VERSION ""

NS_ :

BS_:

BU_:

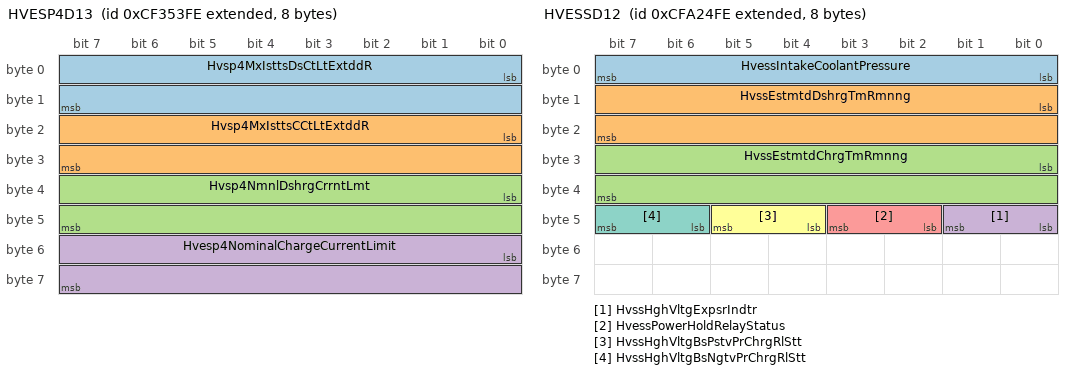
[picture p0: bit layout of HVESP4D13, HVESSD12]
BO_ 2364756990 HVESP4D13: 8 Vector__XXX
 SG_ Hvsp4MxIsttsDsCtLtExtddR : 0|16@1+ (0.125,-4000) [-4000|0] "A" Vector__XXX
 SG_ Hvsp4MxIsttsCCtLtExtddR : 16|16@1+ (0.125,-4000) [0|4031.875] "A" Vector__XXX
 SG_ Hvsp4NmnlDshrgCrrntLmt : 32|16@1+ (0.125,-4000) [-4000|0] "A" Vector__XXX
 SG_ Hvesp4NominalChargeCurrentLimit : 48|16@1+ (0.125,-4000) [0|4031.875] "A" Vector__XXX

BO_ 2364757246 HVESP5D12: 8 Vector__XXX
 SG_ Hvsp5AvllDshrgPwrExtnddRng : 0|16@1+ (0.25,0) [0|16063.75] "kW" Vector__XXX
 SG_ Hvsp5AvllChrgPwrExtnddRng : 16|16@1+ (0.25,0) [0|16063.75] "kW" Vector__XXX
 SG_ Hvesp5VoltageLevelExtendedRange : 32|16@1+ (0.125,0) [0|8031.875] "V" Vector__XXX
 SG_ Hvesp5CurrentExtendedRange : 48|16@1+ (0.125,-4000) [-4000|4031.875] "A" Vector__XXX

BO_ 2364757502 HVESP5D13: 8 Vector__XXX
 SG_ Hvsp5MxIsttsDsCtLtExtddR : 0|16@1+ (0.125,-4000) [-4000|0] "A" Vector__XXX
 SG_ Hvsp5MxIsttsCCtLtExtddR : 16|16@1+ (0.125,-4000) [0|4031.875] "A" Vector__XXX
 SG_ Hvsp5NmnlDshrgCrrntLmt : 32|16@1+ (0.125,-4000) [-4000|0] "A" Vector__XXX
 SG_ Hvesp5NominalChargeCurrentLimit : 48|16@1+ (0.125,-4000) [0|4031.875] "A" Vector__XXX

BO_ 2364757758 HVESP6D12: 8 Vector__XXX
 SG_ Hvsp6AvllDshrgPwrExtnddRng : 0|16@1+ (0.25,0) [0|16063.75] "kW" Vector__XXX
 SG_ Hvsp6AvllChrgPwrExtnddRng : 16|16@1+ (0.25,0) [0|16063.75] "kW" Vector__XXX
 SG_ Hvesp6VoltageLevelExtendedRange : 32|16@1+ (0.125,0) [0|8031.875] "V" Vector__XXX
 SG_ Hvesp6CurrentExtendedRange : 48|16@1+ (0.125,-4000) [-4000|4031.875] "A" Vector__XXX

BO_ 2364758014 HVESP6D13: 8 Vector__XXX
 SG_ Hvsp6MxIsttsDsCtLtExtddR : 0|16@1+ (0.125,-4000) [-4000|0] "A" Vector__XXX
 SG_ Hvsp6MxIsttsCCtLtExtddR : 16|16@1+ (0.125,-4000) [0|4031.875] "A" Vector__XXX
 SG_ Hvsp6NmnlDshrgCrrntLmt : 32|16@1+ (0.125,-4000) [-4000|0] "A" Vector__XXX
 SG_ Hvesp6NominalChargeCurrentLimit : 48|16@1+ (0.125,-4000) [0|4031.875] "A" Vector__XXX

BO_ 2364758270 HVESP7D12: 8 Vector__XXX
 SG_ Hvsp7AvllDshrgPwrExtnddRng : 0|16@1+ (0.25,0) [0|16063.75] "kW" Vector__XXX
 SG_ Hvsp7AvllChrgPwrExtnddRng : 16|16@1+ (0.25,0) [0|16063.75] "kW" Vector__XXX
 SG_ Hvesp7VoltageLevelExtendedRange : 32|16@1+ (0.125,0) [0|8031.875] "V" Vector__XXX
 SG_ Hvesp7CurrentExtendedRange : 48|16@1+ (0.125,-4000) [-4000|4031.875] "A" Vector__XXX

BO_ 2364758526 HVESP7D13: 8 Vector__XXX
 SG_ Hvsp7MxIsttsDsCtLtExtddR : 0|16@1+ (0.125,-4000) [-4000|0] "A" Vector__XXX
 SG_ Hvsp7MxIsttsCCtLtExtddR : 16|16@1+ (0.125,-4000) [0|4031.875] "A" Vector__XXX
 SG_ Hvsp7NmnlDshrgCrrntLmt : 32|16@1+ (0.125,-4000) [-4000|0] "A" Vector__XXX
 SG_ Hvesp7NominalChargeCurrentLimit : 48|16@1+ (0.125,-4000) [0|4031.875] "A" Vector__XXX

BO_ 2364758782 HVESP8D12: 8 Vector__XXX
 SG_ Hvsp8AvllDshrgPwrExtnddRng : 0|16@1+ (0.25,0) [0|16063.75] "kW" Vector__XXX
 SG_ Hvsp8AvllChrgPwrExtnddRng : 16|16@1+ (0.25,0) [0|16063.75] "kW" Vector__XXX
 SG_ Hvesp8VoltageLevelExtendedRange : 32|16@1+ (0.125,0) [0|8031.875] "V" Vector__XXX
 SG_ Hvesp8CurrentExtendedRange : 48|16@1+ (0.125,-4000) [-4000|4031.875] "A" Vector__XXX

BO_ 2364759038 HVESP8D13: 8 Vector__XXX
 SG_ Hvsp8MxIsttsDsCtLtExtddR : 0|16@1+ (0.125,-4000) [-4000|0] "A" Vector__XXX
 SG_ Hvsp8MxIsttsCCtLtExtddR : 16|16@1+ (0.125,-4000) [0|4031.875] "A" Vector__XXX
 SG_ Hvsp8NmnlDshrgCrrntLmt : 32|16@1+ (0.125,-4000) [-4000|0] "A" Vector__XXX
 SG_ Hvesp8NominalChargeCurrentLimit : 48|16@1+ (0.125,-4000) [0|4031.875] "A" Vector__XXX

BO_ 2364759294 HVESP9D12: 8 Vector__XXX
 SG_ Hvsp9AvllDshrgPwrExtnddRng : 0|16@1+ (0.25,0) [0|16063.75] "kW" Vector__XXX
 SG_ Hvsp9AvllChrgPwrExtnddRng : 16|16@1+ (0.25,0) [0|16063.75] "kW" Vector__XXX
 SG_ Hvesp9VoltageLevelExtendedRange : 32|16@1+ (0.125,0) [0|8031.875] "V" Vector__XXX
 SG_ Hvesp9CurrentExtendedRange : 48|16@1+ (0.125,-4000) [-4000|4031.875] "A" Vector__XXX

BO_ 2364759550 HVESP9D13: 8 Vector__XXX
 SG_ Hvsp9MxIsttsDsCtLtExtddR : 0|16@1+ (0.125,-4000) [-4000|0] "A" Vector__XXX
 SG_ Hvsp9MxIsttsCCtLtExtddR : 16|16@1+ (0.125,-4000) [0|4031.875] "A" Vector__XXX
 SG_ Hvsp9NmnlDshrgCrrntLmt : 32|16@1+ (0.125,-4000) [-4000|0] "A" Vector__XXX
 SG_ Hvesp9NominalChargeCurrentLimit : 48|16@1+ (0.125,-4000) [0|4031.875] "A" Vector__XXX

BO_ 2364759806 HVESP10D12: 8 Vector__XXX
 SG_ Hvsp10AvllDshrgPwrExtnddRng : 0|16@1+ (0.25,0) [0|16063.75] "kW" Vector__XXX
 SG_ Hvsp10AvllChrgPwrExtnddRng : 16|16@1+ (0.25,0) [0|16063.75] "kW" Vector__XXX
 SG_ Hvsp10VltgLvlExtnddRng : 32|16@1+ (0.125,0) [0|8031.875] "V" Vector__XXX
 SG_ Hvesp10CurrentExtendedRange : 48|16@1+ (0.125,-4000) [-4000|4031.875] "A" Vector__XXX

BO_ 2364760062 HVESP10D13: 8 Vector__XXX
 SG_ Hvsp10MxIsttsDsCtLtExtddR : 0|16@1+ (0.125,-4000) [-4000|0] "A" Vector__XXX
 SG_ Hvsp10MxIsttsCCtLtExtddR : 16|16@1+ (0.125,-4000) [0|4031.875] "A" Vector__XXX
 SG_ Hvsp10NmnlDshrgCrrntLmt : 32|16@1+ (0.125,-4000) [-4000|0] "A" Vector__XXX
 SG_ Hvsp10NmnlChrgCrrntLmt : 48|16@1+ (0.125,-4000) [0|4031.875] "A" Vector__XXX

BO_ 2364760318 HVESP11D12: 8 Vector__XXX
 SG_ Hvsp11AvllDshrgPwrExtnddRng : 0|16@1+ (0.25,0) [0|16063.75] "kW" Vector__XXX
 SG_ Hvsp11AvllChrgPwrExtnddRng : 16|16@1+ (0.25,0) [0|16063.75] "kW" Vector__XXX
 SG_ Hvsp11VltgLvlExtnddRng : 32|16@1+ (0.125,0) [0|8031.875] "V" Vector__XXX
 SG_ Hvesp11CurrentExtendedRange : 48|16@1+ (0.125,-4000) [-4000|4031.875] "A" Vector__XXX

BO_ 2364760574 HVESP11D13: 8 Vector__XXX
 SG_ Hvsp11MxIsttsDsCtLtExtddR : 0|16@1+ (0.125,-4000) [-4000|0] "A" Vector__XXX
 SG_ Hvsp11MxIsttsCCtLtExtddR : 16|16@1+ (0.125,-4000) [0|4031.875] "A" Vector__XXX
 SG_ Hvsp11NmnlDshrgCrrntLmt : 32|16@1+ (0.125,-4000) [-4000|0] "A" Vector__XXX
 SG_ Hvsp11NmnlChrgCrrntLmt : 48|16@1+ (0.125,-4000) [0|4031.875] "A" Vector__XXX

BO_ 2364760830 HVESP12D12: 8 Vector__XXX
 SG_ Hvsp12AvllDshrgPwrExtnddRng : 0|16@1+ (0.25,0) [0|16063.75] "kW" Vector__XXX
 SG_ Hvsp12AvllChrgPwrExtnddRng : 16|16@1+ (0.25,0) [0|16063.75] "kW" Vector__XXX
 SG_ Hvsp12VltgLvlExtnddRng : 32|16@1+ (0.125,0) [0|8031.875] "V" Vector__XXX
 SG_ Hvesp12CurrentExtendedRange : 48|16@1+ (0.125,-4000) [-4000|4031.875] "A" Vector__XXX

BO_ 2364761086 HVESP12D13: 8 Vector__XXX
 SG_ Hvsp12MxIsttsDsCtLtExtddR : 0|16@1+ (0.125,-4000) [-4000|0] "A" Vector__XXX
 SG_ Hvsp12MxIsttsCCtLtExtddR : 16|16@1+ (0.125,-4000) [0|4031.875] "A" Vector__XXX
 SG_ Hvsp12NmnlDshrgCrrntLmt : 32|16@1+ (0.125,-4000) [-4000|0] "A" Vector__XXX
 SG_ Hvsp12NmnlChrgCrrntLmt : 48|16@1+ (0.125,-4000) [0|4031.875] "A" Vector__XXX

BO_ 2365203710 HVESSD12: 8 Vector__XXX
 SG_ HvessIntakeCoolantPressure : 0|8@1+ (2,0) [0|500] "kPa" Vector__XXX
 SG_ HvssEstmtdDshrgTmRmnng : 8|16@1+ (0.1,0) [0|6425.5] "min" Vector__XXX
 SG_ HvssEstmtdChrgTmRmnng : 24|16@1+ (0.1,0) [0|6425.5] "min" Vector__XXX
 SG_ HvssHghVltgExpsrIndtr : 40|2@1+ (1,0) [0|3] "" Vector__XXX
 SG_ HvessPowerHoldRelayStatus : 42|2@1+ (1,0) [0|3] "" Vector__XXX
 SG_ HvssHghVltgBsPstvPrChrgRlStt : 44|2@1+ (1,0) [0|3] "" Vector__XXX
 SG_ HvssHghVltgBsNgtvPrChrgRlStt : 46|2@1+ (1,0) [0|3] "" Vector__XXX

BO_ 2365203966 HVESSD13: 8 Vector__XXX
 SG_ HvssAvllDshrgPwrExtnddRng : 0|16@1+ (0.25,0) [0|16063.75] "kW" Vector__XXX
 SG_ HvssAvllChrgPwrExtnddRng : 16|16@1+ (0.25,0) [0|16063.75] "kW" Vector__XXX
 SG_ HvessVoltageLevelExtendedRange : 32|16@1+ (0.125,0) [0|8031.875] "V" Vector__XXX
 SG_ HvessCurrentExtendedRange : 48|16@1+ (0.125,-4000) [-4000|4031.875] "A" Vector__XXX

BO_ 2365204222 HVESSD14: 8 Vector__XXX
 SG_ HvessBusVoltageExtendedRange : 32|16@1+ (0.125,0) [0|8031.875] "V" Vector__XXX
 SG_ HvssMxIsttsDsCtLtExtddR : 0|16@1+ (0.125,-4000) [-4000|0] "A" Vector__XXX
 SG_ HvssMxIsttsCCtLtExtddR : 16|16@1+ (0.125,-4000) [0|4031.875] "A" Vector__XXX
 SG_ HvssMnmmDshrgVltgLmt : 48|16@1+ (0.05,0) [0|3212.75] "V" Vector__XXX

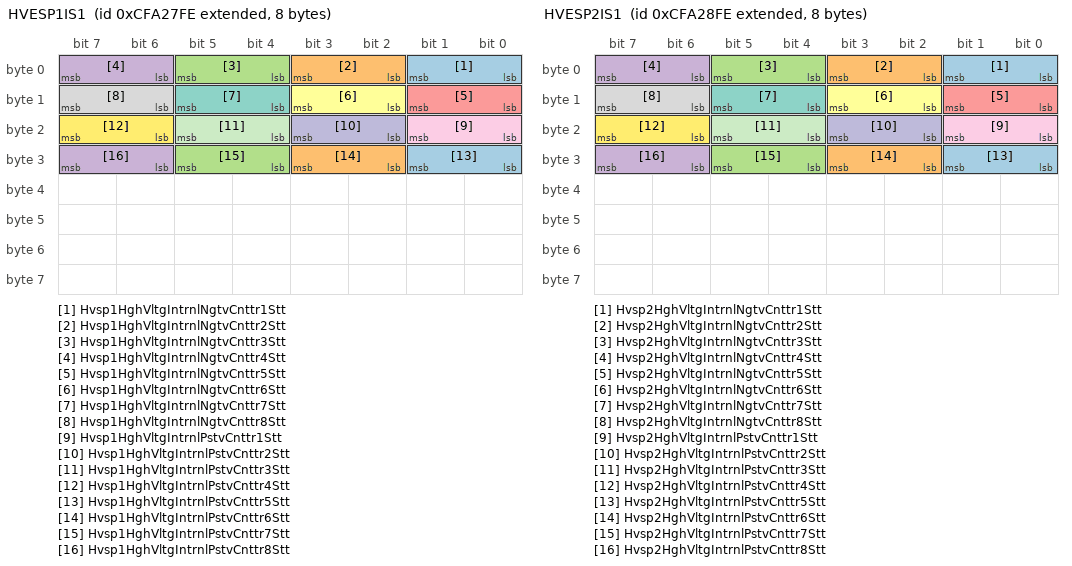
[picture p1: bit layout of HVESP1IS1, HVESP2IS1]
BO_ 2365204478 HVESP1IS1: 8 Vector__XXX
 SG_ Hvsp1HghVltgIntrnlNgtvCnttr1Stt : 0|2@1+ (1,0) [0|3] "" Vector__XXX
 SG_ Hvsp1HghVltgIntrnlNgtvCnttr2Stt : 2|2@1+ (1,0) [0|3] "" Vector__XXX
 SG_ Hvsp1HghVltgIntrnlNgtvCnttr3Stt : 4|2@1+ (1,0) [0|3] "" Vector__XXX
 SG_ Hvsp1HghVltgIntrnlNgtvCnttr4Stt : 6|2@1+ (1,0) [0|3] "" Vector__XXX
 SG_ Hvsp1HghVltgIntrnlNgtvCnttr5Stt : 8|2@1+ (1,0) [0|3] "" Vector__XXX
 SG_ Hvsp1HghVltgIntrnlNgtvCnttr6Stt : 10|2@1+ (1,0) [0|3] "" Vector__XXX
 SG_ Hvsp1HghVltgIntrnlNgtvCnttr7Stt : 12|2@1+ (1,0) [0|3] "" Vector__XXX
 SG_ Hvsp1HghVltgIntrnlNgtvCnttr8Stt : 14|2@1+ (1,0) [0|3] "" Vector__XXX
 SG_ Hvsp1HghVltgIntrnlPstvCnttr1Stt : 16|2@1+ (1,0) [0|3] "" Vector__XXX
 SG_ Hvsp1HghVltgIntrnlPstvCnttr2Stt : 18|2@1+ (1,0) [0|3] "" Vector__XXX
 SG_ Hvsp1HghVltgIntrnlPstvCnttr3Stt : 20|2@1+ (1,0) [0|3] "" Vector__XXX
 SG_ Hvsp1HghVltgIntrnlPstvCnttr4Stt : 22|2@1+ (1,0) [0|3] "" Vector__XXX
 SG_ Hvsp1HghVltgIntrnlPstvCnttr5Stt : 24|2@1+ (1,0) [0|3] "" Vector__XXX
 SG_ Hvsp1HghVltgIntrnlPstvCnttr6Stt : 26|2@1+ (1,0) [0|3] "" Vector__XXX
 SG_ Hvsp1HghVltgIntrnlPstvCnttr7Stt : 28|2@1+ (1,0) [0|3] "" Vector__XXX
 SG_ Hvsp1HghVltgIntrnlPstvCnttr8Stt : 30|2@1+ (1,0) [0|3] "" Vector__XXX

BO_ 2365204734 HVESP2IS1: 8 Vector__XXX
 SG_ Hvsp2HghVltgIntrnlNgtvCnttr1Stt : 0|2@1+ (1,0) [0|3] "" Vector__XXX
 SG_ Hvsp2HghVltgIntrnlNgtvCnttr2Stt : 2|2@1+ (1,0) [0|3] "" Vector__XXX
 SG_ Hvsp2HghVltgIntrnlNgtvCnttr3Stt : 4|2@1+ (1,0) [0|3] "" Vector__XXX
 SG_ Hvsp2HghVltgIntrnlNgtvCnttr4Stt : 6|2@1+ (1,0) [0|3] "" Vector__XXX
 SG_ Hvsp2HghVltgIntrnlNgtvCnttr5Stt : 8|2@1+ (1,0) [0|3] "" Vector__XXX
 SG_ Hvsp2HghVltgIntrnlNgtvCnttr6Stt : 10|2@1+ (1,0) [0|3] "" Vector__XXX
 SG_ Hvsp2HghVltgIntrnlNgtvCnttr7Stt : 12|2@1+ (1,0) [0|3] "" Vector__XXX
 SG_ Hvsp2HghVltgIntrnlNgtvCnttr8Stt : 14|2@1+ (1,0) [0|3] "" Vector__XXX
 SG_ Hvsp2HghVltgIntrnlPstvCnttr1Stt : 16|2@1+ (1,0) [0|3] "" Vector__XXX
 SG_ Hvsp2HghVltgIntrnlPstvCnttr2Stt : 18|2@1+ (1,0) [0|3] "" Vector__XXX
 SG_ Hvsp2HghVltgIntrnlPstvCnttr3Stt : 20|2@1+ (1,0) [0|3] "" Vector__XXX
 SG_ Hvsp2HghVltgIntrnlPstvCnttr4Stt : 22|2@1+ (1,0) [0|3] "" Vector__XXX
 SG_ Hvsp2HghVltgIntrnlPstvCnttr5Stt : 24|2@1+ (1,0) [0|3] "" Vector__XXX
 SG_ Hvsp2HghVltgIntrnlPstvCnttr6Stt : 26|2@1+ (1,0) [0|3] "" Vector__XXX
 SG_ Hvsp2HghVltgIntrnlPstvCnttr7Stt : 28|2@1+ (1,0) [0|3] "" Vector__XXX
 SG_ Hvsp2HghVltgIntrnlPstvCnttr8Stt : 30|2@1+ (1,0) [0|3] "" Vector__XXX

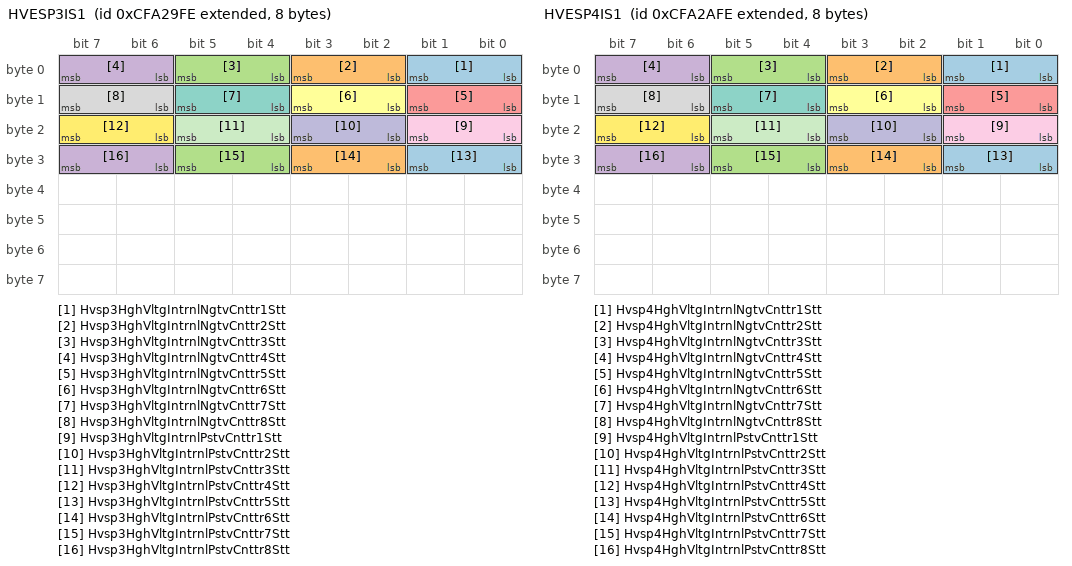
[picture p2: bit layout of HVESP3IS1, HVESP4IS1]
BO_ 2365204990 HVESP3IS1: 8 Vector__XXX
 SG_ Hvsp3HghVltgIntrnlNgtvCnttr1Stt : 0|2@1+ (1,0) [0|3] "" Vector__XXX
 SG_ Hvsp3HghVltgIntrnlNgtvCnttr2Stt : 2|2@1+ (1,0) [0|3] "" Vector__XXX
 SG_ Hvsp3HghVltgIntrnlNgtvCnttr3Stt : 4|2@1+ (1,0) [0|3] "" Vector__XXX
 SG_ Hvsp3HghVltgIntrnlNgtvCnttr4Stt : 6|2@1+ (1,0) [0|3] "" Vector__XXX
 SG_ Hvsp3HghVltgIntrnlNgtvCnttr5Stt : 8|2@1+ (1,0) [0|3] "" Vector__XXX
 SG_ Hvsp3HghVltgIntrnlNgtvCnttr6Stt : 10|2@1+ (1,0) [0|3] "" Vector__XXX
 SG_ Hvsp3HghVltgIntrnlNgtvCnttr7Stt : 12|2@1+ (1,0) [0|3] "" Vector__XXX
 SG_ Hvsp3HghVltgIntrnlNgtvCnttr8Stt : 14|2@1+ (1,0) [0|3] "" Vector__XXX
 SG_ Hvsp3HghVltgIntrnlPstvCnttr1Stt : 16|2@1+ (1,0) [0|3] "" Vector__XXX
 SG_ Hvsp3HghVltgIntrnlPstvCnttr2Stt : 18|2@1+ (1,0) [0|3] "" Vector__XXX
 SG_ Hvsp3HghVltgIntrnlPstvCnttr3Stt : 20|2@1+ (1,0) [0|3] "" Vector__XXX
 SG_ Hvsp3HghVltgIntrnlPstvCnttr4Stt : 22|2@1+ (1,0) [0|3] "" Vector__XXX
 SG_ Hvsp3HghVltgIntrnlPstvCnttr5Stt : 24|2@1+ (1,0) [0|3] "" Vector__XXX
 SG_ Hvsp3HghVltgIntrnlPstvCnttr6Stt : 26|2@1+ (1,0) [0|3] "" Vector__XXX
 SG_ Hvsp3HghVltgIntrnlPstvCnttr7Stt : 28|2@1+ (1,0) [0|3] "" Vector__XXX
 SG_ Hvsp3HghVltgIntrnlPstvCnttr8Stt : 30|2@1+ (1,0) [0|3] "" Vector__XXX

BO_ 2365205246 HVESP4IS1: 8 Vector__XXX
 SG_ Hvsp4HghVltgIntrnlNgtvCnttr1Stt : 0|2@1+ (1,0) [0|3] "" Vector__XXX
 SG_ Hvsp4HghVltgIntrnlNgtvCnttr2Stt : 2|2@1+ (1,0) [0|3] "" Vector__XXX
 SG_ Hvsp4HghVltgIntrnlNgtvCnttr3Stt : 4|2@1+ (1,0) [0|3] "" Vector__XXX
 SG_ Hvsp4HghVltgIntrnlNgtvCnttr4Stt : 6|2@1+ (1,0) [0|3] "" Vector__XXX
 SG_ Hvsp4HghVltgIntrnlNgtvCnttr5Stt : 8|2@1+ (1,0) [0|3] "" Vector__XXX
 SG_ Hvsp4HghVltgIntrnlNgtvCnttr6Stt : 10|2@1+ (1,0) [0|3] "" Vector__XXX
 SG_ Hvsp4HghVltgIntrnlNgtvCnttr7Stt : 12|2@1+ (1,0) [0|3] "" Vector__XXX
 SG_ Hvsp4HghVltgIntrnlNgtvCnttr8Stt : 14|2@1+ (1,0) [0|3] "" Vector__XXX
 SG_ Hvsp4HghVltgIntrnlPstvCnttr1Stt : 16|2@1+ (1,0) [0|3] "" Vector__XXX
 SG_ Hvsp4HghVltgIntrnlPstvCnttr2Stt : 18|2@1+ (1,0) [0|3] "" Vector__XXX
 SG_ Hvsp4HghVltgIntrnlPstvCnttr3Stt : 20|2@1+ (1,0) [0|3] "" Vector__XXX
 SG_ Hvsp4HghVltgIntrnlPstvCnttr4Stt : 22|2@1+ (1,0) [0|3] "" Vector__XXX
 SG_ Hvsp4HghVltgIntrnlPstvCnttr5Stt : 24|2@1+ (1,0) [0|3] "" Vector__XXX
 SG_ Hvsp4HghVltgIntrnlPstvCnttr6Stt : 26|2@1+ (1,0) [0|3] "" Vector__XXX
 SG_ Hvsp4HghVltgIntrnlPstvCnttr7Stt : 28|2@1+ (1,0) [0|3] "" Vector__XXX
 SG_ Hvsp4HghVltgIntrnlPstvCnttr8Stt : 30|2@1+ (1,0) [0|3] "" Vector__XXX

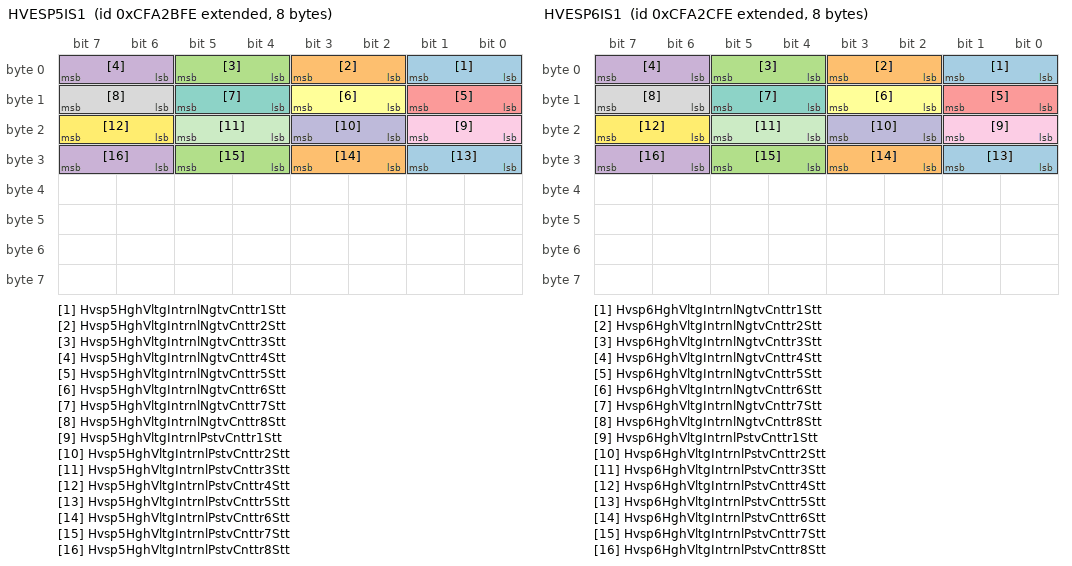
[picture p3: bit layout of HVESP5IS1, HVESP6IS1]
BO_ 2365205502 HVESP5IS1: 8 Vector__XXX
 SG_ Hvsp5HghVltgIntrnlNgtvCnttr1Stt : 0|2@1+ (1,0) [0|3] "" Vector__XXX
 SG_ Hvsp5HghVltgIntrnlNgtvCnttr2Stt : 2|2@1+ (1,0) [0|3] "" Vector__XXX
 SG_ Hvsp5HghVltgIntrnlNgtvCnttr3Stt : 4|2@1+ (1,0) [0|3] "" Vector__XXX
 SG_ Hvsp5HghVltgIntrnlNgtvCnttr4Stt : 6|2@1+ (1,0) [0|3] "" Vector__XXX
 SG_ Hvsp5HghVltgIntrnlNgtvCnttr5Stt : 8|2@1+ (1,0) [0|3] "" Vector__XXX
 SG_ Hvsp5HghVltgIntrnlNgtvCnttr6Stt : 10|2@1+ (1,0) [0|3] "" Vector__XXX
 SG_ Hvsp5HghVltgIntrnlNgtvCnttr7Stt : 12|2@1+ (1,0) [0|3] "" Vector__XXX
 SG_ Hvsp5HghVltgIntrnlNgtvCnttr8Stt : 14|2@1+ (1,0) [0|3] "" Vector__XXX
 SG_ Hvsp5HghVltgIntrnlPstvCnttr1Stt : 16|2@1+ (1,0) [0|3] "" Vector__XXX
 SG_ Hvsp5HghVltgIntrnlPstvCnttr2Stt : 18|2@1+ (1,0) [0|3] "" Vector__XXX
 SG_ Hvsp5HghVltgIntrnlPstvCnttr3Stt : 20|2@1+ (1,0) [0|3] "" Vector__XXX
 SG_ Hvsp5HghVltgIntrnlPstvCnttr4Stt : 22|2@1+ (1,0) [0|3] "" Vector__XXX
 SG_ Hvsp5HghVltgIntrnlPstvCnttr5Stt : 24|2@1+ (1,0) [0|3] "" Vector__XXX
 SG_ Hvsp5HghVltgIntrnlPstvCnttr6Stt : 26|2@1+ (1,0) [0|3] "" Vector__XXX
 SG_ Hvsp5HghVltgIntrnlPstvCnttr7Stt : 28|2@1+ (1,0) [0|3] "" Vector__XXX
 SG_ Hvsp5HghVltgIntrnlPstvCnttr8Stt : 30|2@1+ (1,0) [0|3] "" Vector__XXX

BO_ 2365205758 HVESP6IS1: 8 Vector__XXX
 SG_ Hvsp6HghVltgIntrnlNgtvCnttr1Stt : 0|2@1+ (1,0) [0|3] "" Vector__XXX
 SG_ Hvsp6HghVltgIntrnlNgtvCnttr2Stt : 2|2@1+ (1,0) [0|3] "" Vector__XXX
 SG_ Hvsp6HghVltgIntrnlNgtvCnttr3Stt : 4|2@1+ (1,0) [0|3] "" Vector__XXX
 SG_ Hvsp6HghVltgIntrnlNgtvCnttr4Stt : 6|2@1+ (1,0) [0|3] "" Vector__XXX
 SG_ Hvsp6HghVltgIntrnlNgtvCnttr5Stt : 8|2@1+ (1,0) [0|3] "" Vector__XXX
 SG_ Hvsp6HghVltgIntrnlNgtvCnttr6Stt : 10|2@1+ (1,0) [0|3] "" Vector__XXX
 SG_ Hvsp6HghVltgIntrnlNgtvCnttr7Stt : 12|2@1+ (1,0) [0|3] "" Vector__XXX
 SG_ Hvsp6HghVltgIntrnlNgtvCnttr8Stt : 14|2@1+ (1,0) [0|3] "" Vector__XXX
 SG_ Hvsp6HghVltgIntrnlPstvCnttr1Stt : 16|2@1+ (1,0) [0|3] "" Vector__XXX
 SG_ Hvsp6HghVltgIntrnlPstvCnttr2Stt : 18|2@1+ (1,0) [0|3] "" Vector__XXX
 SG_ Hvsp6HghVltgIntrnlPstvCnttr3Stt : 20|2@1+ (1,0) [0|3] "" Vector__XXX
 SG_ Hvsp6HghVltgIntrnlPstvCnttr4Stt : 22|2@1+ (1,0) [0|3] "" Vector__XXX
 SG_ Hvsp6HghVltgIntrnlPstvCnttr5Stt : 24|2@1+ (1,0) [0|3] "" Vector__XXX
 SG_ Hvsp6HghVltgIntrnlPstvCnttr6Stt : 26|2@1+ (1,0) [0|3] "" Vector__XXX
 SG_ Hvsp6HghVltgIntrnlPstvCnttr7Stt : 28|2@1+ (1,0) [0|3] "" Vector__XXX
 SG_ Hvsp6HghVltgIntrnlPstvCnttr8Stt : 30|2@1+ (1,0) [0|3] "" Vector__XXX

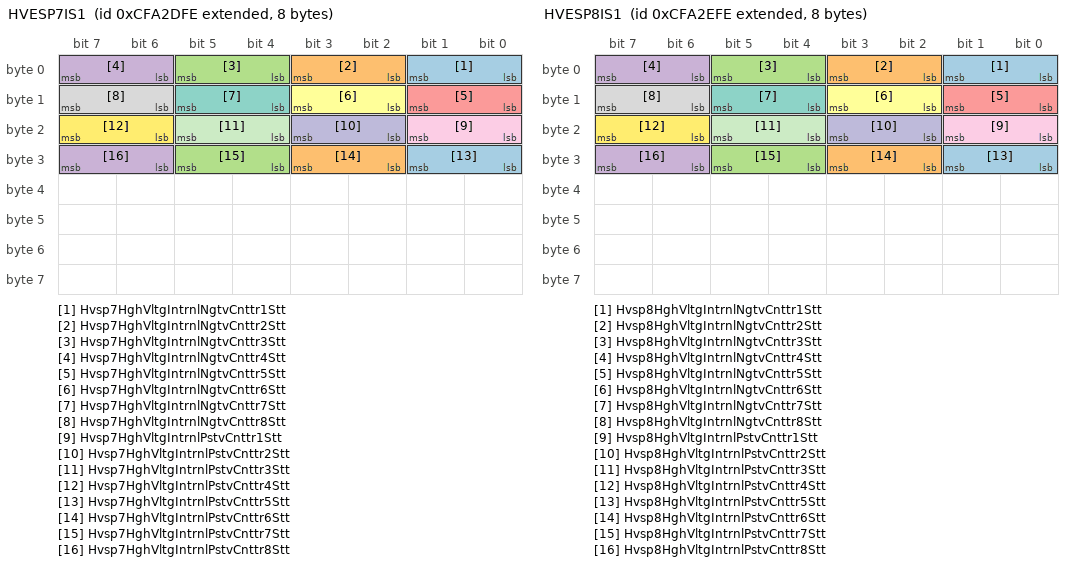
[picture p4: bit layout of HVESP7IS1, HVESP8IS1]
BO_ 2365206014 HVESP7IS1: 8 Vector__XXX
 SG_ Hvsp7HghVltgIntrnlNgtvCnttr1Stt : 0|2@1+ (1,0) [0|3] "" Vector__XXX
 SG_ Hvsp7HghVltgIntrnlNgtvCnttr2Stt : 2|2@1+ (1,0) [0|3] "" Vector__XXX
 SG_ Hvsp7HghVltgIntrnlNgtvCnttr3Stt : 4|2@1+ (1,0) [0|3] "" Vector__XXX
 SG_ Hvsp7HghVltgIntrnlNgtvCnttr4Stt : 6|2@1+ (1,0) [0|3] "" Vector__XXX
 SG_ Hvsp7HghVltgIntrnlNgtvCnttr5Stt : 8|2@1+ (1,0) [0|3] "" Vector__XXX
 SG_ Hvsp7HghVltgIntrnlNgtvCnttr6Stt : 10|2@1+ (1,0) [0|3] "" Vector__XXX
 SG_ Hvsp7HghVltgIntrnlNgtvCnttr7Stt : 12|2@1+ (1,0) [0|3] "" Vector__XXX
 SG_ Hvsp7HghVltgIntrnlNgtvCnttr8Stt : 14|2@1+ (1,0) [0|3] "" Vector__XXX
 SG_ Hvsp7HghVltgIntrnlPstvCnttr1Stt : 16|2@1+ (1,0) [0|3] "" Vector__XXX
 SG_ Hvsp7HghVltgIntrnlPstvCnttr2Stt : 18|2@1+ (1,0) [0|3] "" Vector__XXX
 SG_ Hvsp7HghVltgIntrnlPstvCnttr3Stt : 20|2@1+ (1,0) [0|3] "" Vector__XXX
 SG_ Hvsp7HghVltgIntrnlPstvCnttr4Stt : 22|2@1+ (1,0) [0|3] "" Vector__XXX
 SG_ Hvsp7HghVltgIntrnlPstvCnttr5Stt : 24|2@1+ (1,0) [0|3] "" Vector__XXX
 SG_ Hvsp7HghVltgIntrnlPstvCnttr6Stt : 26|2@1+ (1,0) [0|3] "" Vector__XXX
 SG_ Hvsp7HghVltgIntrnlPstvCnttr7Stt : 28|2@1+ (1,0) [0|3] "" Vector__XXX
 SG_ Hvsp7HghVltgIntrnlPstvCnttr8Stt : 30|2@1+ (1,0) [0|3] "" Vector__XXX

BO_ 2365206270 HVESP8IS1: 8 Vector__XXX
 SG_ Hvsp8HghVltgIntrnlNgtvCnttr1Stt : 0|2@1+ (1,0) [0|3] "" Vector__XXX
 SG_ Hvsp8HghVltgIntrnlNgtvCnttr2Stt : 2|2@1+ (1,0) [0|3] "" Vector__XXX
 SG_ Hvsp8HghVltgIntrnlNgtvCnttr3Stt : 4|2@1+ (1,0) [0|3] "" Vector__XXX
 SG_ Hvsp8HghVltgIntrnlNgtvCnttr4Stt : 6|2@1+ (1,0) [0|3] "" Vector__XXX
 SG_ Hvsp8HghVltgIntrnlNgtvCnttr5Stt : 8|2@1+ (1,0) [0|3] "" Vector__XXX
 SG_ Hvsp8HghVltgIntrnlNgtvCnttr6Stt : 10|2@1+ (1,0) [0|3] "" Vector__XXX
 SG_ Hvsp8HghVltgIntrnlNgtvCnttr7Stt : 12|2@1+ (1,0) [0|3] "" Vector__XXX
 SG_ Hvsp8HghVltgIntrnlNgtvCnttr8Stt : 14|2@1+ (1,0) [0|3] "" Vector__XXX
 SG_ Hvsp8HghVltgIntrnlPstvCnttr1Stt : 16|2@1+ (1,0) [0|3] "" Vector__XXX
 SG_ Hvsp8HghVltgIntrnlPstvCnttr2Stt : 18|2@1+ (1,0) [0|3] "" Vector__XXX
 SG_ Hvsp8HghVltgIntrnlPstvCnttr3Stt : 20|2@1+ (1,0) [0|3] "" Vector__XXX
 SG_ Hvsp8HghVltgIntrnlPstvCnttr4Stt : 22|2@1+ (1,0) [0|3] "" Vector__XXX
 SG_ Hvsp8HghVltgIntrnlPstvCnttr5Stt : 24|2@1+ (1,0) [0|3] "" Vector__XXX
 SG_ Hvsp8HghVltgIntrnlPstvCnttr6Stt : 26|2@1+ (1,0) [0|3] "" Vector__XXX
 SG_ Hvsp8HghVltgIntrnlPstvCnttr7Stt : 28|2@1+ (1,0) [0|3] "" Vector__XXX
 SG_ Hvsp8HghVltgIntrnlPstvCnttr8Stt : 30|2@1+ (1,0) [0|3] "" Vector__XXX

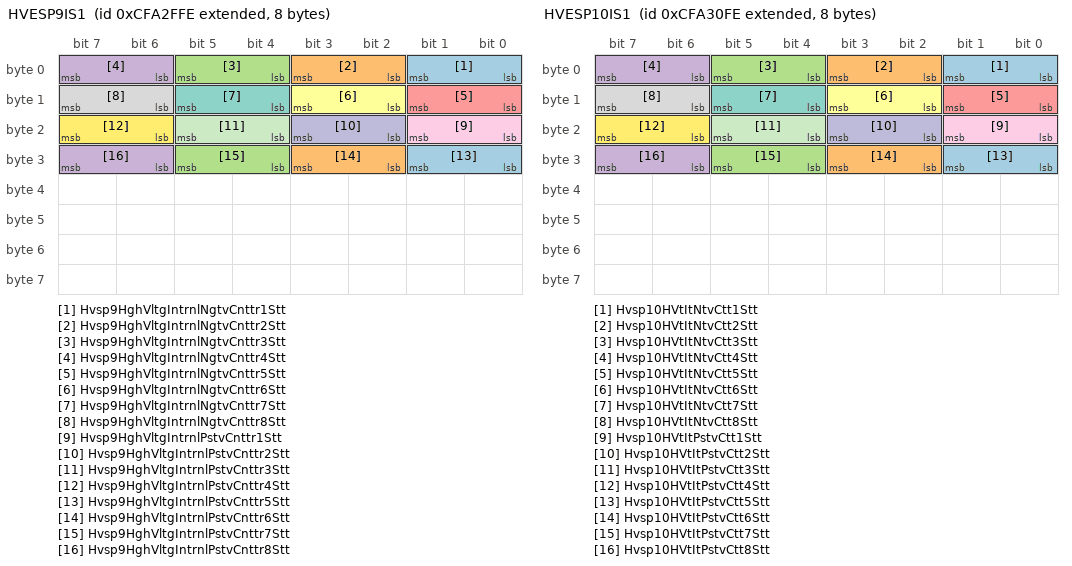
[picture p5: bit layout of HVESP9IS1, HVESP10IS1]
BO_ 2365206526 HVESP9IS1: 8 Vector__XXX
 SG_ Hvsp9HghVltgIntrnlNgtvCnttr1Stt : 0|2@1+ (1,0) [0|3] "" Vector__XXX
 SG_ Hvsp9HghVltgIntrnlNgtvCnttr2Stt : 2|2@1+ (1,0) [0|3] "" Vector__XXX
 SG_ Hvsp9HghVltgIntrnlNgtvCnttr3Stt : 4|2@1+ (1,0) [0|3] "" Vector__XXX
 SG_ Hvsp9HghVltgIntrnlNgtvCnttr4Stt : 6|2@1+ (1,0) [0|3] "" Vector__XXX
 SG_ Hvsp9HghVltgIntrnlNgtvCnttr5Stt : 8|2@1+ (1,0) [0|3] "" Vector__XXX
 SG_ Hvsp9HghVltgIntrnlNgtvCnttr6Stt : 10|2@1+ (1,0) [0|3] "" Vector__XXX
 SG_ Hvsp9HghVltgIntrnlNgtvCnttr7Stt : 12|2@1+ (1,0) [0|3] "" Vector__XXX
 SG_ Hvsp9HghVltgIntrnlNgtvCnttr8Stt : 14|2@1+ (1,0) [0|3] "" Vector__XXX
 SG_ Hvsp9HghVltgIntrnlPstvCnttr1Stt : 16|2@1+ (1,0) [0|3] "" Vector__XXX
 SG_ Hvsp9HghVltgIntrnlPstvCnttr2Stt : 18|2@1+ (1,0) [0|3] "" Vector__XXX
 SG_ Hvsp9HghVltgIntrnlPstvCnttr3Stt : 20|2@1+ (1,0) [0|3] "" Vector__XXX
 SG_ Hvsp9HghVltgIntrnlPstvCnttr4Stt : 22|2@1+ (1,0) [0|3] "" Vector__XXX
 SG_ Hvsp9HghVltgIntrnlPstvCnttr5Stt : 24|2@1+ (1,0) [0|3] "" Vector__XXX
 SG_ Hvsp9HghVltgIntrnlPstvCnttr6Stt : 26|2@1+ (1,0) [0|3] "" Vector__XXX
 SG_ Hvsp9HghVltgIntrnlPstvCnttr7Stt : 28|2@1+ (1,0) [0|3] "" Vector__XXX
 SG_ Hvsp9HghVltgIntrnlPstvCnttr8Stt : 30|2@1+ (1,0) [0|3] "" Vector__XXX

BO_ 2365206782 HVESP10IS1: 8 Vector__XXX
 SG_ Hvsp10HVtItNtvCtt1Stt : 0|2@1+ (1,0) [0|3] "" Vector__XXX
 SG_ Hvsp10HVtItNtvCtt2Stt : 2|2@1+ (1,0) [0|3] "" Vector__XXX
 SG_ Hvsp10HVtItNtvCtt3Stt : 4|2@1+ (1,0) [0|3] "" Vector__XXX
 SG_ Hvsp10HVtItNtvCtt4Stt : 6|2@1+ (1,0) [0|3] "" Vector__XXX
 SG_ Hvsp10HVtItNtvCtt5Stt : 8|2@1+ (1,0) [0|3] "" Vector__XXX
 SG_ Hvsp10HVtItNtvCtt6Stt : 10|2@1+ (1,0) [0|3] "" Vector__XXX
 SG_ Hvsp10HVtItNtvCtt7Stt : 12|2@1+ (1,0) [0|3] "" Vector__XXX
 SG_ Hvsp10HVtItNtvCtt8Stt : 14|2@1+ (1,0) [0|3] "" Vector__XXX
 SG_ Hvsp10HVtItPstvCtt1Stt : 16|2@1+ (1,0) [0|3] "" Vector__XXX
 SG_ Hvsp10HVtItPstvCtt2Stt : 18|2@1+ (1,0) [0|3] "" Vector__XXX
 SG_ Hvsp10HVtItPstvCtt3Stt : 20|2@1+ (1,0) [0|3] "" Vector__XXX
 SG_ Hvsp10HVtItPstvCtt4Stt : 22|2@1+ (1,0) [0|3] "" Vector__XXX
 SG_ Hvsp10HVtItPstvCtt5Stt : 24|2@1+ (1,0) [0|3] "" Vector__XXX
 SG_ Hvsp10HVtItPstvCtt6Stt : 26|2@1+ (1,0) [0|3] "" Vector__XXX
 SG_ Hvsp10HVtItPstvCtt7Stt : 28|2@1+ (1,0) [0|3] "" Vector__XXX
 SG_ Hvsp10HVtItPstvCtt8Stt : 30|2@1+ (1,0) [0|3] "" Vector__XXX

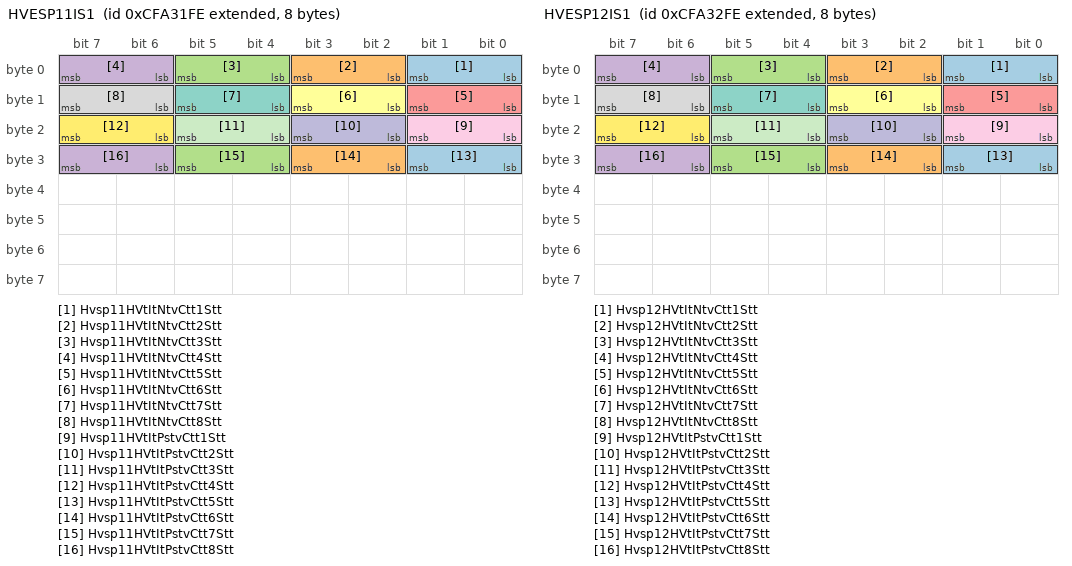
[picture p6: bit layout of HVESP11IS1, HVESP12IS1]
BO_ 2365207038 HVESP11IS1: 8 Vector__XXX
 SG_ Hvsp11HVtItNtvCtt1Stt : 0|2@1+ (1,0) [0|3] "" Vector__XXX
 SG_ Hvsp11HVtItNtvCtt2Stt : 2|2@1+ (1,0) [0|3] "" Vector__XXX
 SG_ Hvsp11HVtItNtvCtt3Stt : 4|2@1+ (1,0) [0|3] "" Vector__XXX
 SG_ Hvsp11HVtItNtvCtt4Stt : 6|2@1+ (1,0) [0|3] "" Vector__XXX
 SG_ Hvsp11HVtItNtvCtt5Stt : 8|2@1+ (1,0) [0|3] "" Vector__XXX
 SG_ Hvsp11HVtItNtvCtt6Stt : 10|2@1+ (1,0) [0|3] "" Vector__XXX
 SG_ Hvsp11HVtItNtvCtt7Stt : 12|2@1+ (1,0) [0|3] "" Vector__XXX
 SG_ Hvsp11HVtItNtvCtt8Stt : 14|2@1+ (1,0) [0|3] "" Vector__XXX
 SG_ Hvsp11HVtItPstvCtt1Stt : 16|2@1+ (1,0) [0|3] "" Vector__XXX
 SG_ Hvsp11HVtItPstvCtt2Stt : 18|2@1+ (1,0) [0|3] "" Vector__XXX
 SG_ Hvsp11HVtItPstvCtt3Stt : 20|2@1+ (1,0) [0|3] "" Vector__XXX
 SG_ Hvsp11HVtItPstvCtt4Stt : 22|2@1+ (1,0) [0|3] "" Vector__XXX
 SG_ Hvsp11HVtItPstvCtt5Stt : 24|2@1+ (1,0) [0|3] "" Vector__XXX
 SG_ Hvsp11HVtItPstvCtt6Stt : 26|2@1+ (1,0) [0|3] "" Vector__XXX
 SG_ Hvsp11HVtItPstvCtt7Stt : 28|2@1+ (1,0) [0|3] "" Vector__XXX
 SG_ Hvsp11HVtItPstvCtt8Stt : 30|2@1+ (1,0) [0|3] "" Vector__XXX

BO_ 2365207294 HVESP12IS1: 8 Vector__XXX
 SG_ Hvsp12HVtItNtvCtt1Stt : 0|2@1+ (1,0) [0|3] "" Vector__XXX
 SG_ Hvsp12HVtItNtvCtt2Stt : 2|2@1+ (1,0) [0|3] "" Vector__XXX
 SG_ Hvsp12HVtItNtvCtt3Stt : 4|2@1+ (1,0) [0|3] "" Vector__XXX
 SG_ Hvsp12HVtItNtvCtt4Stt : 6|2@1+ (1,0) [0|3] "" Vector__XXX
 SG_ Hvsp12HVtItNtvCtt5Stt : 8|2@1+ (1,0) [0|3] "" Vector__XXX
 SG_ Hvsp12HVtItNtvCtt6Stt : 10|2@1+ (1,0) [0|3] "" Vector__XXX
 SG_ Hvsp12HVtItNtvCtt7Stt : 12|2@1+ (1,0) [0|3] "" Vector__XXX
 SG_ Hvsp12HVtItNtvCtt8Stt : 14|2@1+ (1,0) [0|3] "" Vector__XXX
 SG_ Hvsp12HVtItPstvCtt1Stt : 16|2@1+ (1,0) [0|3] "" Vector__XXX
 SG_ Hvsp12HVtItPstvCtt2Stt : 18|2@1+ (1,0) [0|3] "" Vector__XXX
 SG_ Hvsp12HVtItPstvCtt3Stt : 20|2@1+ (1,0) [0|3] "" Vector__XXX
 SG_ Hvsp12HVtItPstvCtt4Stt : 22|2@1+ (1,0) [0|3] "" Vector__XXX
 SG_ Hvsp12HVtItPstvCtt5Stt : 24|2@1+ (1,0) [0|3] "" Vector__XXX
 SG_ Hvsp12HVtItPstvCtt6Stt : 26|2@1+ (1,0) [0|3] "" Vector__XXX
 SG_ Hvsp12HVtItPstvCtt7Stt : 28|2@1+ (1,0) [0|3] "" Vector__XXX
 SG_ Hvsp12HVtItPstvCtt8Stt : 30|2@1+ (1,0) [0|3] "" Vector__XXX

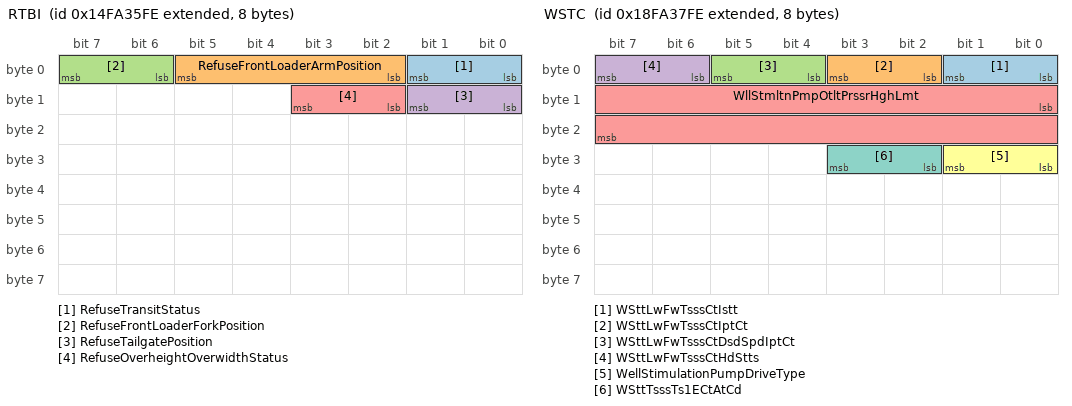
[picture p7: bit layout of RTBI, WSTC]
BO_ 2499425790 RTBI: 8 Vector__XXX
 SG_ RefuseTransitStatus : 0|2@1+ (1,0) [0|3] "" Vector__XXX
 SG_ RefuseFrontLoaderArmPosition : 2|4@1+ (1,0) [0|15] "" Vector__XXX
 SG_ RefuseFrontLoaderForkPosition : 6|2@1+ (1,0) [0|3] "" Vector__XXX
 SG_ RefuseTailgatePosition : 8|2@1+ (1,0) [0|3] "" Vector__XXX
 SG_ RefuseOverheightOverwidthStatus : 10|2@1+ (1,0) [0|3] "" Vector__XXX

BO_ 2566534910 EFLP14: 8 Vector__XXX
 SG_ EngnThrttlVlv1OtltPrssr : 0|16@1+ (0.1,0) [0|6425.5] "kPa" Vector__XXX
 SG_ EngnThrttlVlv1OtltAsltPrssr : 16|16@1+ (0.1,0) [0|6425.5] "kPa" Vector__XXX
 SG_ EngnThrttlVlv2OtltPrssr : 32|16@1+ (0.1,0) [0|6425.5] "kPa" Vector__XXX
 SG_ EngnThrttlVlv2OtltAsltPrssr : 48|16@1+ (0.1,0) [0|6425.5] "kPa" Vector__XXX

BO_ 2566535166 WSTC: 8 Vector__XXX
 SG_ WSttLwFwTsssCtIstt : 0|2@1+ (1,0) [0|3] "" Vector__XXX
 SG_ WSttLwFwTsssCtIptCt : 2|2@1+ (1,0) [0|3] "" Vector__XXX
 SG_ WSttLwFwTsssCtDsdSpdIptCt : 4|2@1+ (1,0) [0|3] "" Vector__XXX
 SG_ WSttLwFwTsssCtHdStts : 6|2@1+ (1,0) [0|3] "" Vector__XXX
 SG_ WllStmltnPmpOtltPrssrHghLmt : 8|16@1+ (5,0) [0|321275] "kPa" Vector__XXX
 SG_ WellStimulationPumpDriveType : 24|2@1+ (1,0) [0|3] "" Vector__XXX
 SG_ WSttTsssTs1ECtAtCd : 26|2@1+ (1,0) [0|3] "" Vector__XXX

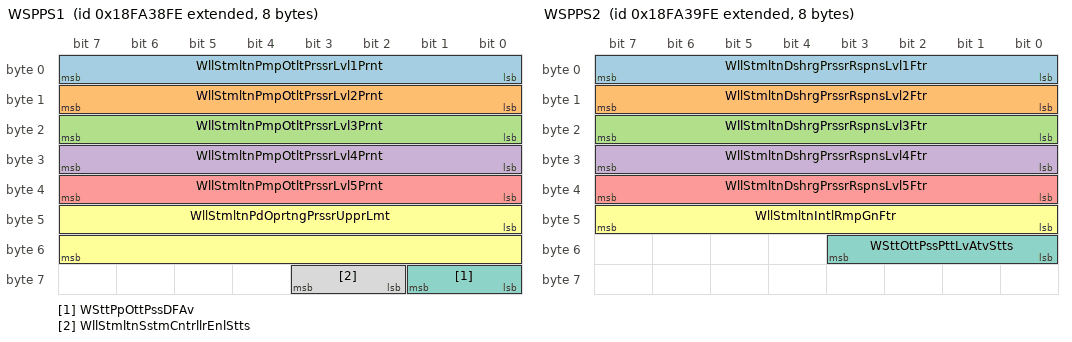
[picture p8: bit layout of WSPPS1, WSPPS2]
BO_ 2566535422 WSPPS1: 8 Vector__XXX
 SG_ WllStmltnPmpOtltPrssrLvl1Prnt : 0|8@1+ (0.5,0) [0|125] "%" Vector__XXX
 SG_ WllStmltnPmpOtltPrssrLvl2Prnt : 8|8@1+ (0.5,0) [0|125] "%" Vector__XXX
 SG_ WllStmltnPmpOtltPrssrLvl3Prnt : 16|8@1+ (0.5,0) [0|125] "%" Vector__XXX
 SG_ WllStmltnPmpOtltPrssrLvl4Prnt : 24|8@1+ (0.5,0) [0|125] "%" Vector__XXX
 SG_ WllStmltnPmpOtltPrssrLvl5Prnt : 32|8@1+ (0.5,0) [0|125] "%" Vector__XXX
 SG_ WllStmltnPdOprtngPrssrUpprLmt : 40|16@1+ (5,0) [0|321275] "kPa" Vector__XXX
 SG_ WSttPpOttPssDFAv : 56|2@1+ (1,0) [0|3] "" Vector__XXX
 SG_ WllStmltnSstmCntrllrEnlStts : 58|2@1+ (1,0) [0|3] "" Vector__XXX

BO_ 2566535678 WSPPS2: 8 Vector__XXX
 SG_ WllStmltnDshrgPrssrRspnsLvl1Ftr : 0|8@1+ (0.5,0) [0|125] "%" Vector__XXX
 SG_ WllStmltnDshrgPrssrRspnsLvl2Ftr : 8|8@1+ (0.5,0) [0|125] "%" Vector__XXX
 SG_ WllStmltnDshrgPrssrRspnsLvl3Ftr : 16|8@1+ (0.5,0) [0|125] "%" Vector__XXX
 SG_ WllStmltnDshrgPrssrRspnsLvl4Ftr : 24|8@1+ (0.5,0) [0|125] "%" Vector__XXX
 SG_ WllStmltnDshrgPrssrRspnsLvl5Ftr : 32|8@1+ (0.5,0) [0|125] "%" Vector__XXX
 SG_ WllStmltnIntlRmpGnFtr : 40|8@1+ (0.5,0) [0|125] "%" Vector__XXX
 SG_ WSttOttPssPttLvAtvStts : 48|4@1+ (1,0) [0|15] "" Vector__XXX

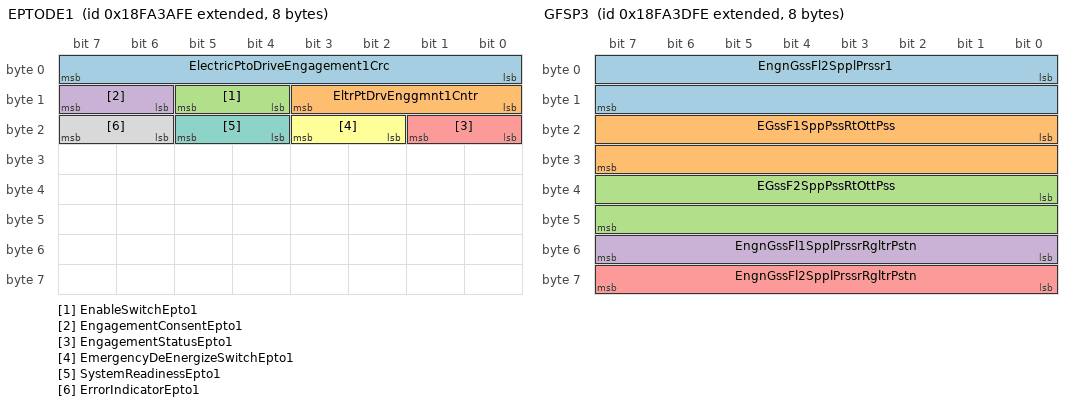
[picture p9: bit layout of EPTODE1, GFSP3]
BO_ 2566535934 EPTODE1: 8 Vector__XXX
 SG_ ElectricPtoDriveEngagement1Crc : 0|8@1+ (1,0) [0|250] "count" Vector__XXX
 SG_ EltrPtDrvEnggmnt1Cntr : 8|4@1+ (1,0) [0|15] "" Vector__XXX
 SG_ EnableSwitchEpto1 : 12|2@1+ (1,0) [0|3] "" Vector__XXX
 SG_ EngagementConsentEpto1 : 14|2@1+ (1,0) [0|3] "" Vector__XXX
 SG_ EngagementStatusEpto1 : 16|2@1+ (1,0) [0|3] "" Vector__XXX
 SG_ EmergencyDeEnergizeSwitchEpto1 : 18|2@1+ (1,0) [0|3] "" Vector__XXX
 SG_ SystemReadinessEpto1 : 20|2@1+ (1,0) [0|3] "" Vector__XXX
 SG_ ErrorIndicatorEpto1 : 22|2@1+ (1,0) [0|3] "" Vector__XXX

BO_ 2566536190 EPTO1I: 8 Vector__XXX
 SG_ Epto1CurrentLimit : 0|16@1+ (0.05,0) [0|3212.75] "A" Vector__XXX
 SG_ Epto1Current : 16|16@1+ (0.05,0) [0|3212.75] "A" Vector__XXX
 SG_ Epto1Voltage : 32|16@1+ (0.05,0) [0|3212.75] "V" Vector__XXX

BO_ 2566536446 E02SI: 8 Vector__XXX
 SG_ EngnExhstO2Snsr1ArFlEqvlnRt : 0|16@1+ (0.0000305,0) [0|1.9597775] "" Vector__XXX
 SG_ EngineExhaustO2Sensor1Voltage : 16|8@1+ (0.01,0) [0|2.5] "V" Vector__XXX
 SG_ EngnExhstO2Snsr2ArFlEqvlnRt : 24|16@1+ (0.0000305,0) [0|1.9597775] "" Vector__XXX
 SG_ EngineExhaustO2Sensor2Voltage : 40|8@1+ (0.01,0) [0|2.5] "V" Vector__XXX

BO_ 2566536702 GFSP3: 8 Vector__XXX
 SG_ EngnGssFl2SpplPrssr1 : 0|16@1+ (0.5,0) [0|32127.5] "kPa" Vector__XXX
 SG_ EGssF1SppPssRtOttPss : 16|16@1+ (1,0) [0|64255] "kPa" Vector__XXX
 SG_ EGssF2SppPssRtOttPss : 32|16@1+ (1,0) [0|64255] "kPa" Vector__XXX
 SG_ EngnGssFl1SpplPrssrRgltrPstn : 48|8@1+ (0.4,0) [0|100] "%" Vector__XXX
 SG_ EngnGssFl2SpplPrssrRgltrPstn : 56|8@1+ (0.4,0) [0|100] "%" Vector__XXX

BO_ 2499428094 TS: 8 Vector__XXX
 SG_ TrafficSignSpeedLimit : 0|16@1+ (0.00390625,0) [0|250.99609375] "km/h" Vector__XXX

BO_ 2566537214 EC4: 8 Vector__XXX
 SG_ EngnClngFnClntAtvtnTmprtr : 0|16@1+ (0.03125,-273) [-273|1734.96875] "degC" Vector__XXX
 SG_ EngnClngFnIntkMnfldAtvtnTmprtr : 16|16@1+ (0.03125,-273) [-273|1734.96875] "degC" Vector__XXX

BO_ 2633768190 RCI1: 8 Vector__XXX
 SG_ RefrigeratedCompartmentPosition : 0|16@1+ (1,0) [0|64255] "count" Vector__XXX
 SG_ RefrigeratedCompartmentId : 16|24@1+ (1,0) [0|16449535] "count" Vector__XXX
 SG_ RefrigeratedCompartmentHumidity : 40|8@1+ (0.4,0) [0|100] "%" Vector__XXX
 SG_ RfrgrtdCmprtmntTmprtr : 48|16@1+ (0.03125,-273) [-273|1734.96875] "degC" Vector__XXX

BO_ 2633768446 RCI2: 8 Vector__XXX
 SG_ TransportationCompartmentDoorId : 0|8@1+ (1,0) [0|250] "count" Vector__XXX
 SG_ TrnsprttnCmprtmntDrStts : 8|2@1+ (1,0) [0|3] "" Vector__XXX

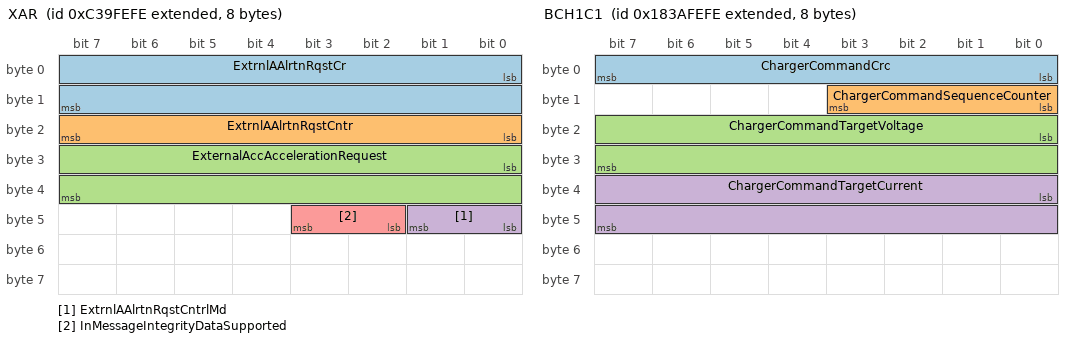
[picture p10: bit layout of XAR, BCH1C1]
BO_ 2352611070 XAR: 8 Vector__XXX
 SG_ ExtrnlAAlrtnRqstCr : 0|16@1+ (1,0) [0|64255] "count" Vector__XXX
 SG_ ExtrnlAAlrtnRqstCntr : 16|8@1+ (1,0) [0|250] "count" Vector__XXX
 SG_ ExternalAccAccelerationRequest : 24|16@1+ (0.00048828125,-15.6865234375) [-15.6865234375|15.68798828125] "m/(s*s)" Vector__XXX
 SG_ ExtrnlAAlrtnRqstCntrlMd : 40|2@1+ (1,0) [0|3] "" Vector__XXX
 SG_ InMessageIntegrityDataSupported : 42|2@1+ (1,0) [0|3] "" Vector__XXX

BO_ 2554003198 BCH1C1: 8 Vector__XXX
 SG_ ChargerCommandCrc : 0|8@1+ (1,0) [0|250] "count" Vector__XXX
 SG_ ChargerCommandSequenceCounter : 8|4@1+ (1,0) [0|15] "" Vector__XXX
 SG_ ChargerCommandTargetVoltage : 16|16@1+ (0.05,0) [0|3212.75] "V" Vector__XXX
 SG_ ChargerCommandTargetCurrent : 32|16@1+ (0.0625,0) [0|4015.9375] "A" Vector__XXX

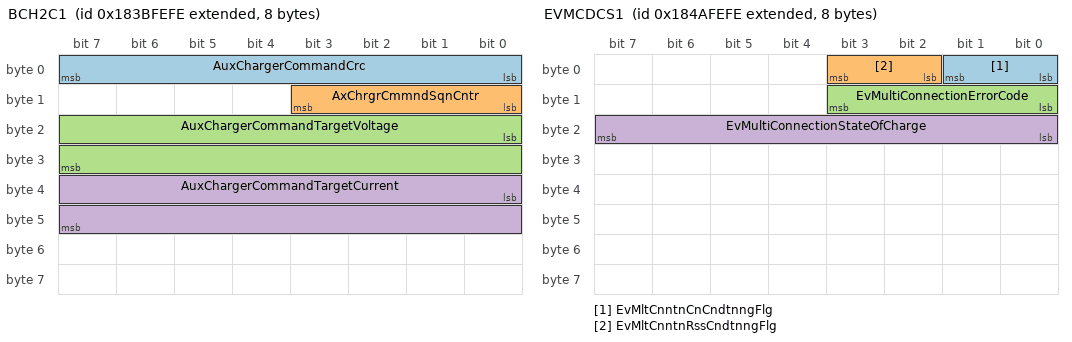
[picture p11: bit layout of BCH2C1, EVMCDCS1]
BO_ 2554068734 BCH2C1: 8 Vector__XXX
 SG_ AuxChargerCommandCrc : 0|8@1+ (1,0) [0|250] "count" Vector__XXX
 SG_ AxChrgrCmmndSqnCntr : 8|4@1+ (1,0) [0|15] "" Vector__XXX
 SG_ AuxChargerCommandTargetVoltage : 16|16@1+ (0.05,0) [0|3212.75] "V" Vector__XXX
 SG_ AuxChargerCommandTargetCurrent : 32|16@1+ (0.0625,0) [0|4015.9375] "A" Vector__XXX

BO_ 2555051774 EVMCDCS1: 8 Vector__XXX
 SG_ EvMltCnntnCnCndtnngFlg : 0|2@1+ (1,0) [0|3] "" Vector__XXX
 SG_ EvMltCnntnRssCndtnngFlg : 2|2@1+ (1,0) [0|3] "" Vector__XXX
 SG_ EvMultiConnectionErrorCode : 8|4@1+ (1,0) [0|15] "" Vector__XXX
 SG_ EvMultiConnectionStateOfCharge : 16|8@1+ (0.5,0) [0|125] "%" Vector__XXX

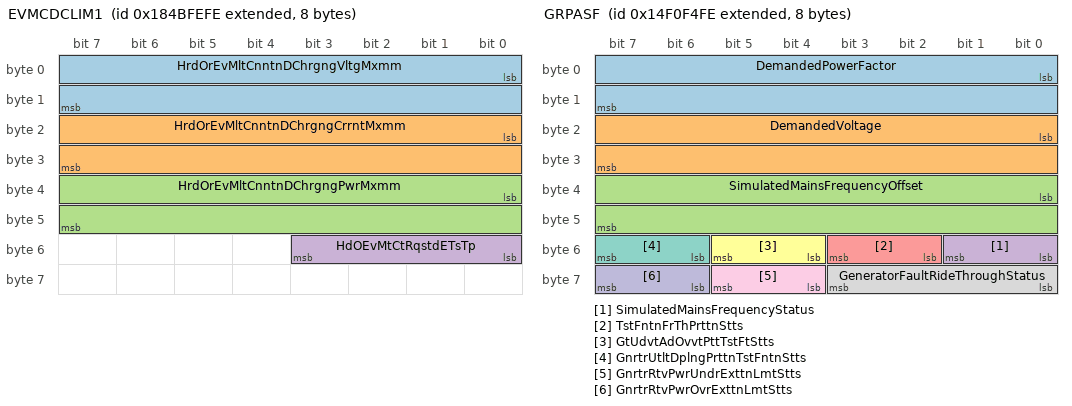
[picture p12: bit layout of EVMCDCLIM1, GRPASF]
BO_ 2555117310 EVMCDCLIM1: 8 Vector__XXX
 SG_ HrdOrEvMltCnntnDChrgngVltgMxmm : 0|16@1+ (0.05,0) [0|3212.75] "V" Vector__XXX
 SG_ HrdOrEvMltCnntnDChrgngCrrntMxmm : 16|16@1+ (0.0625,0) [0|4015.9375] "A" Vector__XXX
 SG_ HrdOrEvMltCnntnDChrgngPwrMxmm : 32|16@1+ (0.05,0) [0|3212.75] "kW" Vector__XXX
 SG_ HdOEvMtCtRqstdETsTp : 48|4@1+ (1,0) [0|15] "" Vector__XXX

BO_ 2565900286 WCSS1: 8 Vector__XXX
 SG_ WirelessChargerSystemState : 0|8@1+ (1,0) [0|250] "" Vector__XXX
 SG_ WrlssChrgrPrsntChrgngVltg : 8|16@1+ (0.03125,0) [0|2007.96875] "V" Vector__XXX
 SG_ WrlssChrgrPrsntChrgngCrrnt : 24|16@1+ (0.1,-3212.7) [-3212.7|3212.8] "A" Vector__XXX
 SG_ WirelessChargerDeratingReason : 40|8@1+ (1,0) [0|250] "" Vector__XXX

BO_ 2565900542 WCAQS: 8 Vector__XXX
 SG_ WrlssChrgrAlgnmntXQlt : 0|8@1+ (0.8,-100) [-100|100] "%" Vector__XXX
 SG_ WrlssChrgrAlgnmntYQlt : 8|8@1+ (0.8,-100) [-100|100] "%" Vector__XXX
 SG_ WrlssChrgrAlgnmntZQlt : 16|8@1+ (0.8,-100) [-100|100] "%" Vector__XXX
 SG_ WrlssChrgrAlgnmntOvrllQlt : 24|8@1+ (0.4,0) [0|100] "%" Vector__XXX

BO_ 2498819326 GRPASF: 8 Vector__XXX
 SG_ DemandedPowerFactor : 0|16@1+ (0.00006103515625,-1) [-1|2.92181396484375] "" Vector__XXX
 SG_ DemandedVoltage : 16|16@1+ (0.01,-321.28) [-321.28|321.27] "V" Vector__XXX
 SG_ SimulatedMainsFrequencyOffset : 32|16@1+ (0.0078125,0) [0|501.9921875] "Hz" Vector__XXX
 SG_ SimulatedMainsFrequencyStatus : 48|2@1+ (1,0) [0|3] "" Vector__XXX
 SG_ TstFntnFrThPrttnStts : 50|2@1+ (1,0) [0|3] "" Vector__XXX
 SG_ GtUdvtAdOvvtPttTstFtStts : 52|2@1+ (1,0) [0|3] "" Vector__XXX
 SG_ GnrtrUtltDplngPrttnTstFntnStts : 54|2@1+ (1,0) [0|3] "" Vector__XXX
 SG_ GeneratorFaultRideThroughStatus : 56|4@1+ (1,0) [0|15] "" Vector__XXX
 SG_ GnrtrRtvPwrUndrExttnLmtStts : 60|2@1+ (1,0) [0|3] "" Vector__XXX
 SG_ GnrtrRtvPwrOvrExttnLmtStts : 62|2@1+ (1,0) [0|3] "" Vector__XXX

BO_ 2364761342 TVD: 8 Vector__XXX
 SG_ LftTrnsmssnOtptShftDrtnlSpd : 0|16@1+ (0.25,-8031.75) [-8031.75|8032] "rpm" Vector__XXX
 SG_ RghtTrnsmssnOtptShftDrtnlSpd : 16|16@1+ (0.25,-8031.75) [-8031.75|8032] "rpm" Vector__XXX

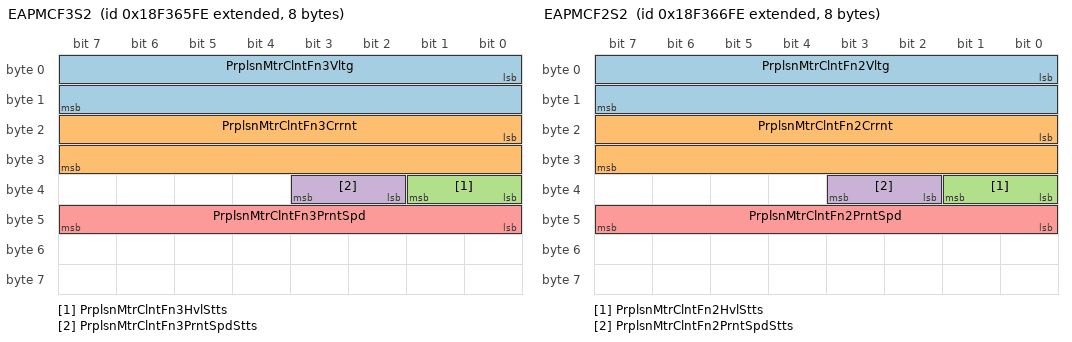
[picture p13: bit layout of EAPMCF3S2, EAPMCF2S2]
BO_ 2566088190 EAPMCF3S2: 8 Vector__XXX
 SG_ PrplsnMtrClntFn3Vltg : 0|16@1+ (0.05,0) [0|3212.75] "V" Vector__XXX
 SG_ PrplsnMtrClntFn3Crrnt : 16|16@1+ (0.05,-1600) [-1600|1612.75] "A" Vector__XXX
 SG_ PrplsnMtrClntFn3HvlStts : 32|2@1+ (1,0) [0|3] "" Vector__XXX
 SG_ PrplsnMtrClntFn3PrntSpdStts : 34|2@1+ (1,0) [0|3] "" Vector__XXX
 SG_ PrplsnMtrClntFn3PrntSpd : 40|8@1+ (0.5,0) [0|125] "%" Vector__XXX

BO_ 2566088446 EAPMCF2S2: 8 Vector__XXX
 SG_ PrplsnMtrClntFn2Vltg : 0|16@1+ (0.05,0) [0|3212.75] "V" Vector__XXX
 SG_ PrplsnMtrClntFn2Crrnt : 16|16@1+ (0.05,-1600) [-1600|1612.75] "A" Vector__XXX
 SG_ PrplsnMtrClntFn2HvlStts : 32|2@1+ (1,0) [0|3] "" Vector__XXX
 SG_ PrplsnMtrClntFn2PrntSpdStts : 34|2@1+ (1,0) [0|3] "" Vector__XXX
 SG_ PrplsnMtrClntFn2PrntSpd : 40|8@1+ (0.5,0) [0|125] "%" Vector__XXX

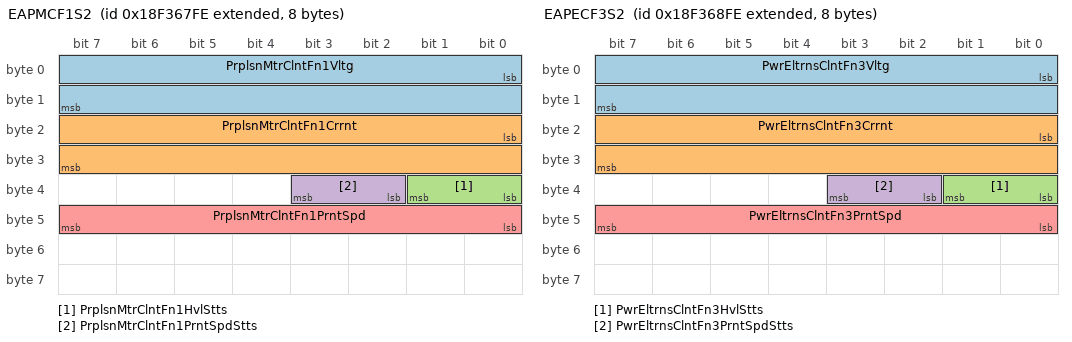
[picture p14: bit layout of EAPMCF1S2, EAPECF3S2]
BO_ 2566088702 EAPMCF1S2: 8 Vector__XXX
 SG_ PrplsnMtrClntFn1Vltg : 0|16@1+ (0.05,0) [0|3212.75] "V" Vector__XXX
 SG_ PrplsnMtrClntFn1Crrnt : 16|16@1+ (0.05,-1600) [-1600|1612.75] "A" Vector__XXX
 SG_ PrplsnMtrClntFn1HvlStts : 32|2@1+ (1,0) [0|3] "" Vector__XXX
 SG_ PrplsnMtrClntFn1PrntSpdStts : 34|2@1+ (1,0) [0|3] "" Vector__XXX
 SG_ PrplsnMtrClntFn1PrntSpd : 40|8@1+ (0.5,0) [0|125] "%" Vector__XXX

BO_ 2566088958 EAPECF3S2: 8 Vector__XXX
 SG_ PwrEltrnsClntFn3Vltg : 0|16@1+ (0.05,0) [0|3212.75] "V" Vector__XXX
 SG_ PwrEltrnsClntFn3Crrnt : 16|16@1+ (0.05,-1600) [-1600|1612.75] "A" Vector__XXX
 SG_ PwrEltrnsClntFn3HvlStts : 32|2@1+ (1,0) [0|3] "" Vector__XXX
 SG_ PwrEltrnsClntFn3PrntSpdStts : 34|2@1+ (1,0) [0|3] "" Vector__XXX
 SG_ PwrEltrnsClntFn3PrntSpd : 40|8@1+ (0.5,0) [0|125] "%" Vector__XXX

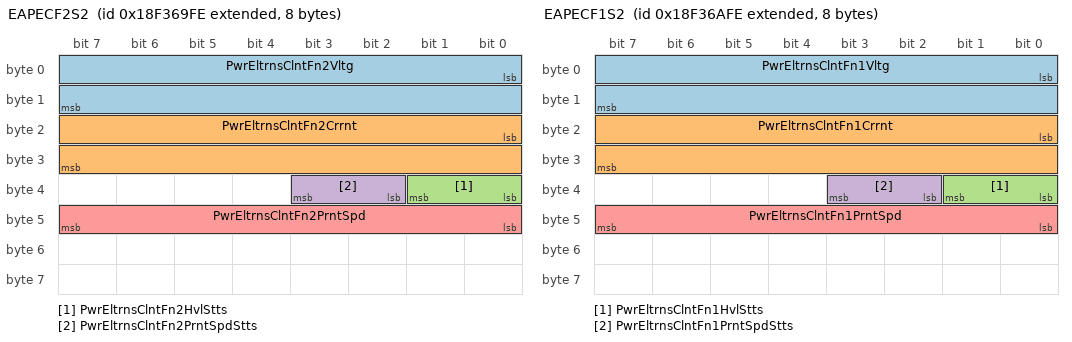
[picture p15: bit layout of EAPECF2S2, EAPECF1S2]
BO_ 2566089214 EAPECF2S2: 8 Vector__XXX
 SG_ PwrEltrnsClntFn2Vltg : 0|16@1+ (0.05,0) [0|3212.75] "V" Vector__XXX
 SG_ PwrEltrnsClntFn2Crrnt : 16|16@1+ (0.05,-1600) [-1600|1612.75] "A" Vector__XXX
 SG_ PwrEltrnsClntFn2HvlStts : 32|2@1+ (1,0) [0|3] "" Vector__XXX
 SG_ PwrEltrnsClntFn2PrntSpdStts : 34|2@1+ (1,0) [0|3] "" Vector__XXX
 SG_ PwrEltrnsClntFn2PrntSpd : 40|8@1+ (0.5,0) [0|125] "%" Vector__XXX

BO_ 2566089470 EAPECF1S2: 8 Vector__XXX
 SG_ PwrEltrnsClntFn1Vltg : 0|16@1+ (0.05,0) [0|3212.75] "V" Vector__XXX
 SG_ PwrEltrnsClntFn1Crrnt : 16|16@1+ (0.05,-1600) [-1600|1612.75] "A" Vector__XXX
 SG_ PwrEltrnsClntFn1HvlStts : 32|2@1+ (1,0) [0|3] "" Vector__XXX
 SG_ PwrEltrnsClntFn1PrntSpdStts : 34|2@1+ (1,0) [0|3] "" Vector__XXX
 SG_ PwrEltrnsClntFn1PrntSpd : 40|8@1+ (0.5,0) [0|125] "%" Vector__XXX

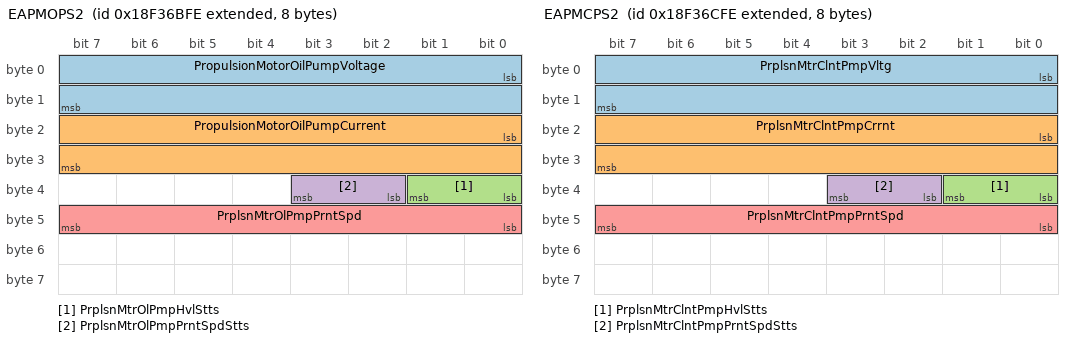
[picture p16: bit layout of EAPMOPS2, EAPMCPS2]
BO_ 2566089726 EAPMOPS2: 8 Vector__XXX
 SG_ PropulsionMotorOilPumpVoltage : 0|16@1+ (0.05,0) [0|3212.75] "V" Vector__XXX
 SG_ PropulsionMotorOilPumpCurrent : 16|16@1+ (0.05,-1600) [-1600|1612.75] "A" Vector__XXX
 SG_ PrplsnMtrOlPmpHvlStts : 32|2@1+ (1,0) [0|3] "" Vector__XXX
 SG_ PrplsnMtrOlPmpPrntSpdStts : 34|2@1+ (1,0) [0|3] "" Vector__XXX
 SG_ PrplsnMtrOlPmpPrntSpd : 40|8@1+ (0.5,0) [0|125] "%" Vector__XXX

BO_ 2566089982 EAPMCPS2: 8 Vector__XXX
 SG_ PrplsnMtrClntPmpVltg : 0|16@1+ (0.05,0) [0|3212.75] "V" Vector__XXX
 SG_ PrplsnMtrClntPmpCrrnt : 16|16@1+ (0.05,-1600) [-1600|1612.75] "A" Vector__XXX
 SG_ PrplsnMtrClntPmpHvlStts : 32|2@1+ (1,0) [0|3] "" Vector__XXX
 SG_ PrplsnMtrClntPmpPrntSpdStts : 34|2@1+ (1,0) [0|3] "" Vector__XXX
 SG_ PrplsnMtrClntPmpPrntSpd : 40|8@1+ (0.5,0) [0|125] "%" Vector__XXX

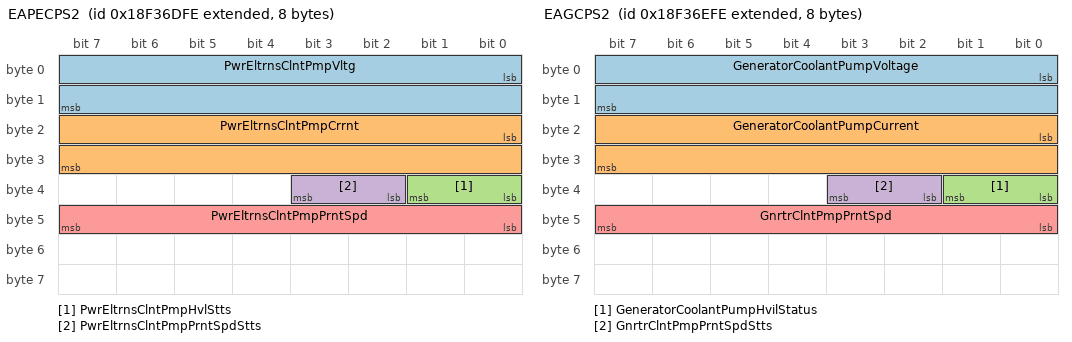
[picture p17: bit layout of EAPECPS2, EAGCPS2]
BO_ 2566090238 EAPECPS2: 8 Vector__XXX
 SG_ PwrEltrnsClntPmpVltg : 0|16@1+ (0.05,0) [0|3212.75] "V" Vector__XXX
 SG_ PwrEltrnsClntPmpCrrnt : 16|16@1+ (0.05,-1600) [-1600|1612.75] "A" Vector__XXX
 SG_ PwrEltrnsClntPmpHvlStts : 32|2@1+ (1,0) [0|3] "" Vector__XXX
 SG_ PwrEltrnsClntPmpPrntSpdStts : 34|2@1+ (1,0) [0|3] "" Vector__XXX
 SG_ PwrEltrnsClntPmpPrntSpd : 40|8@1+ (0.5,0) [0|125] "%" Vector__XXX

BO_ 2566090494 EAGCPS2: 8 Vector__XXX
 SG_ GeneratorCoolantPumpVoltage : 0|16@1+ (0.05,0) [0|3212.75] "V" Vector__XXX
 SG_ GeneratorCoolantPumpCurrent : 16|16@1+ (0.05,-1600) [-1600|1612.75] "A" Vector__XXX
 SG_ GeneratorCoolantPumpHvilStatus : 32|2@1+ (1,0) [0|3] "" Vector__XXX
 SG_ GnrtrClntPmpPrntSpdStts : 34|2@1+ (1,0) [0|3] "" Vector__XXX
 SG_ GnrtrClntPmpPrntSpd : 40|8@1+ (0.5,0) [0|125] "%" Vector__XXX

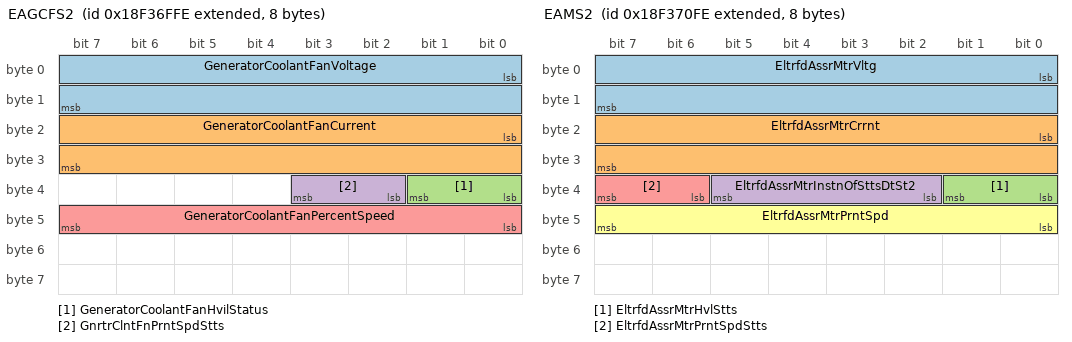
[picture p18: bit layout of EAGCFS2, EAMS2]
BO_ 2566090750 EAGCFS2: 8 Vector__XXX
 SG_ GeneratorCoolantFanVoltage : 0|16@1+ (0.05,0) [0|3212.75] "V" Vector__XXX
 SG_ GeneratorCoolantFanCurrent : 16|16@1+ (0.05,-1600) [-1600|1612.75] "A" Vector__XXX
 SG_ GeneratorCoolantFanHvilStatus : 32|2@1+ (1,0) [0|3] "" Vector__XXX
 SG_ GnrtrClntFnPrntSpdStts : 34|2@1+ (1,0) [0|3] "" Vector__XXX
 SG_ GeneratorCoolantFanPercentSpeed : 40|8@1+ (0.5,0) [0|125] "%" Vector__XXX

BO_ 2566091006 EAMS2: 8 Vector__XXX
 SG_ EltrfdAssrMtrVltg : 0|16@1+ (0.05,0) [0|3212.75] "V" Vector__XXX
 SG_ EltrfdAssrMtrCrrnt : 16|16@1+ (0.05,-1600) [-1600|1612.75] "A" Vector__XXX
 SG_ EltrfdAssrMtrHvlStts : 32|2@1+ (1,0) [0|3] "" Vector__XXX
 SG_ EltrfdAssrMtrInstnOfSttsDtSt2 : 34|4@1+ (1,0) [0|15] "" Vector__XXX
 SG_ EltrfdAssrMtrPrntSpdStts : 38|2@1+ (1,0) [0|3] "" Vector__XXX
 SG_ EltrfdAssrMtrPrntSpd : 40|8@1+ (0.5,0) [0|125] "%" Vector__XXX

BO_ 2633637886 ASI6: 8 Vector__XXX
 SG_ Aftertreatment2DefDosingMode : 0|8@1+ (1,0) [0|250] "count" Vector__XXX

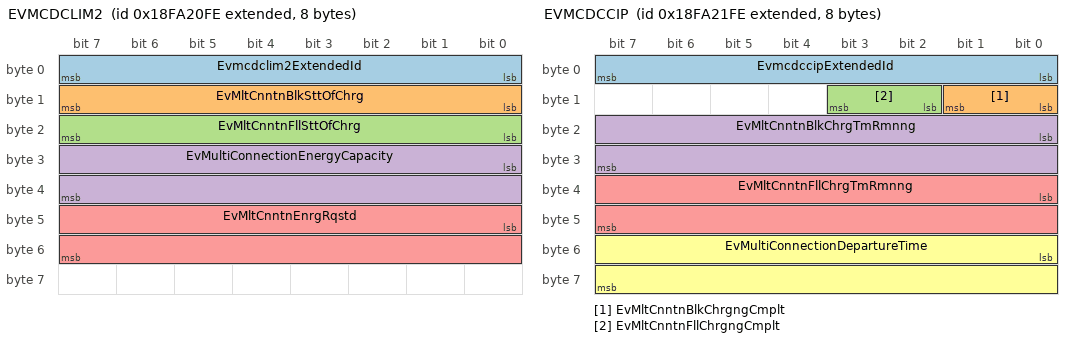
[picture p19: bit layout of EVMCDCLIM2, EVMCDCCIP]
BO_ 2566529278 EVMCDCLIM2: 8 Vector__XXX
 SG_ Evmcdclim2ExtendedId : 0|8@1+ (1,0) [0|250] "count" Vector__XXX
 SG_ EvMltCnntnBlkSttOfChrg : 8|8@1+ (0.5,0) [0|125] "%" Vector__XXX
 SG_ EvMltCnntnFllSttOfChrg : 16|8@1+ (0.5,0) [0|125] "%" Vector__XXX
 SG_ EvMultiConnectionEnergyCapacity : 24|16@1+ (1,0) [0|64255] "kWh" Vector__XXX
 SG_ EvMltCnntnEnrgRqstd : 40|16@1+ (1,0) [0|64255] "kWh" Vector__XXX

BO_ 2566529534 EVMCDCCIP: 8 Vector__XXX
 SG_ EvmcdccipExtendedId : 0|8@1+ (1,0) [0|250] "count" Vector__XXX
 SG_ EvMltCnntnBlkChrgngCmplt : 8|2@1+ (1,0) [0|3] "" Vector__XXX
 SG_ EvMltCnntnFllChrgngCmplt : 10|2@1+ (1,0) [0|3] "" Vector__XXX
 SG_ EvMltCnntnBlkChrgTmRmnng : 16|16@1+ (10,0) [0|642550] "s" Vector__XXX
 SG_ EvMltCnntnFllChrgTmRmnng : 32|16@1+ (10,0) [0|642550] "s" Vector__XXX
 SG_ EvMultiConnectionDepartureTime : 48|16@1+ (10,0) [0|642550] "s" Vector__XXX

CM_ BO_ 2364756990 "High Voltage Energy Storage Pack 4 Data 13";
CM_ SG_ 2364756990 Hvsp4MxIsttsDsCtLtExtddR "HVESP4 Maximum Instantaneous Discharge Current Limit (Extended Range): The maximum instantaneous current flow limit out of this High Voltage Energy Storage Pack instance. This parameter is defined from the high voltage energy storage pack's point of ...";
CM_ SG_ 2364756990 Hvsp4MxIsttsCCtLtExtddR "HVESP4 Maximum Instantaneous Charge Current Limit (Extended Range): The maximum instantaneous current flow limit into this High Voltage Energy Storage Pack instance. This parameter is defined from the high voltage energy storage pack's point of view ...";
CM_ SG_ 2364756990 Hvsp4NmnlDshrgCrrntLmt "HVESP4 Nominal Discharge Current Limit: The nominal current flow limit out of the High Voltage Energy Storage Pack instance. This limit is a preferred boundary for normal operation. Operating within this limit reduces negative impacts on battery lif...";
CM_ SG_ 2364756990 Hvesp4NominalChargeCurrentLimit "HVESP4 Nominal Charge Current Limit: The nominal current flow limit into the High Voltage Energy Storage Pack instance. This limit is a preferred boundary for normal operation. Operating within this limit reduces negative impacts on battery life or ...";
CM_ BO_ 2364757246 "High Voltage Energy Storage Pack 5 Data 12";
CM_ SG_ 2364757246 Hvsp5AvllDshrgPwrExtnddRng "HVESP5 Available Discharge Power (Extended Range): The rate at which this High Voltage Energy Storage Pack instance can currently provide energy for propulsion or other uses.This parameter is for one of multiple packs in an HVESS. If there is only on...";
CM_ SG_ 2364757246 Hvsp5AvllChrgPwrExtnddRng "HVESP5 Available Charge Power (Extended Range): The rate at which this High Voltage Energy Storage Pack instance can currently receive energy from a regenerative or recharging system.This parameter is for one of multiple packs in an HVESS. If there i...";
CM_ SG_ 2364757246 Hvesp5VoltageLevelExtendedRange "HVESP5 Voltage Level (Extended Range): The voltage level of this High Voltage Energy Storage Pack instance. This parameter should be synchronized with SPN 22449 (HVESP5 Current (Extended Range)) such that a realized power value can be calculated. If ...";
CM_ SG_ 2364757246 Hvesp5CurrentExtendedRange "HVESP5 Current (Extended Range): The current in or out of this High Voltage Energy Storage Pack instance. This parameter should be synchronized with SPN 22448 (HVESP5 Voltage Level (Extended Range)) such that a realized power value can be calculated....";
CM_ BO_ 2364757502 "High Voltage Energy Storage Pack 5 Data 13";
CM_ SG_ 2364757502 Hvsp5MxIsttsDsCtLtExtddR "HVESP5 Maximum Instantaneous Discharge Current Limit (Extended Range): The maximum instantaneous current flow limit out of this High Voltage Energy Storage Pack instance. This parameter is defined from the high voltage energy storage pack's point of ...";
CM_ SG_ 2364757502 Hvsp5MxIsttsCCtLtExtddR "HVESP5 Maximum Instantaneous Charge Current Limit (Extended Range): The maximum instantaneous current flow limit into this High Voltage Energy Storage Pack instance. This parameter is defined from the high voltage energy storage pack's point of view ...";
CM_ SG_ 2364757502 Hvsp5NmnlDshrgCrrntLmt "HVESP5 Nominal Discharge Current Limit: The nominal current flow limit out of the High Voltage Energy Storage Pack instance. This limit is a preferred boundary for normal operation. Operating within this limit reduces negative impacts on battery lif...";
CM_ SG_ 2364757502 Hvesp5NominalChargeCurrentLimit "HVESP5 Nominal Charge Current Limit: The nominal current flow limit into the High Voltage Energy Storage Pack instance. This limit is a preferred boundary for normal operation. Operating within this limit reduces negative impacts on battery life or ...";
CM_ BO_ 2364757758 "High Voltage Energy Storage Pack 6 Data 12";
CM_ SG_ 2364757758 Hvsp6AvllDshrgPwrExtnddRng "HVESP6 Available Discharge Power (Extended Range): The rate at which this High Voltage Energy Storage Pack instance can currently provide energy for propulsion or other uses.This parameter is for one of multiple packs in an HVESS. If there is only on...";
CM_ SG_ 2364757758 Hvsp6AvllChrgPwrExtnddRng "HVESP6 Available Charge Power (Extended Range): The rate at which this High Voltage Energy Storage Pack instance can currently receive energy from a regenerative or recharging system.This parameter is for one of multiple packs in an HVESS. If there i...";
CM_ SG_ 2364757758 Hvesp6VoltageLevelExtendedRange "HVESP6 Voltage Level (Extended Range): The voltage level of this High Voltage Energy Storage Pack instance. This parameter should be synchronized with SPN 22471 (HVESP6 Current (Extended Range)) such that a realized power value can be calculated. If ...";
CM_ SG_ 2364757758 Hvesp6CurrentExtendedRange "HVESP6 Current (Extended Range): The current in or out of this High Voltage Energy Storage Pack instance. This parameter should be synchronized with SPN 22470 (HVESP6 Voltage Level (Extended Range)) such that a realized power value can be calculated....";
CM_ BO_ 2364758014 "High Voltage Energy Storage Pack 6 Data 13";
CM_ SG_ 2364758014 Hvsp6MxIsttsDsCtLtExtddR "HVESP6 Maximum Instantaneous Discharge Current Limit (Extended Range): The maximum instantaneous current flow limit out of this High Voltage Energy Storage Pack instance. This parameter is defined from the high voltage energy storage pack's point of ...";
CM_ SG_ 2364758014 Hvsp6MxIsttsCCtLtExtddR "HVESP6 Maximum Instantaneous Charge Current Limit (Extended Range): The maximum instantaneous current flow limit into this High Voltage Energy Storage Pack instance. This parameter is defined from the high voltage energy storage pack's point of view ...";
CM_ SG_ 2364758014 Hvsp6NmnlDshrgCrrntLmt "HVESP6 Nominal Discharge Current Limit: The nominal current flow limit out of the High Voltage Energy Storage Pack instance. This limit is a preferred boundary for normal operation. Operating within this limit reduces negative impacts on battery lif...";
CM_ SG_ 2364758014 Hvesp6NominalChargeCurrentLimit "HVESP6 Nominal Charge Current Limit: The nominal current flow limit into the High Voltage Energy Storage Pack instance. This limit is a preferred boundary for normal operation. Operating within this limit reduces negative impacts on battery life or ...";
CM_ BO_ 2364758270 "High Voltage Energy Storage Pack 7 Data 12";
CM_ SG_ 2364758270 Hvsp7AvllDshrgPwrExtnddRng "HVESP7 Available Discharge Power (Extended Range): The rate at which this High Voltage Energy Storage Pack instance can currently provide energy for propulsion or other uses.This parameter is for one of multiple packs in an HVESS. If there is only on...";
CM_ SG_ 2364758270 Hvsp7AvllChrgPwrExtnddRng "HVESP7 Available Charge Power (Extended Range): The rate at which this High Voltage Energy Storage Pack instance can currently receive energy from a regenerative or recharging system.This parameter is for one of multiple packs in an HVESS. If there i...";
CM_ SG_ 2364758270 Hvesp7VoltageLevelExtendedRange "HVESP7 Voltage Level (Extended Range): The voltage level of this High Voltage Energy Storage Pack instance. This parameter should be synchronized with SPN 22493 (HVESP7 Current (Extended Range)) such that a realized power value can be calculated. If ...";
CM_ SG_ 2364758270 Hvesp7CurrentExtendedRange "HVESP7 Current (Extended Range): The current in or out of this High Voltage Energy Storage Pack instance. This parameter should be synchronized with SPN 22492 (HVESP7 Voltage Level (Extended Range)) such that a realized power value can be calculated....";
CM_ BO_ 2364758526 "High Voltage Energy Storage Pack 7 Data 13";
CM_ SG_ 2364758526 Hvsp7MxIsttsDsCtLtExtddR "HVESP7 Maximum Instantaneous Discharge Current Limit (Extended Range): The maximum instantaneous current flow limit out of this High Voltage Energy Storage Pack instance. This parameter is defined from the high voltage energy storage pack's point of ...";
CM_ SG_ 2364758526 Hvsp7MxIsttsCCtLtExtddR "HVESP7 Maximum Instantaneous Charge Current Limit (Extended Range): The maximum instantaneous current flow limit into this High Voltage Energy Storage Pack instance. This parameter is defined from the high voltage energy storage pack's point of view ...";
CM_ SG_ 2364758526 Hvsp7NmnlDshrgCrrntLmt "HVESP7 Nominal Discharge Current Limit: The nominal current flow limit out of the High Voltage Energy Storage Pack instance. This limit is a preferred boundary for normal operation. Operating within this limit reduces negative impacts on battery lif...";
CM_ SG_ 2364758526 Hvesp7NominalChargeCurrentLimit "HVESP7 Nominal Charge Current Limit: The nominal current flow limit into the High Voltage Energy Storage Pack instance. This limit is a preferred boundary for normal operation. Operating within this limit reduces negative impacts on battery life or ...";
CM_ BO_ 2364758782 "High Voltage Energy Storage Pack 8 Data 12";
CM_ SG_ 2364758782 Hvsp8AvllDshrgPwrExtnddRng "HVESP8 Available Discharge Power (Extended Range): The rate at which this High Voltage Energy Storage Pack instance can currently provide energy for propulsion or other uses.This parameter is for one of multiple packs in an HVESS. If there is only on...";
CM_ SG_ 2364758782 Hvsp8AvllChrgPwrExtnddRng "HVESP8 Available Charge Power (Extended Range): The rate at which this High Voltage Energy Storage Pack instance can currently receive energy from a regenerative or recharging system.This parameter is for one of multiple packs in an HVESS. If there i...";
CM_ SG_ 2364758782 Hvesp8VoltageLevelExtendedRange "HVESP8 Voltage Level (Extended Range): The voltage level of this High Voltage Energy Storage Pack instance. This parameter should be synchronized with SPN 22515 (HVESP8 Current (Extended Range)) such that a realized power value can be calculated. If ...";
CM_ SG_ 2364758782 Hvesp8CurrentExtendedRange "HVESP8 Current (Extended Range): The current in or out of this High Voltage Energy Storage Pack instance. This parameter should be synchronized with SPN 22514 (HVESP8 Voltage Level (Extended Range)) such that a realized power value can be calculated....";
CM_ BO_ 2364759038 "High Voltage Energy Storage Pack 8 Data 13";
CM_ SG_ 2364759038 Hvsp8MxIsttsDsCtLtExtddR "HVESP8 Maximum Instantaneous Discharge Current Limit (Extended Range): The maximum instantaneous current flow limit out of this High Voltage Energy Storage Pack instance. This parameter is defined from the high voltage energy storage pack's point of ...";
CM_ SG_ 2364759038 Hvsp8MxIsttsCCtLtExtddR "HVESP8 Maximum Instantaneous Charge Current Limit (Extended Range): The maximum instantaneous current flow limit into this High Voltage Energy Storage Pack instance. This parameter is defined from the high voltage energy storage pack's point of view ...";
CM_ SG_ 2364759038 Hvsp8NmnlDshrgCrrntLmt "HVESP8 Nominal Discharge Current Limit: The nominal current flow limit out of the High Voltage Energy Storage Pack instance. This limit is a preferred boundary for normal operation. Operating within this limit reduces negative impacts on battery lif...";
CM_ SG_ 2364759038 Hvesp8NominalChargeCurrentLimit "HVESP8 Nominal Charge Current Limit: The nominal current flow limit into the High Voltage Energy Storage Pack instance. This limit is a preferred boundary for normal operation. Operating within this limit reduces negative impacts on battery life or ...";
CM_ BO_ 2364759294 "High Voltage Energy Storage Pack 9 Data 12";
CM_ SG_ 2364759294 Hvsp9AvllDshrgPwrExtnddRng "HVESP9 Available Discharge Power (Extended Range): The rate at which this High Voltage Energy Storage Pack instance can currently provide energy for propulsion or other uses.This parameter is for one of multiple packs in an HVESS. If there is only on...";
CM_ SG_ 2364759294 Hvsp9AvllChrgPwrExtnddRng "HVESP9 Available Charge Power (Extended Range): The rate at which this High Voltage Energy Storage Pack instance can currently receive energy from a regenerative or recharging system.This parameter is for one of multiple packs in an HVESS. If there i...";
CM_ SG_ 2364759294 Hvesp9VoltageLevelExtendedRange "HVESP9 Voltage Level (Extended Range): The voltage level of this High Voltage Energy Storage Pack instance. This parameter should be synchronized with SPN 22537 (HVESP9 Current (Extended Range)) such that a realized power value can be calculated. If ...";
CM_ SG_ 2364759294 Hvesp9CurrentExtendedRange "HVESP9 Current (Extended Range): The current in or out of this High Voltage Energy Storage Pack instance. This parameter should be synchronized with SPN 22536 (HVESP9 Voltage Level (Extended Range)) such that a realized power value can be calculated....";
CM_ BO_ 2364759550 "High Voltage Energy Storage Pack 9 Data 13";
CM_ SG_ 2364759550 Hvsp9MxIsttsDsCtLtExtddR "HVESP9 Maximum Instantaneous Discharge Current Limit (Extended Range): The maximum instantaneous current flow limit out of this High Voltage Energy Storage Pack instance. This parameter is defined from the high voltage energy storage pack's point of ...";
CM_ SG_ 2364759550 Hvsp9MxIsttsCCtLtExtddR "HVESP9 Maximum Instantaneous Charge Current Limit (Extended Range): The maximum instantaneous current flow limit into this High Voltage Energy Storage Pack instance. This parameter is defined from the high voltage energy storage pack's point of view ...";
CM_ SG_ 2364759550 Hvsp9NmnlDshrgCrrntLmt "HVESP9 Nominal Discharge Current Limit: The nominal current flow limit out of the High Voltage Energy Storage Pack instance. This limit is a preferred boundary for normal operation. Operating within this limit reduces negative impacts on battery lif...";
CM_ SG_ 2364759550 Hvesp9NominalChargeCurrentLimit "HVESP9 Nominal Charge Current Limit: The nominal current flow limit into the High Voltage Energy Storage Pack instance. This limit is a preferred boundary for normal operation. Operating within this limit reduces negative impacts on battery life or ...";
CM_ BO_ 2364759806 "High Voltage Energy Storage Pack 10 Data 12";
CM_ SG_ 2364759806 Hvsp10AvllDshrgPwrExtnddRng "HVESP10 Available Discharge Power (Extended Range): The rate at which this High Voltage Energy Storage Pack instance can currently provide energy for propulsion or other uses.This parameter is for one of multiple packs in an HVESS. If there is only o...";
CM_ SG_ 2364759806 Hvsp10AvllChrgPwrExtnddRng "HVESP10 Available Charge Power (Extended Range): The rate at which this High Voltage Energy Storage Pack instance can currently receive energy from a regenerative or recharging system.This parameter is for one of multiple packs in an HVESS. If there ...";
CM_ SG_ 2364759806 Hvsp10VltgLvlExtnddRng "HVESP10 Voltage Level (Extended Range): The voltage level of this High Voltage Energy Storage Pack instance. This parameter should be synchronized with SPN 22559 (HVESP10 Current (Extended Range)) such that a realized power value can be calculated. I...";
CM_ SG_ 2364759806 Hvesp10CurrentExtendedRange "HVESP10 Current (Extended Range): The current in or out of this High Voltage Energy Storage Pack instance. This parameter should be synchronized with SPN 22558 (HVESP10 Voltage Level (Extended Range)) such that a realized power value can be calculate...";
CM_ BO_ 2364760062 "High Voltage Energy Storage Pack 10 Data 13";
CM_ SG_ 2364760062 Hvsp10MxIsttsDsCtLtExtddR "HVESP10 Maximum Instantaneous Discharge Current Limit (Extended Range): The maximum instantaneous current flow limit out of this High Voltage Energy Storage Pack instance. This parameter is defined from the high voltage energy storage pack's point of...";
CM_ SG_ 2364760062 Hvsp10MxIsttsCCtLtExtddR "HVESP10 Maximum Instantaneous Charge Current Limit (Extended Range): The maximum instantaneous current flow limit into this High Voltage Energy Storage Pack instance. This parameter is defined from the high voltage energy storage pack's point of view...";
CM_ SG_ 2364760062 Hvsp10NmnlDshrgCrrntLmt "HVESP10 Nominal Discharge Current Limit: The nominal current flow limit out of the High Voltage Energy Storage Pack instance. This limit is a preferred boundary for normal operation. Operating within this limit reduces negative impacts on battery li...";
CM_ SG_ 2364760062 Hvsp10NmnlChrgCrrntLmt "HVESP10 Nominal Charge Current Limit: The nominal current flow limit into the High Voltage Energy Storage Pack instance. This limit is a preferred boundary for normal operation. Operating within this limit reduces negative impacts on battery life or...";
CM_ BO_ 2364760318 "High Voltage Energy Storage Pack 11 Data 12";
CM_ SG_ 2364760318 Hvsp11AvllDshrgPwrExtnddRng "HVESP11 Available Discharge Power (Extended Range): The rate at which this High Voltage Energy Storage Pack instance can currently provide energy for propulsion or other uses.This parameter is for one of multiple packs in an HVESS. If there is only o...";
CM_ SG_ 2364760318 Hvsp11AvllChrgPwrExtnddRng "HVESP11 Available Charge Power (Extended Range): The rate at which this High Voltage Energy Storage Pack instance can currently receive energy from a regenerative or recharging system.This parameter is for one of multiple packs in an HVESS. If there ...";
CM_ SG_ 2364760318 Hvsp11VltgLvlExtnddRng "HVESP11 Voltage Level (Extended Range): The voltage level of this High Voltage Energy Storage Pack instance. This parameter should be synchronized with SPN 22581 (HVESP11 Current (Extended Range)) such that a realized power value can be calculated. I...";
CM_ SG_ 2364760318 Hvesp11CurrentExtendedRange "HVESP11 Current (Extended Range): The current in or out of this High Voltage Energy Storage Pack instance. This parameter should be synchronized with SPN 22580 (HVESP11 Voltage Level (Extended Range)) such that a realized power value can be calculate...";
CM_ BO_ 2364760574 "High Voltage Energy Storage Pack 11 Data 13";
CM_ SG_ 2364760574 Hvsp11MxIsttsDsCtLtExtddR "HVESP11 Maximum Instantaneous Discharge Current Limit (Extended Range): The maximum instantaneous current flow limit out of this High Voltage Energy Storage Pack instance. This parameter is defined from the high voltage energy storage pack's point of...";
CM_ SG_ 2364760574 Hvsp11MxIsttsCCtLtExtddR "HVESP11 Maximum Instantaneous Charge Current Limit (Extended Range): The maximum instantaneous current flow limit into this High Voltage Energy Storage Pack instance. This parameter is defined from the high voltage energy storage pack's point of view...";
CM_ SG_ 2364760574 Hvsp11NmnlDshrgCrrntLmt "HVESP11 Nominal Discharge Current Limit: The nominal current flow limit out of the High Voltage Energy Storage Pack instance. This limit is a preferred boundary for normal operation. Operating within this limit reduces negative impacts on battery li...";
CM_ SG_ 2364760574 Hvsp11NmnlChrgCrrntLmt "HVESP11 Nominal Charge Current Limit: The nominal current flow limit into the High Voltage Energy Storage Pack instance. This limit is a preferred boundary for normal operation. Operating within this limit reduces negative impacts on battery life or...";
CM_ BO_ 2364760830 "High Voltage Energy Storage Pack 12 Data 12";
CM_ SG_ 2364760830 Hvsp12AvllDshrgPwrExtnddRng "HVESP12 Available Discharge Power (Extended Range): The rate at which this High Voltage Energy Storage Pack instance can currently provide energy for propulsion or other uses.This parameter is for one of multiple packs in an HVESS. If there is only o...";
CM_ SG_ 2364760830 Hvsp12AvllChrgPwrExtnddRng "HVESP12 Available Charge Power (Extended Range): The rate at which this High Voltage Energy Storage Pack instance can currently receive energy from a regenerative or recharging system.This parameter is for one of multiple packs in an HVESS. If there ...";
CM_ SG_ 2364760830 Hvsp12VltgLvlExtnddRng "HVESP12 Voltage Level (Extended Range): The voltage level of this High Voltage Energy Storage Pack instance. This parameter should be synchronized with SPN 22603 (HVESP12 Current (Extended Range)) such that a realized power value can be calculated. I...";
CM_ SG_ 2364760830 Hvesp12CurrentExtendedRange "HVESP12 Current (Extended Range): The current in or out of this High Voltage Energy Storage Pack instance. This parameter should be synchronized with SPN 22602 (HVESP12 Voltage Level (Extended Range)) such that a realized power value can be calculate...";
CM_ BO_ 2364761086 "High Voltage Energy Storage Pack 12 Data 13";
CM_ SG_ 2364761086 Hvsp12MxIsttsDsCtLtExtddR "HVESP12 Maximum Instantaneous Discharge Current Limit (Extended Range): The maximum instantaneous current flow limit out of this High Voltage Energy Storage Pack instance. This parameter is defined from the high voltage energy storage pack's point of...";
CM_ SG_ 2364761086 Hvsp12MxIsttsCCtLtExtddR "HVESP12 Maximum Instantaneous Charge Current Limit (Extended Range): The maximum instantaneous current flow limit into this High Voltage Energy Storage Pack instance. This parameter is defined from the high voltage energy storage pack's point of view...";
CM_ SG_ 2364761086 Hvsp12NmnlDshrgCrrntLmt "HVESP12 Nominal Discharge Current Limit: The nominal current flow limit out of the High Voltage Energy Storage Pack instance. This limit is a preferred boundary for normal operation. Operating within this limit reduces negative impacts on battery li...";
CM_ SG_ 2364761086 Hvsp12NmnlChrgCrrntLmt "HVESP12 Nominal Charge Current Limit: The nominal current flow limit into the High Voltage Energy Storage Pack instance. This limit is a preferred boundary for normal operation. Operating within this limit reduces negative impacts on battery life or...";
CM_ BO_ 2365203710 "High Voltage Energy Storage System Data 12";
CM_ SG_ 2365203710 HvessIntakeCoolantPressure "HVESS Intake Coolant Pressure: Gage pressure of coolant entering as it enters the High Voltage Energy Storage System.";
CM_ SG_ 2365203710 HvssEstmtdDshrgTmRmnng "HVESS Estimated Discharge Time Remaining: The HVESS discharge time remaining with the current battery state of charge and the average usage of the HVESS. ";
CM_ SG_ 2365203710 HvssEstmtdChrgTmRmnng "HVESS Estimated Charge Time Remaining: The HVESS charge time remaining with the current battery state of charge and the average charging of the HVESS. ";
CM_ SG_ 2365203710 HvssHghVltgExpsrIndtr "HVESS High Voltage Exposure Indicator: This signal indicates the condition and state of the HVESS high voltage exposure detection system (e.g. High Voltage Interlock Loop [HVIL], welded contactor etc.,). The high voltage exposure detection system is ...";
CM_ SG_ 2365203710 HvessPowerHoldRelayStatus "HVESS Power Hold Relay Status: Status of the relay for keep alive power in the HVESS independent of the enable input to the HVESS.  For example, this could allow continued device operation after the keyswitch has turned off.00b = Off01b = On10b = Err...";
CM_ SG_ 2365203710 HvssHghVltgBsPstvPrChrgRlStt "HVESS High-Voltage Bus Positive Pre-Charge Relay State: Position of the high-voltage bus contactor positive pre-charge relay. When this relay is closed, the High Voltage Energy Storage System (or Pack 1 in systems with only one pack) is bringing the ...";
CM_ SG_ 2365203710 HvssHghVltgBsNgtvPrChrgRlStt "HVESS High-Voltage Bus Negative Pre-Charge Relay State: Position of the high-voltage bus contactor negative pre-charge relay. When this relay is closed, the High Voltage Energy Storage System (or Pack 1 in systems with only one pack) is bringing the ...";
CM_ BO_ 2365203966 "High Voltage Energy Storage System Data 13";
CM_ SG_ 2365203966 HvssAvllDshrgPwrExtnddRng "HVESS Available Discharge Power (Extended Range): The rate at which the High Voltage Energy Storage System (or Pack 1 in systems with only onepack) can currently provide energy for propulsion or other uses.This parameter provides HVES system level in...";
CM_ SG_ 2365203966 HvssAvllChrgPwrExtnddRng "HVESS Available Charge Power (Extended Range): The rate at which the High Voltage Energy Storage System (or Pack 1 in systems with only onepack) can currently receive energy from a regenerative or recharging system.This parameter provides HVES system...";
CM_ SG_ 2365203966 HvessVoltageLevelExtendedRange "HVESS Voltage Level (Extended Range): The voltage level of the High Voltage Energy Storage System (or Pack 1 in systems with only one pack). This parameter should be synchronized with SPN 22351 (HVESS Current (Extended Range)) such that a realized po...";
CM_ SG_ 2365203966 HvessCurrentExtendedRange "HVESS Current (Extended Range): The current in or out of the High Voltage Energy Storage System (or Pack 1 in systems with only one pack). This parameter should be synchronized with SPN 22352 (HVESS Voltage Level (Extended Range)) such that a realize...";
CM_ BO_ 2365204222 "High Voltage Energy Storage System Data 14";
CM_ SG_ 2365204222 HvessBusVoltageExtendedRange "HVESS Bus Voltage (Extended Range): The voltage level of the high voltage bus, as measured by the High Voltage Energy Storage System (or Pack 1 in systems with only one pack) on the bus side (not the battery side) of its contactors.This parameter pro...";
CM_ SG_ 2365204222 HvssMxIsttsDsCtLtExtddR "HVESS Maximum Instantaneous Discharge Current Limit (Extended Range): The maximum instantaneous current flow limit out of the High Voltage Energy Storage System (or Pack 1 in systems with only one pack). This parameter is defined from the high voltag...";
CM_ SG_ 2365204222 HvssMxIsttsCCtLtExtddR "HVESS Maximum Instantaneous Charge Current Limit (Extended Range): The maximum instantaneous current flow limit into the High Voltage Energy Storage System (or Pack 1 in systems with only one pack). This parameter is defined from the high voltage ene...";
CM_ SG_ 2365204222 HvssMnmmDshrgVltgLmt "HVESS Minimum Discharge Voltage Limit: The minimum voltage level allowed while discharging the High Voltage Energy Storage System (or Pack 1 in systems with only one pack). If this parameter is not supported, the minimum discharge voltage should be l...";
CM_ BO_ 2365204478 "High Voltage Energy Storage Pack 1 Internal Status 1";
CM_ SG_ 2365204478 Hvsp1HghVltgIntrnlNgtvCnttr1Stt "HVESP1 High-Voltage Internal (Negative) Contactor 1 State: Position of the High Voltage Energy Storage  Pack 1 Internal 1 negative side bus contactor. Refer to PGN description for usage of this SPN00b = Contactor Open01b = Contactor Closed10b = Error...";
CM_ SG_ 2365204478 Hvsp1HghVltgIntrnlNgtvCnttr2Stt "HVESP1 High-Voltage Internal (Negative) Contactor 2 State: Position of the High Voltage Energy Storage  Pack 1 Internal 2 negative side bus contactor. Refer to PGN description for usage of this SPN00b = Contactor Open01b = Contactor Closed10b = Error...";
CM_ SG_ 2365204478 Hvsp1HghVltgIntrnlNgtvCnttr3Stt "HVESP1 High-Voltage Internal (Negative) Contactor 3 State: Position of the High Voltage Energy Storage  Pack 1 Internal 3 negative side bus contactor. Refer to PGN description for usage of this SPN00b = Contactor Open01b = Contactor Closed10b = Error...";
CM_ SG_ 2365204478 Hvsp1HghVltgIntrnlNgtvCnttr4Stt "HVESP1 High-Voltage Internal (Negative) Contactor 4 State: Position of the High Voltage Energy Storage  Pack 1 Internal 4 negative side bus contactor. Refer to PGN description for usage of this SPN00b = Contactor Open01b = Contactor Closed10b = Error...";
CM_ SG_ 2365204478 Hvsp1HghVltgIntrnlNgtvCnttr5Stt "HVESP1 High-Voltage Internal (Negative) Contactor 5 State: Position of the High Voltage Energy Storage  Pack 1 Internal 5 negative side bus contactor. Refer to PGN description for usage of this SPN00b = Contactor Open01b = Contactor Closed10b = Error...";
CM_ SG_ 2365204478 Hvsp1HghVltgIntrnlNgtvCnttr6Stt "HVESP1 High-Voltage Internal (Negative) Contactor 6 State: Position of the High Voltage Energy Storage  Pack 1 Internal 6 negative side bus contactor. Refer to PGN description for usage of this SPN00b = Contactor Open01b = Contactor Closed10b = Error...";
CM_ SG_ 2365204478 Hvsp1HghVltgIntrnlNgtvCnttr7Stt "HVESP1 High-Voltage Internal (Negative) Contactor 7 State: Position of the High Voltage Energy Storage  Pack 1 Internal 7 negative side bus contactor. Refer to PGN description for usage of this SPN00b = Contactor Open01b = Contactor Closed10b = Error...";
CM_ SG_ 2365204478 Hvsp1HghVltgIntrnlNgtvCnttr8Stt "HVESP1 High-Voltage Internal (Negative) Contactor 8 State: Position of the High Voltage Energy Storage  Pack 1 Internal 8 negative side bus contactor. Refer to PGN description for usage of this SPN00b = Contactor Open01b = Contactor Closed10b = Error...";
CM_ SG_ 2365204478 Hvsp1HghVltgIntrnlPstvCnttr1Stt "HVESP1 High-Voltage Internal (Positive) Contactor 1 State: Position of the High Voltage Energy Storage Pack 1 Internal 1 positive side bus contactor.Refer to PGN description for usage of this SPN00b = Contactor Open01b = Contactor Closed10b = Error11...";
CM_ SG_ 2365204478 Hvsp1HghVltgIntrnlPstvCnttr2Stt "HVESP1 High-Voltage Internal (Positive) Contactor 2 State: Position of the High Voltage Energy Storage Pack 1 Internal 2 positive side bus contactor.Refer to PGN description for usage of this SPN00b = Contactor Open01b = Contactor Closed10b = Error11...";
CM_ SG_ 2365204478 Hvsp1HghVltgIntrnlPstvCnttr3Stt "HVESP1 High-Voltage Internal (Positive) Contactor 3 State: Position of the High Voltage Energy Storage Pack 1 Internal 3 positive side bus contactor.Refer to PGN description for usage of this SPN00b = Contactor Open01b = Contactor Closed10b = Error11...";
CM_ SG_ 2365204478 Hvsp1HghVltgIntrnlPstvCnttr4Stt "HVESP1 High-Voltage Internal (Positive) Contactor 4 State: Position of the High Voltage Energy Storage Pack 1 Internal 4 positive side bus contactor.Refer to PGN description for usage of this SPN00b = Contactor Open01b = Contactor Closed10b = Error11...";
CM_ SG_ 2365204478 Hvsp1HghVltgIntrnlPstvCnttr5Stt "HVESP1 High-Voltage Internal (Positive) Contactor 5 State: Position of the High Voltage Energy Storage Pack 1 Internal 5 positive side bus contactor.Refer to PGN description for usage of this SPN00b = Contactor Open01b = Contactor Closed10b = Error11...";
CM_ SG_ 2365204478 Hvsp1HghVltgIntrnlPstvCnttr6Stt "HVESP1 High-Voltage Internal (Positive) Contactor 6 State: Position of the High Voltage Energy Storage Pack 1 Internal 6 positive side bus contactor.Refer to PGN description for usage of this SPN00b = Contactor Open01b = Contactor Closed10b = Error11...";
CM_ SG_ 2365204478 Hvsp1HghVltgIntrnlPstvCnttr7Stt "HVESP1 High-Voltage Internal (Positive) Contactor 7 State: Position of the High Voltage Energy Storage Pack 1 Internal 7 positive side bus contactor.Refer to PGN description for usage of this SPN00b = Contactor Open01b = Contactor Closed10b = Error11...";
CM_ SG_ 2365204478 Hvsp1HghVltgIntrnlPstvCnttr8Stt "HVESP1 High-Voltage Internal (Positive) Contactor 8 State: Position of the High Voltage Energy Storage Pack 1 Internal 8 positive side bus contactor.Refer to PGN description for usage of this SPN00b = Contactor Open01b = Contactor Closed10b = Error11...";
CM_ BO_ 2365204734 "High Voltage Energy Storage Pack 2 Internal Status 1";
CM_ SG_ 2365204734 Hvsp2HghVltgIntrnlNgtvCnttr1Stt "HVESP2 High-Voltage Internal (Negative) Contactor 1 State: Position of the High Voltage Energy Storage  Pack 2 Internal 1 negative side bus contactor. Refer to PGN description for usage of this SPN00b = Contactor Open01b = Contactor Closed10b = Error...";
CM_ SG_ 2365204734 Hvsp2HghVltgIntrnlNgtvCnttr2Stt "HVESP2 High-Voltage Internal (Negative) Contactor 2 State: Position of the High Voltage Energy Storage  Pack 2 Internal 2 negative side bus contactor. Refer to PGN description for usage of this SPN00b = Contactor Open01b = Contactor Closed10b = Error...";
CM_ SG_ 2365204734 Hvsp2HghVltgIntrnlNgtvCnttr3Stt "HVESP2 High-Voltage Internal (Negative) Contactor 3 State: Position of the High Voltage Energy Storage  Pack 2 Internal 3 negative side bus contactor. Refer to PGN description for usage of this SPN00b = Contactor Open01b = Contactor Closed10b = Error...";
CM_ SG_ 2365204734 Hvsp2HghVltgIntrnlNgtvCnttr4Stt "HVESP2 High-Voltage Internal (Negative) Contactor 4 State: Position of the High Voltage Energy Storage  Pack 2 Internal 4 negative side bus contactor. Refer to PGN description for usage of this SPN00b = Contactor Open01b = Contactor Closed10b = Error...";
CM_ SG_ 2365204734 Hvsp2HghVltgIntrnlNgtvCnttr5Stt "HVESP2 High-Voltage Internal (Negative) Contactor 5 State: Position of the High Voltage Energy Storage  Pack 2 Internal 5 negative side bus contactor. Refer to PGN description for usage of this SPN00b = Contactor Open01b = Contactor Closed10b = Error...";
CM_ SG_ 2365204734 Hvsp2HghVltgIntrnlNgtvCnttr6Stt "HVESP2 High-Voltage Internal (Negative) Contactor 6 State: Position of the High Voltage Energy Storage  Pack 2 Internal 6 negative side bus contactor. Refer to PGN description for usage of this SPN00b = Contactor Open01b = Contactor Closed10b = Error...";
CM_ SG_ 2365204734 Hvsp2HghVltgIntrnlNgtvCnttr7Stt "HVESP2 High-Voltage Internal (Negative) Contactor 7 State: Position of the High Voltage Energy Storage  Pack 2 Internal 7 negative side bus contactor. Refer to PGN description for usage of this SPN00b = Contactor Open01b = Contactor Closed10b = Error...";
CM_ SG_ 2365204734 Hvsp2HghVltgIntrnlNgtvCnttr8Stt "HVESP2 High-Voltage Internal (Negative) Contactor 8 State: Position of the High Voltage Energy Storage  Pack 2 Internal 8 negative side bus contactor. Refer to PGN description for usage of this SPN00b = Contactor Open01b = Contactor Closed10b = Error...";
CM_ SG_ 2365204734 Hvsp2HghVltgIntrnlPstvCnttr1Stt "HVESP2 High-Voltage Internal (Positive) Contactor 1 State: Position of the High Voltage Energy Storage Pack 2 Internal 1 positive side bus contactor.Refer to PGN description for usage of this SPN00b = Contactor Open01b = Contactor Closed10b = Error11...";
CM_ SG_ 2365204734 Hvsp2HghVltgIntrnlPstvCnttr2Stt "HVESP2 High-Voltage Internal (Positive) Contactor 2 State: Position of the High Voltage Energy Storage Pack 2 Internal 2 positive side bus contactor.Refer to PGN description for usage of this SPN00b = Contactor Open01b = Contactor Closed10b = Error11...";
CM_ SG_ 2365204734 Hvsp2HghVltgIntrnlPstvCnttr3Stt "HVESP2 High-Voltage Internal (Positive) Contactor 3 State: Position of the High Voltage Energy Storage Pack 2 Internal 3 positive side bus contactor.Refer to PGN description for usage of this SPN00b = Contactor Open01b = Contactor Closed10b = Error11...";
CM_ SG_ 2365204734 Hvsp2HghVltgIntrnlPstvCnttr4Stt "HVESP2 High-Voltage Internal (Positive) Contactor 4 State: Position of the High Voltage Energy Storage Pack 2 Internal 4 positive side bus contactor.Refer to PGN description for usage of this SPN00b = Contactor Open01b = Contactor Closed10b = Error11...";
CM_ SG_ 2365204734 Hvsp2HghVltgIntrnlPstvCnttr5Stt "HVESP2 High-Voltage Internal (Positive) Contactor 5 State: Position of the High Voltage Energy Storage Pack 2 Internal 5 positive side bus contactor.Refer to PGN description for usage of this SPN00b = Contactor Open01b = Contactor Closed10b = Error11...";
CM_ SG_ 2365204734 Hvsp2HghVltgIntrnlPstvCnttr6Stt "HVESP2 High-Voltage Internal (Positive) Contactor 6 State: Position of the High Voltage Energy Storage Pack 2 Internal 6 positive side bus contactor.Refer to PGN description for usage of this SPN00b = Contactor Open01b = Contactor Closed10b = Error11...";
CM_ SG_ 2365204734 Hvsp2HghVltgIntrnlPstvCnttr7Stt "HVESP2 High-Voltage Internal (Positive) Contactor 7 State: Position of the High Voltage Energy Storage Pack 2 Internal 7 positive side bus contactor.Refer to PGN description for usage of this SPN00b = Contactor Open01b = Contactor Closed10b = Error11...";
CM_ SG_ 2365204734 Hvsp2HghVltgIntrnlPstvCnttr8Stt "HVESP2 High-Voltage Internal (Positive) Contactor 8 State: Position of the High Voltage Energy Storage Pack 2 Internal 8 positive side bus contactor.Refer to PGN description for usage of this SPN00b = Contactor Open01b = Contactor Closed10b = Error11...";
CM_ BO_ 2365204990 "High Voltage Energy Storage Pack 3 Internal Status 1";
CM_ SG_ 2365204990 Hvsp3HghVltgIntrnlNgtvCnttr1Stt "HVESP3 High-Voltage Internal (Negative) Contactor 1 State: Position of the High Voltage Energy Storage  Pack 3 Internal 1 negative side bus contactor. Refer to PGN description for usage of this SPN00b = Contactor Open01b = Contactor Closed10b = Error...";
CM_ SG_ 2365204990 Hvsp3HghVltgIntrnlNgtvCnttr2Stt "HVESP3 High-Voltage Internal (Negative) Contactor 2 State: Position of the High Voltage Energy Storage  Pack 3 Internal 2 negative side bus contactor. Refer to PGN description for usage of this SPN00b = Contactor Open01b = Contactor Closed10b = Error...";
CM_ SG_ 2365204990 Hvsp3HghVltgIntrnlNgtvCnttr3Stt "HVESP3 High-Voltage Internal (Negative) Contactor 3 State: Position of the High Voltage Energy Storage  Pack 3 Internal 3 negative side bus contactor. Refer to PGN description for usage of this SPN00b = Contactor Open01b = Contactor Closed10b = Error...";
CM_ SG_ 2365204990 Hvsp3HghVltgIntrnlNgtvCnttr4Stt "HVESP3 High-Voltage Internal (Negative) Contactor 4 State: Position of the High Voltage Energy Storage  Pack 3 Internal 4 negative side bus contactor. Refer to PGN description for usage of this SPN00b = Contactor Open01b = Contactor Closed10b = Error...";
CM_ SG_ 2365204990 Hvsp3HghVltgIntrnlNgtvCnttr5Stt "HVESP3 High-Voltage Internal (Negative) Contactor 5 State: Position of the High Voltage Energy Storage  Pack 3 Internal 5 negative side bus contactor. Refer to PGN description for usage of this SPN00b = Contactor Open01b = Contactor Closed10b = Error...";
CM_ SG_ 2365204990 Hvsp3HghVltgIntrnlNgtvCnttr6Stt "HVESP3 High-Voltage Internal (Negative) Contactor 6 State: Position of the High Voltage Energy Storage  Pack 3 Internal 6 negative side bus contactor. Refer to PGN description for usage of this SPN00b = Contactor Open01b = Contactor Closed10b = Error...";
CM_ SG_ 2365204990 Hvsp3HghVltgIntrnlNgtvCnttr7Stt "HVESP3 High-Voltage Internal (Negative) Contactor 7 State: Position of the High Voltage Energy Storage  Pack 3 Internal 7 negative side bus contactor. Refer to PGN description for usage of this SPN00b = Contactor Open01b = Contactor Closed10b = Error...";
CM_ SG_ 2365204990 Hvsp3HghVltgIntrnlNgtvCnttr8Stt "HVESP3 High-Voltage Internal (Negative) Contactor 8 State: Position of the High Voltage Energy Storage  Pack 3 Internal 8 negative side bus contactor. Refer to PGN description for usage of this SPN00b = Contactor Open01b = Contactor Closed10b = Error...";
CM_ SG_ 2365204990 Hvsp3HghVltgIntrnlPstvCnttr1Stt "HVESP3 High-Voltage Internal (Positive) Contactor 1 State: Position of the High Voltage Energy Storage Pack 3 Internal 1 positive side bus contactor.Refer to PGN description for usage of this SPN00b = Contactor Open01b = Contactor Closed10b = Error11...";
CM_ SG_ 2365204990 Hvsp3HghVltgIntrnlPstvCnttr2Stt "HVESP3 High-Voltage Internal (Positive) Contactor 2 State: Position of the High Voltage Energy Storage Pack 3 Internal 2 positive side bus contactor.Refer to PGN description for usage of this SPN00b = Contactor Open01b = Contactor Closed10b = Error11...";
CM_ SG_ 2365204990 Hvsp3HghVltgIntrnlPstvCnttr3Stt "HVESP3 High-Voltage Internal (Positive) Contactor 3 State: Position of the High Voltage Energy Storage Pack 3 Internal 3 positive side bus contactor.Refer to PGN description for usage of this SPN00b = Contactor Open01b = Contactor Closed10b = Error11...";
CM_ SG_ 2365204990 Hvsp3HghVltgIntrnlPstvCnttr4Stt "HVESP3 High-Voltage Internal (Positive) Contactor 4 State: Position of the High Voltage Energy Storage Pack 3 Internal 4 positive side bus contactor.Refer to PGN description for usage of this SPN00b = Contactor Open01b = Contactor Closed10b = Error11...";
CM_ SG_ 2365204990 Hvsp3HghVltgIntrnlPstvCnttr5Stt "HVESP3 High-Voltage Internal (Positive) Contactor 5 State: Position of the High Voltage Energy Storage Pack 3 Internal 5 positive side bus contactor.Refer to PGN description for usage of this SPN00b = Contactor Open01b = Contactor Closed10b = Error11...";
CM_ SG_ 2365204990 Hvsp3HghVltgIntrnlPstvCnttr6Stt "HVESP3 High-Voltage Internal (Positive) Contactor 6 State: Position of the High Voltage Energy Storage Pack 3 Internal 6 positive side bus contactor.Refer to PGN description for usage of this SPN00b = Contactor Open01b = Contactor Closed10b = Error11...";
CM_ SG_ 2365204990 Hvsp3HghVltgIntrnlPstvCnttr7Stt "HVESP3 High-Voltage Internal (Positive) Contactor 7 State: Position of the High Voltage Energy Storage Pack 3 Internal 7 positive side bus contactor.Refer to PGN description for usage of this SPN00b = Contactor Open01b = Contactor Closed10b = Error11...";
CM_ SG_ 2365204990 Hvsp3HghVltgIntrnlPstvCnttr8Stt "HVESP3 High-Voltage Internal (Positive) Contactor 8 State: Position of the High Voltage Energy Storage Pack 3 Internal 8 positive side bus contactor.Refer to PGN description for usage of this SPN00b = Contactor Open01b = Contactor Closed10b = Error11...";
CM_ BO_ 2365205246 "High Voltage Energy Storage Pack 4 Internal Status 1";
CM_ SG_ 2365205246 Hvsp4HghVltgIntrnlNgtvCnttr1Stt "HVESP4 High-Voltage Internal (Negative) Contactor 1 State: Position of the High Voltage Energy Storage  Pack 4 Internal 1 negative side bus contactor. Refer to PGN description for usage of this SPN00b = Contactor Open01b = Contactor Closed10b = Error...";
CM_ SG_ 2365205246 Hvsp4HghVltgIntrnlNgtvCnttr2Stt "HVESP4 High-Voltage Internal (Negative) Contactor 2 State: Position of the High Voltage Energy Storage  Pack 4 Internal 2 negative side bus contactor. Refer to PGN description for usage of this SPN00b = Contactor Open01b = Contactor Closed10b = Error...";
CM_ SG_ 2365205246 Hvsp4HghVltgIntrnlNgtvCnttr3Stt "HVESP4 High-Voltage Internal (Negative) Contactor 3 State: Position of the High Voltage Energy Storage  Pack 4 Internal 3 negative side bus contactor. Refer to PGN description for usage of this SPN00b = Contactor Open01b = Contactor Closed10b = Error...";
CM_ SG_ 2365205246 Hvsp4HghVltgIntrnlNgtvCnttr4Stt "HVESP4 High-Voltage Internal (Negative) Contactor 4 State: Position of the High Voltage Energy Storage  Pack 4 Internal 4 negative side bus contactor. Refer to PGN description for usage of this SPN00b = Contactor Open01b = Contactor Closed10b = Error...";
CM_ SG_ 2365205246 Hvsp4HghVltgIntrnlNgtvCnttr5Stt "HVESP4 High-Voltage Internal (Negative) Contactor 5 State: Position of the High Voltage Energy Storage  Pack 4 Internal 5 negative side bus contactor. Refer to PGN description for usage of this SPN00b = Contactor Open01b = Contactor Closed10b = Error...";
CM_ SG_ 2365205246 Hvsp4HghVltgIntrnlNgtvCnttr6Stt "HVESP4 High-Voltage Internal (Negative) Contactor 6 State: Position of the High Voltage Energy Storage  Pack 4 Internal 6 negative side bus contactor. Refer to PGN description for usage of this SPN00b = Contactor Open01b = Contactor Closed10b = Error...";
CM_ SG_ 2365205246 Hvsp4HghVltgIntrnlNgtvCnttr7Stt "HVESP4 High-Voltage Internal (Negative) Contactor 7 State: Position of the High Voltage Energy Storage  Pack 4 Internal 7 negative side bus contactor. Refer to PGN description for usage of this SPN00b = Contactor Open01b = Contactor Closed10b = Error...";
CM_ SG_ 2365205246 Hvsp4HghVltgIntrnlNgtvCnttr8Stt "HVESP4 High-Voltage Internal (Negative) Contactor 8 State: Position of the High Voltage Energy Storage  Pack 4 Internal 8 negative side bus contactor. Refer to PGN description for usage of this SPN00b = Contactor Open01b = Contactor Closed10b = Error...";
CM_ SG_ 2365205246 Hvsp4HghVltgIntrnlPstvCnttr1Stt "HVESP4 High-Voltage Internal (Positive) Contactor 1 State: Position of the High Voltage Energy Storage Pack 4 Internal 1 positive side bus contactor.Refer to PGN description for usage of this SPN00b = Contactor Open01b = Contactor Closed10b = Error11...";
CM_ SG_ 2365205246 Hvsp4HghVltgIntrnlPstvCnttr2Stt "HVESP4 High-Voltage Internal (Positive) Contactor 2 State: Position of the High Voltage Energy Storage Pack 4 Internal 2 positive side bus contactor.Refer to PGN description for usage of this SPN00b = Contactor Open01b = Contactor Closed10b = Error11...";
CM_ SG_ 2365205246 Hvsp4HghVltgIntrnlPstvCnttr3Stt "HVESP4 High-Voltage Internal (Positive) Contactor 3 State: Position of the High Voltage Energy Storage Pack 4 Internal 3 positive side bus contactor.Refer to PGN description for usage of this SPN00b = Contactor Open01b = Contactor Closed10b = Error11...";
CM_ SG_ 2365205246 Hvsp4HghVltgIntrnlPstvCnttr4Stt "HVESP4 High-Voltage Internal (Positive) Contactor 4 State: Position of the High Voltage Energy Storage Pack 4 Internal 4 positive side bus contactor.Refer to PGN description for usage of this SPN00b = Contactor Open01b = Contactor Closed10b = Error11...";
CM_ SG_ 2365205246 Hvsp4HghVltgIntrnlPstvCnttr5Stt "HVESP4 High-Voltage Internal (Positive) Contactor 5 State: Position of the High Voltage Energy Storage Pack 4 Internal 5 positive side bus contactor.Refer to PGN description for usage of this SPN00b = Contactor Open01b = Contactor Closed10b = Error11...";
CM_ SG_ 2365205246 Hvsp4HghVltgIntrnlPstvCnttr6Stt "HVESP4 High-Voltage Internal (Positive) Contactor 6 State: Position of the High Voltage Energy Storage Pack 4 Internal 6 positive side bus contactor.Refer to PGN description for usage of this SPN00b = Contactor Open01b = Contactor Closed10b = Error11...";
CM_ SG_ 2365205246 Hvsp4HghVltgIntrnlPstvCnttr7Stt "HVESP4 High-Voltage Internal (Positive) Contactor 7 State: Position of the High Voltage Energy Storage Pack 4 Internal 7 positive side bus contactor.Refer to PGN description for usage of this SPN00b = Contactor Open01b = Contactor Closed10b = Error11...";
CM_ SG_ 2365205246 Hvsp4HghVltgIntrnlPstvCnttr8Stt "HVESP4 High-Voltage Internal (Positive) Contactor 8 State: Position of the High Voltage Energy Storage Pack 4 Internal 8 positive side bus contactor.Refer to PGN description for usage of this SPN00b = Contactor Open01b = Contactor Closed10b = Error11...";
CM_ BO_ 2365205502 "High Voltage Energy Storage Pack 5 Internal Status 1";
CM_ SG_ 2365205502 Hvsp5HghVltgIntrnlNgtvCnttr1Stt "HVESP5 High-Voltage Internal (Negative) Contactor 1 State: Position of the High Voltage Energy Storage  Pack 5 Internal 1 negative side bus contactor. Refer to PGN description for usage of this SPN00b = Contactor Open01b = Contactor Closed10b = Error...";
CM_ SG_ 2365205502 Hvsp5HghVltgIntrnlNgtvCnttr2Stt "HVESP5 High-Voltage Internal (Negative) Contactor 2 State: Position of the High Voltage Energy Storage  Pack 5 Internal 2 negative side bus contactor. Refer to PGN description for usage of this SPN00b = Contactor Open01b = Contactor Closed10b = Error...";
CM_ SG_ 2365205502 Hvsp5HghVltgIntrnlNgtvCnttr3Stt "HVESP5 High-Voltage Internal (Negative) Contactor 3 State: Position of the High Voltage Energy Storage  Pack 5 Internal 3 negative side bus contactor. Refer to PGN description for usage of this SPN00b = Contactor Open01b = Contactor Closed10b = Error...";
CM_ SG_ 2365205502 Hvsp5HghVltgIntrnlNgtvCnttr4Stt "HVESP5 High-Voltage Internal (Negative) Contactor 4 State: Position of the High Voltage Energy Storage  Pack 5 Internal 4 negative side bus contactor. Refer to PGN description for usage of this SPN00b = Contactor Open01b = Contactor Closed10b = Error...";
CM_ SG_ 2365205502 Hvsp5HghVltgIntrnlNgtvCnttr5Stt "HVESP5 High-Voltage Internal (Negative) Contactor 5 State: Position of the High Voltage Energy Storage  Pack 5 Internal 5 negative side bus contactor. Refer to PGN description for usage of this SPN00b = Contactor Open01b = Contactor Closed10b = Error...";
CM_ SG_ 2365205502 Hvsp5HghVltgIntrnlNgtvCnttr6Stt "HVESP5 High-Voltage Internal (Negative) Contactor 6 State: Position of the High Voltage Energy Storage  Pack 5 Internal 6 negative side bus contactor. Refer to PGN description for usage of this SPN00b = Contactor Open01b = Contactor Closed10b = Error...";
CM_ SG_ 2365205502 Hvsp5HghVltgIntrnlNgtvCnttr7Stt "HVESP5 High-Voltage Internal (Negative) Contactor 7 State: Position of the High Voltage Energy Storage  Pack 5 Internal 7 negative side bus contactor. Refer to PGN description for usage of this SPN00b = Contactor Open01b = Contactor Closed10b = Error...";
CM_ SG_ 2365205502 Hvsp5HghVltgIntrnlNgtvCnttr8Stt "HVESP5 High-Voltage Internal (Negative) Contactor 8 State: Position of the High Voltage Energy Storage  Pack 5 Internal 8 negative side bus contactor. Refer to PGN description for usage of this SPN00b = Contactor Open01b = Contactor Closed10b = Error...";
CM_ SG_ 2365205502 Hvsp5HghVltgIntrnlPstvCnttr1Stt "HVESP5 High-Voltage Internal (Positive) Contactor 1 State: Position of the High Voltage Energy Storage Pack 5 Internal 1 positive side bus contactor.Refer to PGN description for usage of this SPN00b = Contactor Open01b = Contactor Closed10b = Error11...";
CM_ SG_ 2365205502 Hvsp5HghVltgIntrnlPstvCnttr2Stt "HVESP5 High-Voltage Internal (Positive) Contactor 2 State: Position of the High Voltage Energy Storage Pack 5 Internal 2 positive side bus contactor.Refer to PGN description for usage of this SPN00b = Contactor Open01b = Contactor Closed10b = Error11...";
CM_ SG_ 2365205502 Hvsp5HghVltgIntrnlPstvCnttr3Stt "HVESP5 High-Voltage Internal (Positive) Contactor 3 State: Position of the High Voltage Energy Storage Pack 5 Internal 3 positive side bus contactor.Refer to PGN description for usage of this SPN00b = Contactor Open01b = Contactor Closed10b = Error11...";
CM_ SG_ 2365205502 Hvsp5HghVltgIntrnlPstvCnttr4Stt "HVESP5 High-Voltage Internal (Positive) Contactor 4 State: Position of the High Voltage Energy Storage Pack 5 Internal 4 positive side bus contactor.Refer to PGN description for usage of this SPN00b = Contactor Open01b = Contactor Closed10b = Error11...";
CM_ SG_ 2365205502 Hvsp5HghVltgIntrnlPstvCnttr5Stt "HVESP5 High-Voltage Internal (Positive) Contactor 5 State: Position of the High Voltage Energy Storage Pack 5 Internal 5 positive side bus contactor.Refer to PGN description for usage of this SPN00b = Contactor Open01b = Contactor Closed10b = Error11...";
CM_ SG_ 2365205502 Hvsp5HghVltgIntrnlPstvCnttr6Stt "HVESP5 High-Voltage Internal (Positive) Contactor 6 State: Position of the High Voltage Energy Storage Pack 5 Internal 6 positive side bus contactor.Refer to PGN description for usage of this SPN00b = Contactor Open01b = Contactor Closed10b = Error11...";
CM_ SG_ 2365205502 Hvsp5HghVltgIntrnlPstvCnttr7Stt "HVESP5 High-Voltage Internal (Positive) Contactor 7 State: Position of the High Voltage Energy Storage Pack 5 Internal 7 positive side bus contactor.Refer to PGN description for usage of this SPN00b = Contactor Open01b = Contactor Closed10b = Error11...";
CM_ SG_ 2365205502 Hvsp5HghVltgIntrnlPstvCnttr8Stt "HVESP5 High-Voltage Internal (Positive) Contactor 8 State: Position of the High Voltage Energy Storage Pack 5 Internal 8 positive side bus contactor.Refer to PGN description for usage of this SPN00b = Contactor Open01b = Contactor Closed10b = Error11...";
CM_ BO_ 2365205758 "High Voltage Energy Storage Pack 6 Internal Status 1";
CM_ SG_ 2365205758 Hvsp6HghVltgIntrnlNgtvCnttr1Stt "HVESP6 High-Voltage Internal (Negative) Contactor 1 State: Position of the High Voltage Energy Storage  Pack 6 Internal 1 negative side bus contactor. Refer to PGN description for usage of this SPN00b = Contactor Open01b = Contactor Closed10b = Error...";
CM_ SG_ 2365205758 Hvsp6HghVltgIntrnlNgtvCnttr2Stt "HVESP6 High-Voltage Internal (Negative) Contactor 2 State: Position of the High Voltage Energy Storage  Pack 6 Internal 2 negative side bus contactor. Refer to PGN description for usage of this SPN00b = Contactor Open01b = Contactor Closed10b = Error...";
CM_ SG_ 2365205758 Hvsp6HghVltgIntrnlNgtvCnttr3Stt "HVESP6 High-Voltage Internal (Negative) Contactor 3 State: Position of the High Voltage Energy Storage  Pack 6 Internal 3 negative side bus contactor. Refer to PGN description for usage of this SPN00b = Contactor Open01b = Contactor Closed10b = Error...";
CM_ SG_ 2365205758 Hvsp6HghVltgIntrnlNgtvCnttr4Stt "HVESP6 High-Voltage Internal (Negative) Contactor 4 State: Position of the High Voltage Energy Storage  Pack 6 Internal 4 negative side bus contactor. Refer to PGN description for usage of this SPN00b = Contactor Open01b = Contactor Closed10b = Error...";
CM_ SG_ 2365205758 Hvsp6HghVltgIntrnlNgtvCnttr5Stt "HVESP6 High-Voltage Internal (Negative) Contactor 5 State: Position of the High Voltage Energy Storage  Pack 6 Internal 5 negative side bus contactor. Refer to PGN description for usage of this SPN00b = Contactor Open01b = Contactor Closed10b = Error...";
CM_ SG_ 2365205758 Hvsp6HghVltgIntrnlNgtvCnttr6Stt "HVESP6 High-Voltage Internal (Negative) Contactor 6 State: Position of the High Voltage Energy Storage  Pack 6 Internal 6 negative side bus contactor. Refer to PGN description for usage of this SPN00b = Contactor Open01b = Contactor Closed10b = Error...";
CM_ SG_ 2365205758 Hvsp6HghVltgIntrnlNgtvCnttr7Stt "HVESP6 High-Voltage Internal (Negative) Contactor 7 State: Position of the High Voltage Energy Storage  Pack 6 Internal 7 negative side bus contactor. Refer to PGN description for usage of this SPN00b = Contactor Open01b = Contactor Closed10b = Error...";
CM_ SG_ 2365205758 Hvsp6HghVltgIntrnlNgtvCnttr8Stt "HVESP6 High-Voltage Internal (Negative) Contactor 8 State: Position of the High Voltage Energy Storage  Pack 6 Internal 8 negative side bus contactor. Refer to PGN description for usage of this SPN00b = Contactor Open01b = Contactor Closed10b = Error...";
CM_ SG_ 2365205758 Hvsp6HghVltgIntrnlPstvCnttr1Stt "HVESP6 High-Voltage Internal (Positive) Contactor 1 State: Position of the High Voltage Energy Storage Pack 6 Internal 1 positive side bus contactor.Refer to PGN description for usage of this SPN00b = Contactor Open01b = Contactor Closed10b = Error11...";
CM_ SG_ 2365205758 Hvsp6HghVltgIntrnlPstvCnttr2Stt "HVESP6 High-Voltage Internal (Positive) Contactor 2 State: Position of the High Voltage Energy Storage Pack 6 Internal 2 positive side bus contactor.Refer to PGN description for usage of this SPN00b = Contactor Open01b = Contactor Closed10b = Error11...";
CM_ SG_ 2365205758 Hvsp6HghVltgIntrnlPstvCnttr3Stt "HVESP6 High-Voltage Internal (Positive) Contactor 3 State: Position of the High Voltage Energy Storage Pack 6 Internal 3 positive side bus contactor.Refer to PGN description for usage of this SPN00b = Contactor Open01b = Contactor Closed10b = Error11...";
CM_ SG_ 2365205758 Hvsp6HghVltgIntrnlPstvCnttr4Stt "HVESP6 High-Voltage Internal (Positive) Contactor 4 State: Position of the High Voltage Energy Storage Pack 6 Internal 4 positive side bus contactor.Refer to PGN description for usage of this SPN00b = Contactor Open01b = Contactor Closed10b = Error11...";
CM_ SG_ 2365205758 Hvsp6HghVltgIntrnlPstvCnttr5Stt "HVESP6 High-Voltage Internal (Positive) Contactor 5 State: Position of the High Voltage Energy Storage Pack 6 Internal 5 positive side bus contactor.Refer to PGN description for usage of this SPN00b = Contactor Open01b = Contactor Closed10b = Error11...";
CM_ SG_ 2365205758 Hvsp6HghVltgIntrnlPstvCnttr6Stt "HVESP6 High-Voltage Internal (Positive) Contactor 6 State: Position of the High Voltage Energy Storage Pack 6 Internal 6 positive side bus contactor.Refer to PGN description for usage of this SPN00b = Contactor Open01b = Contactor Closed10b = Error11...";
CM_ SG_ 2365205758 Hvsp6HghVltgIntrnlPstvCnttr7Stt "HVESP6 High-Voltage Internal (Positive) Contactor 7 State: Position of the High Voltage Energy Storage Pack 6 Internal 7 positive side bus contactor.Refer to PGN description for usage of this SPN00b = Contactor Open01b = Contactor Closed10b = Error11...";
CM_ SG_ 2365205758 Hvsp6HghVltgIntrnlPstvCnttr8Stt "HVESP6 High-Voltage Internal (Positive) Contactor 8 State: Position of the High Voltage Energy Storage Pack 6 Internal 8 positive side bus contactor.Refer to PGN description for usage of this SPN00b = Contactor Open01b = Contactor Closed10b = Error11...";
CM_ BO_ 2365206014 "High Voltage Energy Storage Pack 7 Internal Status 1";
CM_ SG_ 2365206014 Hvsp7HghVltgIntrnlNgtvCnttr1Stt "HVESP7 High-Voltage Internal (Negative) Contactor 1 State: Position of the High Voltage Energy Storage  Pack 7 Internal 1 negative side bus contactor. Refer to PGN description for usage of this SPN00b = Contactor Open01b = Contactor Closed10b = Error...";
CM_ SG_ 2365206014 Hvsp7HghVltgIntrnlNgtvCnttr2Stt "HVESP7 High-Voltage Internal (Negative) Contactor 2 State: Position of the High Voltage Energy Storage  Pack 7 Internal 2 negative side bus contactor. Refer to PGN description for usage of this SPN00b = Contactor Open01b = Contactor Closed10b = Error...";
CM_ SG_ 2365206014 Hvsp7HghVltgIntrnlNgtvCnttr3Stt "HVESP7 High-Voltage Internal (Negative) Contactor 3 State: Position of the High Voltage Energy Storage  Pack 7 Internal 3 negative side bus contactor. Refer to PGN description for usage of this SPN00b = Contactor Open01b = Contactor Closed10b = Error...";
CM_ SG_ 2365206014 Hvsp7HghVltgIntrnlNgtvCnttr4Stt "HVESP7 High-Voltage Internal (Negative) Contactor 4 State: Position of the High Voltage Energy Storage  Pack 7 Internal 4 negative side bus contactor. Refer to PGN description for usage of this SPN00b = Contactor Open01b = Contactor Closed10b = Error...";
CM_ SG_ 2365206014 Hvsp7HghVltgIntrnlNgtvCnttr5Stt "HVESP7 High-Voltage Internal (Negative) Contactor 5 State: Position of the High Voltage Energy Storage  Pack 7 Internal 5 negative side bus contactor. Refer to PGN description for usage of this SPN00b = Contactor Open01b = Contactor Closed10b = Error...";
CM_ SG_ 2365206014 Hvsp7HghVltgIntrnlNgtvCnttr6Stt "HVESP7 High-Voltage Internal (Negative) Contactor 6 State: Position of the High Voltage Energy Storage  Pack 7 Internal 6 negative side bus contactor. Refer to PGN description for usage of this SPN00b = Contactor Open01b = Contactor Closed10b = Error...";
CM_ SG_ 2365206014 Hvsp7HghVltgIntrnlNgtvCnttr7Stt "HVESP7 High-Voltage Internal (Negative) Contactor 7 State: Position of the High Voltage Energy Storage  Pack 7 Internal 7 negative side bus contactor. Refer to PGN description for usage of this SPN00b = Contactor Open01b = Contactor Closed10b = Error...";
CM_ SG_ 2365206014 Hvsp7HghVltgIntrnlNgtvCnttr8Stt "HVESP7 High-Voltage Internal (Negative) Contactor 8 State: Position of the High Voltage Energy Storage  Pack 7 Internal 8 negative side bus contactor. Refer to PGN description for usage of this SPN00b = Contactor Open01b = Contactor Closed10b = Error...";
CM_ SG_ 2365206014 Hvsp7HghVltgIntrnlPstvCnttr1Stt "HVESP7 High-Voltage Internal (Positive) Contactor 1 State: Position of the High Voltage Energy Storage Pack 7 Internal 1 positive side bus contactor.Refer to PGN description for usage of this SPN00b = Contactor Open01b = Contactor Closed10b = Error11...";
CM_ SG_ 2365206014 Hvsp7HghVltgIntrnlPstvCnttr2Stt "HVESP7 High-Voltage Internal (Positive) Contactor 2 State: Position of the High Voltage Energy Storage Pack 7 Internal 2 positive side bus contactor.Refer to PGN description for usage of this SPN00b = Contactor Open01b = Contactor Closed10b = Error11...";
CM_ SG_ 2365206014 Hvsp7HghVltgIntrnlPstvCnttr3Stt "HVESP7 High-Voltage Internal (Positive) Contactor 3 State: Position of the High Voltage Energy Storage Pack 7 Internal 3 positive side bus contactor.Refer to PGN description for usage of this SPN00b = Contactor Open01b = Contactor Closed10b = Error11...";
CM_ SG_ 2365206014 Hvsp7HghVltgIntrnlPstvCnttr4Stt "HVESP7 High-Voltage Internal (Positive) Contactor 4 State: Position of the High Voltage Energy Storage Pack 7 Internal 4 positive side bus contactor.Refer to PGN description for usage of this SPN00b = Contactor Open01b = Contactor Closed10b = Error11...";
CM_ SG_ 2365206014 Hvsp7HghVltgIntrnlPstvCnttr5Stt "HVESP7 High-Voltage Internal (Positive) Contactor 5 State: Position of the High Voltage Energy Storage Pack 7 Internal 5 positive side bus contactor.Refer to PGN description for usage of this SPN00b = Contactor Open01b = Contactor Closed10b = Error11...";
CM_ SG_ 2365206014 Hvsp7HghVltgIntrnlPstvCnttr6Stt "HVESP7 High-Voltage Internal (Positive) Contactor 6 State: Position of the High Voltage Energy Storage Pack 7 Internal 6 positive side bus contactor.Refer to PGN description for usage of this SPN00b = Contactor Open01b = Contactor Closed10b = Error11...";
CM_ SG_ 2365206014 Hvsp7HghVltgIntrnlPstvCnttr7Stt "HVESP7 High-Voltage Internal (Positive) Contactor 7 State: Position of the High Voltage Energy Storage Pack 7 Internal 7 positive side bus contactor.Refer to PGN description for usage of this SPN00b = Contactor Open01b = Contactor Closed10b = Error11...";
CM_ SG_ 2365206014 Hvsp7HghVltgIntrnlPstvCnttr8Stt "HVESP7 High-Voltage Internal (Positive) Contactor 8 State: Position of the High Voltage Energy Storage Pack 7 Internal 8 positive side bus contactor.Refer to PGN description for usage of this SPN00b = Contactor Open01b = Contactor Closed10b = Error11...";
CM_ BO_ 2365206270 "High Voltage Energy Storage Pack 8 Internal Status 1";
CM_ SG_ 2365206270 Hvsp8HghVltgIntrnlNgtvCnttr1Stt "HVESP8 High-Voltage Internal (Negative) Contactor 1 State: Position of the High Voltage Energy Storage  Pack 8 Internal 1 negative side bus contactor. Refer to PGN description for usage of this SPN00b = Contactor Open01b = Contactor Closed10b = Error...";
CM_ SG_ 2365206270 Hvsp8HghVltgIntrnlNgtvCnttr2Stt "HVESP8 High-Voltage Internal (Negative) Contactor 2 State: Position of the High Voltage Energy Storage  Pack 8 Internal 2 negative side bus contactor. Refer to PGN description for usage of this SPN00b = Contactor Open01b = Contactor Closed10b = Error...";
CM_ SG_ 2365206270 Hvsp8HghVltgIntrnlNgtvCnttr3Stt "HVESP8 High-Voltage Internal (Negative) Contactor 3 State: Position of the High Voltage Energy Storage  Pack 8 Internal 3 negative side bus contactor. Refer to PGN description for usage of this SPN00b = Contactor Open01b = Contactor Closed10b = Error...";
CM_ SG_ 2365206270 Hvsp8HghVltgIntrnlNgtvCnttr4Stt "HVESP8 High-Voltage Internal (Negative) Contactor 4 State: Position of the High Voltage Energy Storage  Pack 8 Internal 4 negative side bus contactor. Refer to PGN description for usage of this SPN00b = Contactor Open01b = Contactor Closed10b = Error...";
CM_ SG_ 2365206270 Hvsp8HghVltgIntrnlNgtvCnttr5Stt "HVESP8 High-Voltage Internal (Negative) Contactor 5 State: Position of the High Voltage Energy Storage  Pack 8 Internal 5 negative side bus contactor. Refer to PGN description for usage of this SPN00b = Contactor Open01b = Contactor Closed10b = Error...";
CM_ SG_ 2365206270 Hvsp8HghVltgIntrnlNgtvCnttr6Stt "HVESP8 High-Voltage Internal (Negative) Contactor 6 State: Position of the High Voltage Energy Storage  Pack 8 Internal 6 negative side bus contactor. Refer to PGN description for usage of this SPN00b = Contactor Open01b = Contactor Closed10b = Error...";
CM_ SG_ 2365206270 Hvsp8HghVltgIntrnlNgtvCnttr7Stt "HVESP8 High-Voltage Internal (Negative) Contactor 7 State: Position of the High Voltage Energy Storage  Pack 8 Internal 7 negative side bus contactor. Refer to PGN description for usage of this SPN00b = Contactor Open01b = Contactor Closed10b = Error...";
CM_ SG_ 2365206270 Hvsp8HghVltgIntrnlNgtvCnttr8Stt "HVESP8 High-Voltage Internal (Negative) Contactor 8 State: Position of the High Voltage Energy Storage  Pack 8 Internal 8 negative side bus contactor. Refer to PGN description for usage of this SPN00b = Contactor Open01b = Contactor Closed10b = Error...";
CM_ SG_ 2365206270 Hvsp8HghVltgIntrnlPstvCnttr1Stt "HVESP8 High-Voltage Internal (Positive) Contactor 1 State: Position of the High Voltage Energy Storage Pack 8 Internal 1 positive side bus contactor.Refer to PGN description for usage of this SPN00b = Contactor Open01b = Contactor Closed10b = Error11...";
CM_ SG_ 2365206270 Hvsp8HghVltgIntrnlPstvCnttr2Stt "HVESP8 High-Voltage Internal (Positive) Contactor 2 State: Position of the High Voltage Energy Storage Pack 8 Internal 2 positive side bus contactor.Refer to PGN description for usage of this SPN00b = Contactor Open01b = Contactor Closed10b = Error11...";
CM_ SG_ 2365206270 Hvsp8HghVltgIntrnlPstvCnttr3Stt "HVESP8 High-Voltage Internal (Positive) Contactor 3 State: Position of the High Voltage Energy Storage Pack 8 Internal 3 positive side bus contactor.Refer to PGN description for usage of this SPN00b = Contactor Open01b = Contactor Closed10b = Error11...";
CM_ SG_ 2365206270 Hvsp8HghVltgIntrnlPstvCnttr4Stt "HVESP8 High-Voltage Internal (Positive) Contactor 4 State: Position of the High Voltage Energy Storage Pack 8 Internal 4 positive side bus contactor.Refer to PGN description for usage of this SPN00b = Contactor Open01b = Contactor Closed10b = Error11...";
CM_ SG_ 2365206270 Hvsp8HghVltgIntrnlPstvCnttr5Stt "HVESP8 High-Voltage Internal (Positive) Contactor 5 State: Position of the High Voltage Energy Storage Pack 8 Internal 5 positive side bus contactor.Refer to PGN description for usage of this SPN00b = Contactor Open01b = Contactor Closed10b = Error11...";
CM_ SG_ 2365206270 Hvsp8HghVltgIntrnlPstvCnttr6Stt "HVESP8 High-Voltage Internal (Positive) Contactor 6 State: Position of the High Voltage Energy Storage Pack 8 Internal 6 positive side bus contactor.Refer to PGN description for usage of this SPN00b = Contactor Open01b = Contactor Closed10b = Error11...";
CM_ SG_ 2365206270 Hvsp8HghVltgIntrnlPstvCnttr7Stt "HVESP8 High-Voltage Internal (Positive) Contactor 7 State: Position of the High Voltage Energy Storage Pack 8 Internal 7 positive side bus contactor.Refer to PGN description for usage of this SPN00b = Contactor Open01b = Contactor Closed10b = Error11...";
CM_ SG_ 2365206270 Hvsp8HghVltgIntrnlPstvCnttr8Stt "HVESP8 High-Voltage Internal (Positive) Contactor 8 State: Position of the High Voltage Energy Storage Pack 8 Internal 8 positive side bus contactor.Refer to PGN description for usage of this SPN00b = Contactor Open01b = Contactor Closed10b = Error11...";
CM_ BO_ 2365206526 "High Voltage Energy Storage Pack 9 Internal Status 1";
CM_ SG_ 2365206526 Hvsp9HghVltgIntrnlNgtvCnttr1Stt "HVESP9 High-Voltage Internal (Negative) Contactor 1 State: Position of the High Voltage Energy Storage  Pack 9 Internal 1 negative side bus contactor. Refer to PGN description for usage of this SPN00b = Contactor Open01b = Contactor Closed10b = Error...";
CM_ SG_ 2365206526 Hvsp9HghVltgIntrnlNgtvCnttr2Stt "HVESP9 High-Voltage Internal (Negative) Contactor 2 State: Position of the High Voltage Energy Storage  Pack 9 Internal 2 negative side bus contactor. Refer to PGN description for usage of this SPN00b = Contactor Open01b = Contactor Closed10b = Error...";
CM_ SG_ 2365206526 Hvsp9HghVltgIntrnlNgtvCnttr3Stt "HVESP9 High-Voltage Internal (Negative) Contactor 3 State: Position of the High Voltage Energy Storage  Pack 9 Internal 3 negative side bus contactor. Refer to PGN description for usage of this SPN00b = Contactor Open01b = Contactor Closed10b = Error...";
CM_ SG_ 2365206526 Hvsp9HghVltgIntrnlNgtvCnttr4Stt "HVESP9 High-Voltage Internal (Negative) Contactor 4 State: Position of the High Voltage Energy Storage  Pack 9 Internal 4 negative side bus contactor. Refer to PGN description for usage of this SPN00b = Contactor Open01b = Contactor Closed10b = Error...";
CM_ SG_ 2365206526 Hvsp9HghVltgIntrnlNgtvCnttr5Stt "HVESP9 High-Voltage Internal (Negative) Contactor 5 State: Position of the High Voltage Energy Storage  Pack 9 Internal 5 negative side bus contactor. Refer to PGN description for usage of this SPN00b = Contactor Open01b = Contactor Closed10b = Error...";
CM_ SG_ 2365206526 Hvsp9HghVltgIntrnlNgtvCnttr6Stt "HVESP9 High-Voltage Internal (Negative) Contactor 6 State: Position of the High Voltage Energy Storage  Pack 9 Internal 6 negative side bus contactor. Refer to PGN description for usage of this SPN00b = Contactor Open01b = Contactor Closed10b = Error...";
CM_ SG_ 2365206526 Hvsp9HghVltgIntrnlNgtvCnttr7Stt "HVESP9 High-Voltage Internal (Negative) Contactor 7 State: Position of the High Voltage Energy Storage  Pack 9 Internal 7 negative side bus contactor. Refer to PGN description for usage of this SPN00b = Contactor Open01b = Contactor Closed10b = Error...";
CM_ SG_ 2365206526 Hvsp9HghVltgIntrnlNgtvCnttr8Stt "HVESP9 High-Voltage Internal (Negative) Contactor 8 State: Position of the High Voltage Energy Storage  Pack 9 Internal 8 negative side bus contactor. Refer to PGN description for usage of this SPN00b = Contactor Open01b = Contactor Closed10b = Error...";
CM_ SG_ 2365206526 Hvsp9HghVltgIntrnlPstvCnttr1Stt "HVESP9 High-Voltage Internal (Positive) Contactor 1 State: Position of the High Voltage Energy Storage Pack 9 Internal 1 positive side bus contactor.Refer to PGN description for usage of this SPN00b = Contactor Open01b = Contactor Closed10b = Error11...";
CM_ SG_ 2365206526 Hvsp9HghVltgIntrnlPstvCnttr2Stt "HVESP9 High-Voltage Internal (Positive) Contactor 2 State: Position of the High Voltage Energy Storage Pack 9 Internal 2 positive side bus contactor.Refer to PGN description for usage of this SPN00b = Contactor Open01b = Contactor Closed10b = Error11...";
CM_ SG_ 2365206526 Hvsp9HghVltgIntrnlPstvCnttr3Stt "HVESP9 High-Voltage Internal (Positive) Contactor 3 State: Position of the High Voltage Energy Storage Pack 9 Internal 3 positive side bus contactor.Refer to PGN description for usage of this SPN00b = Contactor Open01b = Contactor Closed10b = Error11...";
CM_ SG_ 2365206526 Hvsp9HghVltgIntrnlPstvCnttr4Stt "HVESP9 High-Voltage Internal (Positive) Contactor 4 State: Position of the High Voltage Energy Storage Pack 9 Internal 4 positive side bus contactor.Refer to PGN description for usage of this SPN00b = Contactor Open01b = Contactor Closed10b = Error11...";
CM_ SG_ 2365206526 Hvsp9HghVltgIntrnlPstvCnttr5Stt "HVESP9 High-Voltage Internal (Positive) Contactor 5 State: Position of the High Voltage Energy Storage Pack 9 Internal 5 positive side bus contactor.Refer to PGN description for usage of this SPN00b = Contactor Open01b = Contactor Closed10b = Error11...";
CM_ SG_ 2365206526 Hvsp9HghVltgIntrnlPstvCnttr6Stt "HVESP9 High-Voltage Internal (Positive) Contactor 6 State: Position of the High Voltage Energy Storage Pack 9 Internal 6 positive side bus contactor.Refer to PGN description for usage of this SPN00b = Contactor Open01b = Contactor Closed10b = Error11...";
CM_ SG_ 2365206526 Hvsp9HghVltgIntrnlPstvCnttr7Stt "HVESP9 High-Voltage Internal (Positive) Contactor 7 State: Position of the High Voltage Energy Storage Pack 9 Internal 7 positive side bus contactor.Refer to PGN description for usage of this SPN00b = Contactor Open01b = Contactor Closed10b = Error11...";
CM_ SG_ 2365206526 Hvsp9HghVltgIntrnlPstvCnttr8Stt "HVESP9 High-Voltage Internal (Positive) Contactor 8 State: Position of the High Voltage Energy Storage Pack 9 Internal 8 positive side bus contactor.Refer to PGN description for usage of this SPN00b = Contactor Open01b = Contactor Closed10b = Error11...";
CM_ BO_ 2365206782 "High Voltage Energy Storage Pack 10 Internal Status 1";
CM_ SG_ 2365206782 Hvsp10HVtItNtvCtt1Stt "HVESP10 High-Voltage Internal (Negative) Contactor 1 State: Position of the High Voltage Energy Storage  Pack 10 Internal 1 negative side bus contactor. Refer to PGN description for usage of this SPN00b = Contactor Open01b = Contactor Closed10b = Err...";
CM_ SG_ 2365206782 Hvsp10HVtItNtvCtt2Stt "HVESP10 High-Voltage Internal (Negative) Contactor 2 State: Position of the High Voltage Energy Storage  Pack 10 Internal 2 negative side bus contactor. Refer to PGN description for usage of this SPN00b = Contactor Open01b = Contactor Closed10b = Err...";
CM_ SG_ 2365206782 Hvsp10HVtItNtvCtt3Stt "HVESP10 High-Voltage Internal (Negative) Contactor 3 State: Position of the High Voltage Energy Storage  Pack 10 Internal 3 negative side bus contactor. Refer to PGN description for usage of this SPN00b = Contactor Open01b = Contactor Closed10b = Err...";
CM_ SG_ 2365206782 Hvsp10HVtItNtvCtt4Stt "HVESP10 High-Voltage Internal (Negative) Contactor 4 State: Position of the High Voltage Energy Storage  Pack 10 Internal 4 negative side bus contactor. Refer to PGN description for usage of this SPN00b = Contactor Open01b = Contactor Closed10b = Err...";
CM_ SG_ 2365206782 Hvsp10HVtItNtvCtt5Stt "HVESP10 High-Voltage Internal (Negative) Contactor 5 State: Position of the High Voltage Energy Storage  Pack 10 Internal 5 negative side bus contactor. Refer to PGN description for usage of this SPN00b = Contactor Open01b = Contactor Closed10b = Err...";
CM_ SG_ 2365206782 Hvsp10HVtItNtvCtt6Stt "HVESP10 High-Voltage Internal (Negative) Contactor 6 State: Position of the High Voltage Energy Storage  Pack 10 Internal 6 negative side bus contactor. Refer to PGN description for usage of this SPN00b = Contactor Open01b = Contactor Closed10b = Err...";
CM_ SG_ 2365206782 Hvsp10HVtItNtvCtt7Stt "HVESP10 High-Voltage Internal (Negative) Contactor 7 State: Position of the High Voltage Energy Storage  Pack 10 Internal 7 negative side bus contactor. Refer to PGN description for usage of this SPN00b = Contactor Open01b = Contactor Closed10b = Err...";
CM_ SG_ 2365206782 Hvsp10HVtItNtvCtt8Stt "HVESP10 High-Voltage Internal (Negative) Contactor 8 State: Position of the High Voltage Energy Storage  Pack 10 Internal 8 negative side bus contactor. Refer to PGN description for usage of this SPN00b = Contactor Open01b = Contactor Closed10b = Err...";
CM_ SG_ 2365206782 Hvsp10HVtItPstvCtt1Stt "HVESP10 High-Voltage Internal (Positive) Contactor 1 State: Position of the High Voltage Energy Storage Pack 10 Internal 1 positive side bus contactor.Refer to PGN description for usage of this SPN00b = Contactor Open01b = Contactor Closed10b = Error...";
CM_ SG_ 2365206782 Hvsp10HVtItPstvCtt2Stt "HVESP10 High-Voltage Internal (Positive) Contactor 2 State: Position of the High Voltage Energy Storage Pack 10 Internal 2 positive side bus contactor.Refer to PGN description for usage of this SPN00b = Contactor Open01b = Contactor Closed10b = Error...";
CM_ SG_ 2365206782 Hvsp10HVtItPstvCtt3Stt "HVESP10 High-Voltage Internal (Positive) Contactor 3 State: Position of the High Voltage Energy Storage Pack 10 Internal 3 positive side bus contactor.Refer to PGN description for usage of this SPN00b = Contactor Open01b = Contactor Closed10b = Error...";
CM_ SG_ 2365206782 Hvsp10HVtItPstvCtt4Stt "HVESP10 High-Voltage Internal (Positive) Contactor 4 State: Position of the High Voltage Energy Storage Pack 10 Internal 4 positive side bus contactor.Refer to PGN description for usage of this SPN00b = Contactor Open01b = Contactor Closed10b = Error...";
CM_ SG_ 2365206782 Hvsp10HVtItPstvCtt5Stt "HVESP10 High-Voltage Internal (Positive) Contactor 5 State: Position of the High Voltage Energy Storage Pack 10 Internal 5 positive side bus contactor.Refer to PGN description for usage of this SPN00b = Contactor Open01b = Contactor Closed10b = Error...";
CM_ SG_ 2365206782 Hvsp10HVtItPstvCtt6Stt "HVESP10 High-Voltage Internal (Positive) Contactor 6 State: Position of the High Voltage Energy Storage Pack 10 Internal 6 positive side bus contactor.Refer to PGN description for usage of this SPN00b = Contactor Open01b = Contactor Closed10b = Error...";
CM_ SG_ 2365206782 Hvsp10HVtItPstvCtt7Stt "HVESP10 High-Voltage Internal (Positive) Contactor 7 State: Position of the High Voltage Energy Storage Pack 10 Internal 7 positive side bus contactor.Refer to PGN description for usage of this SPN00b = Contactor Open01b = Contactor Closed10b = Error...";
CM_ SG_ 2365206782 Hvsp10HVtItPstvCtt8Stt "HVESP10 High-Voltage Internal (Positive) Contactor 8 State: Position of the High Voltage Energy Storage Pack 10 Internal 8 positive side bus contactor.Refer to PGN description for usage of this SPN00b = Contactor Open01b = Contactor Closed10b = Error...";
CM_ BO_ 2365207038 "High Voltage Energy Storage Pack 11 Internal Status 1";
CM_ SG_ 2365207038 Hvsp11HVtItNtvCtt1Stt "HVESP11 High-Voltage Internal (Negative) Contactor 1 State: Position of the High Voltage Energy Storage  Pack 11 Internal 1 negative side bus contactor. Refer to PGN description for usage of this SPN00b = Contactor Open01b = Contactor Closed10b = Err...";
CM_ SG_ 2365207038 Hvsp11HVtItNtvCtt2Stt "HVESP11 High-Voltage Internal (Negative) Contactor 2 State: Position of the High Voltage Energy Storage  Pack 11 Internal 2 negative side bus contactor. Refer to PGN description for usage of this SPN00b = Contactor Open01b = Contactor Closed10b = Err...";
CM_ SG_ 2365207038 Hvsp11HVtItNtvCtt3Stt "HVESP11 High-Voltage Internal (Negative) Contactor 3 State: Position of the High Voltage Energy Storage  Pack 11 Internal 3 negative side bus contactor. Refer to PGN description for usage of this SPN00b = Contactor Open01b = Contactor Closed10b = Err...";
CM_ SG_ 2365207038 Hvsp11HVtItNtvCtt4Stt "HVESP11 High-Voltage Internal (Negative) Contactor 4 State: Position of the High Voltage Energy Storage  Pack 11 Internal 4 negative side bus contactor. Refer to PGN description for usage of this SPN00b = Contactor Open01b = Contactor Closed10b = Err...";
CM_ SG_ 2365207038 Hvsp11HVtItNtvCtt5Stt "HVESP11 High-Voltage Internal (Negative) Contactor 5 State: Position of the High Voltage Energy Storage  Pack 11 Internal 5 negative side bus contactor. Refer to PGN description for usage of this SPN00b = Contactor Open01b = Contactor Closed10b = Err...";
CM_ SG_ 2365207038 Hvsp11HVtItNtvCtt6Stt "HVESP11 High-Voltage Internal (Negative) Contactor 6 State: Position of the High Voltage Energy Storage  Pack 11 Internal 6 negative side bus contactor. Refer to PGN description for usage of this SPN00b = Contactor Open01b = Contactor Closed10b = Err...";
CM_ SG_ 2365207038 Hvsp11HVtItNtvCtt7Stt "HVESP11 High-Voltage Internal (Negative) Contactor 7 State: Position of the High Voltage Energy Storage  Pack 11 Internal 7 negative side bus contactor. Refer to PGN description for usage of this SPN00b = Contactor Open01b = Contactor Closed10b = Err...";
CM_ SG_ 2365207038 Hvsp11HVtItNtvCtt8Stt "HVESP11 High-Voltage Internal (Negative) Contactor 8 State: Position of the High Voltage Energy Storage  Pack 11 Internal 8 negative side bus contactor. Refer to PGN description for usage of this SPN00b = Contactor Open01b = Contactor Closed10b = Err...";
CM_ SG_ 2365207038 Hvsp11HVtItPstvCtt1Stt "HVESP11 High-Voltage Internal (Positive) Contactor 1 State: Position of the High Voltage Energy Storage Pack 11 Internal 1 positive side bus contactor.Refer to PGN description for usage of this SPN00b = Contactor Open01b = Contactor Closed10b = Error...";
CM_ SG_ 2365207038 Hvsp11HVtItPstvCtt2Stt "HVESP11 High-Voltage Internal (Positive) Contactor 2 State: Position of the High Voltage Energy Storage Pack 11 Internal 2 positive side bus contactor.Refer to PGN description for usage of this SPN00b = Contactor Open01b = Contactor Closed10b = Error...";
CM_ SG_ 2365207038 Hvsp11HVtItPstvCtt3Stt "HVESP11 High-Voltage Internal (Positive) Contactor 3 State: Position of the High Voltage Energy Storage Pack 11 Internal 3 positive side bus contactor.Refer to PGN description for usage of this SPN00b = Contactor Open01b = Contactor Closed10b = Error...";
CM_ SG_ 2365207038 Hvsp11HVtItPstvCtt4Stt "HVESP11 High-Voltage Internal (Positive) Contactor 4 State: Position of the High Voltage Energy Storage Pack 11 Internal 4 positive side bus contactor.Refer to PGN description for usage of this SPN00b = Contactor Open01b = Contactor Closed10b = Error...";
CM_ SG_ 2365207038 Hvsp11HVtItPstvCtt5Stt "HVESP11 High-Voltage Internal (Positive) Contactor 5 State: Position of the High Voltage Energy Storage Pack 11 Internal 5 positive side bus contactor.Refer to PGN description for usage of this SPN00b = Contactor Open01b = Contactor Closed10b = Error...";
CM_ SG_ 2365207038 Hvsp11HVtItPstvCtt6Stt "HVESP11 High-Voltage Internal (Positive) Contactor 6 State: Position of the High Voltage Energy Storage Pack 11 Internal 6 positive side bus contactor.Refer to PGN description for usage of this SPN00b = Contactor Open01b = Contactor Closed10b = Error...";
CM_ SG_ 2365207038 Hvsp11HVtItPstvCtt7Stt "HVESP11 High-Voltage Internal (Positive) Contactor 7 State: Position of the High Voltage Energy Storage Pack 11 Internal 7 positive side bus contactor.Refer to PGN description for usage of this SPN00b = Contactor Open01b = Contactor Closed10b = Error...";
CM_ SG_ 2365207038 Hvsp11HVtItPstvCtt8Stt "HVESP11 High-Voltage Internal (Positive) Contactor 8 State: Position of the High Voltage Energy Storage Pack 11 Internal 8 positive side bus contactor.Refer to PGN description for usage of this SPN00b = Contactor Open01b = Contactor Closed10b = Error...";
CM_ BO_ 2365207294 "High Voltage Energy Storage Pack 12 Internal Status 1";
CM_ SG_ 2365207294 Hvsp12HVtItNtvCtt1Stt "HVESP12 High-Voltage Internal (Negative) Contactor 1 State: Position of the High Voltage Energy Storage  Pack 12 Internal 1 negative side bus contactor. Refer to PGN description for usage of this SPN00b = Contactor Open01b = Contactor Closed10b = Err...";
CM_ SG_ 2365207294 Hvsp12HVtItNtvCtt2Stt "HVESP12 High-Voltage Internal (Negative) Contactor 2 State: Position of the High Voltage Energy Storage  Pack 12 Internal 2 negative side bus contactor. Refer to PGN description for usage of this SPN00b = Contactor Open01b = Contactor Closed10b = Err...";
CM_ SG_ 2365207294 Hvsp12HVtItNtvCtt3Stt "HVESP12 High-Voltage Internal (Negative) Contactor 3 State: Position of the High Voltage Energy Storage  Pack 12 Internal 3 negative side bus contactor. Refer to PGN description for usage of this SPN00b = Contactor Open01b = Contactor Closed10b = Err...";
CM_ SG_ 2365207294 Hvsp12HVtItNtvCtt4Stt "HVESP12 High-Voltage Internal (Negative) Contactor 4 State: Position of the High Voltage Energy Storage  Pack 12 Internal 4 negative side bus contactor. Refer to PGN description for usage of this SPN00b = Contactor Open01b = Contactor Closed10b = Err...";
CM_ SG_ 2365207294 Hvsp12HVtItNtvCtt5Stt "HVESP12 High-Voltage Internal (Negative) Contactor 5 State: Position of the High Voltage Energy Storage  Pack 12 Internal 5 negative side bus contactor. Refer to PGN description for usage of this SPN00b = Contactor Open01b = Contactor Closed10b = Err...";
CM_ SG_ 2365207294 Hvsp12HVtItNtvCtt6Stt "HVESP12 High-Voltage Internal (Negative) Contactor 6 State: Position of the High Voltage Energy Storage  Pack 12 Internal 6 negative side bus contactor. Refer to PGN description for usage of this SPN00b = Contactor Open01b = Contactor Closed10b = Err...";
CM_ SG_ 2365207294 Hvsp12HVtItNtvCtt7Stt "HVESP12 High-Voltage Internal (Negative) Contactor 7 State: Position of the High Voltage Energy Storage  Pack 12 Internal 7 negative side bus contactor. Refer to PGN description for usage of this SPN00b = Contactor Open01b = Contactor Closed10b = Err...";
CM_ SG_ 2365207294 Hvsp12HVtItNtvCtt8Stt "HVESP12 High-Voltage Internal (Negative) Contactor 8 State: Position of the High Voltage Energy Storage  Pack 12 Internal 8 negative side bus contactor. Refer to PGN description for usage of this SPN00b = Contactor Open01b = Contactor Closed10b = Err...";
CM_ SG_ 2365207294 Hvsp12HVtItPstvCtt1Stt "HVESP12 High-Voltage Internal (Positive) Contactor 1 State: Position of the High Voltage Energy Storage Pack 12 Internal 1 positive side bus contactor.Refer to PGN description for usage of this SPN00b = Contactor Open01b = Contactor Closed10b = Error...";
CM_ SG_ 2365207294 Hvsp12HVtItPstvCtt2Stt "HVESP12 High-Voltage Internal (Positive) Contactor 2 State: Position of the High Voltage Energy Storage Pack 12 Internal 2 positive side bus contactor.Refer to PGN description for usage of this SPN00b = Contactor Open01b = Contactor Closed10b = Error...";
CM_ SG_ 2365207294 Hvsp12HVtItPstvCtt3Stt "HVESP12 High-Voltage Internal (Positive) Contactor 3 State: Position of the High Voltage Energy Storage Pack 12 Internal 3 positive side bus contactor.Refer to PGN description for usage of this SPN00b = Contactor Open01b = Contactor Closed10b = Error...";
CM_ SG_ 2365207294 Hvsp12HVtItPstvCtt4Stt "HVESP12 High-Voltage Internal (Positive) Contactor 4 State: Position of the High Voltage Energy Storage Pack 12 Internal 4 positive side bus contactor.Refer to PGN description for usage of this SPN00b = Contactor Open01b = Contactor Closed10b = Error...";
CM_ SG_ 2365207294 Hvsp12HVtItPstvCtt5Stt "HVESP12 High-Voltage Internal (Positive) Contactor 5 State: Position of the High Voltage Energy Storage Pack 12 Internal 5 positive side bus contactor.Refer to PGN description for usage of this SPN00b = Contactor Open01b = Contactor Closed10b = Error...";
CM_ SG_ 2365207294 Hvsp12HVtItPstvCtt6Stt "HVESP12 High-Voltage Internal (Positive) Contactor 6 State: Position of the High Voltage Energy Storage Pack 12 Internal 6 positive side bus contactor.Refer to PGN description for usage of this SPN00b = Contactor Open01b = Contactor Closed10b = Error...";
CM_ SG_ 2365207294 Hvsp12HVtItPstvCtt7Stt "HVESP12 High-Voltage Internal (Positive) Contactor 7 State: Position of the High Voltage Energy Storage Pack 12 Internal 7 positive side bus contactor.Refer to PGN description for usage of this SPN00b = Contactor Open01b = Contactor Closed10b = Error...";
CM_ SG_ 2365207294 Hvsp12HVtItPstvCtt8Stt "HVESP12 High-Voltage Internal (Positive) Contactor 8 State: Position of the High Voltage Energy Storage Pack 12 Internal 8 positive side bus contactor.Refer to PGN description for usage of this SPN00b = Contactor Open01b = Contactor Closed10b = Error...";
CM_ BO_ 2499425790 "Refuse Truck Body Information";
CM_ SG_ 2499425790 RefuseTransitStatus "Refuse Transit Status: Indicates whether refuse body equipment is in a transit position.00b = arms, forks, or other equipment is not in transit position01b = arms, forks, and other equipment are ready for transit10b = Error11b = Not Available";
CM_ SG_ 2499425790 RefuseFrontLoaderArmPosition "Refuse Front Loader Arm Position: Indicates the position of the front loader arms of a refuse truck.0000b = arms are lowered0001b = arms are above cab0010b = reserved0011b = reserved0100b = reserved0101b = reserved0110b = reserved0111b = reserved1000...";
CM_ SG_ 2499425790 RefuseFrontLoaderForkPosition "Refuse Front Loader Fork Position: Indicates the position of the front loader forks of a refuse truck.00b = forks are not tucked01b = forks are tucked10b = Error11b = Not Available";
CM_ SG_ 2499425790 RefuseTailgatePosition "Refuse Tailgate Position: Indicates the position of the tailgate.00b = tailgate is not closed01b = tailgate is closed10b = Error11b = Not Available";
CM_ SG_ 2499425790 RefuseOverheightOverwidthStatus "Refuse Overheight/Overwidth Status: Indicates whether arms, forks, or other equipment has been detected as in an overheight/overwidth condition00b = no overheight/overwidth condition detected01b = overheight/overwidth condition detected10b = Error11b...";
CM_ BO_ 2566534910 "Engine Fluid Level/Pressure 14";
CM_ SG_ 2566534910 EngnThrttlVlv1OtltPrssr "Engine Throttle Valve 1 Outlet Pressure: Gage pressure of air measured downstream of the discharge side of the first throttle valve.";
CM_ SG_ 2566534910 EngnThrttlVlv1OtltAsltPrssr "Engine Throttle Valve 1 Outlet Absolute Pressure: Absolute pressure of air measured downstream of the discharge side of the first throttle valve.";
CM_ SG_ 2566534910 EngnThrttlVlv2OtltPrssr "Engine Throttle Valve 2 Outlet Pressure: Gage pressure of air measured downstream of the discharge side of the second throttle valve.";
CM_ SG_ 2566534910 EngnThrttlVlv2OtltAsltPrssr "Engine Throttle Valve 2 Outlet Absolute Pressure: Absolute pressure of air measured downstream of the discharge side of the second throttle valve.";
CM_ BO_ 2566535166 "Well Stimulation Transmission Control";
CM_ SG_ 2566535166 WSttLwFwTsssCtIstt "Well Stimulation Low Flow Transmission Control Installation: Indicates whether the transmission low flow control feature is installed.00b = Not Installed01b = Installed10b = Error11b = Not Available";
CM_ SG_ 2566535166 WSttLwFwTsssCtIptCt "Well Stimulation Low Flow Transmission Control Input Configuration: Indicates the input configuration of transmissions equipped with low flow control software.00b = Hardwired01b = SAE J193910b = Error11b = Not Available";
CM_ SG_ 2566535166 WSttLwFwTsssCtDsdSpdIptCt "Well Stimulation Low Flow Transmission Control Desired Speed Input Configuration: Indicates which input configuration is used for transmissions equipped with low flow control for well stimulation.00b = Hardwired01b = SAE J193910b = Error11b = Not Ava...";
CM_ SG_ 2566535166 WSttLwFwTsssCtHdStts "Well Stimulation Low Flow Transmission Control Hold Status: Indicates the transition from normal operation, automatic transmission shift control logic, to low flow operation where the transmission output speed will lock the current output speed.00b =...";
CM_ SG_ 2566535166 WllStmltnPmpOtltPrssrHghLmt "Well Stimulation Pump Outlet Pressure High Limit: Pressure high limit of a outlet pump connected to a well stimulation transmission";
CM_ SG_ 2566535166 WellStimulationPumpDriveType "Well Stimulation Pump Drive Type: Pressure high limit of a outlet pump connected to a well stimulation transmission.00b = Not Configured01b = Mechincal Drive10b = Electrical Drive11b = Not Supported";
CM_ SG_ 2566535166 WSttTsssTs1ECtAtCd "Well Stimulation Transmission TSC1 Engine Control Abort Command: Command for the transmission to stop broadcasting TSC1 messages to the engine. Parameter is only intended for well stimulation applications.00b = Abort Not Requested01b = Abort requeste...";
CM_ BO_ 2566535422 "Well Stimulation Pump Protection System Configuration Command 1";
CM_ SG_ 2566535422 WllStmltnPmpOtltPrssrLvl1Prnt "Well Stimulation Pump Outlet Pressure Level 1 Percent: Outlet pressure percent level 1 used to trigger level 1 response in a pump protection system.";
CM_ SG_ 2566535422 WllStmltnPmpOtltPrssrLvl2Prnt "Well Stimulation Pump Outlet Pressure Level 2 Percent: Outlet pressure percent level 2 used to trigger level 2 response in a pump protection system.";
CM_ SG_ 2566535422 WllStmltnPmpOtltPrssrLvl3Prnt "Well Stimulation Pump Outlet Pressure Level 3 Percent: Outlet pressure percent level 3 used to trigger level 3 response in a pump protection system.";
CM_ SG_ 2566535422 WllStmltnPmpOtltPrssrLvl4Prnt "Well Stimulation Pump Outlet Pressure Level 4 Percent: Outlet pressure percent level 4 used to trigger level 4 response in a pump protection system.";
CM_ SG_ 2566535422 WllStmltnPmpOtltPrssrLvl5Prnt "Well Stimulation Pump Outlet Pressure Level 5 Percent: Outlet pressure percent level 5 used to trigger level 5 response in a pump protection system.";
CM_ SG_ 2566535422 WllStmltnPdOprtngPrssrUpprLmt "Well Stimulation Pad Operating Pressure Upper Limit: Outlet pressure limit of the well stimulation pad.";
CM_ SG_ 2566535422 WSttPpOttPssDFAv "Well Stimulation Pump Outlet Pressure Difference From Average: Indicates whether a pump outlet pressure difference has been detected between a fracking trailer pressure sensor compared against the well stimulation pad average.00b = No Outlet Pressure...";
CM_ SG_ 2566535422 WllStmltnSstmCntrllrEnlStts "Well Stimulation System Controller Enable Status: Indicates whether the main controller application used for the well stimulation system is enabled or disabled.00b = Disabled01b = Enabled10b = Reserved11b = Not Available";
CM_ BO_ 2566535678 "Well Stimulation Pump Protection System Configuration Command 2";
CM_ SG_ 2566535678 WllStmltnDshrgPrssrRspnsLvl1Ftr "Well Stimulation Discharge Pressure Response Level 1 Factor: Used to adjust the response after crossing level 1 pressure protection indicated in SPN 22199 (Well Stimulation Pump Outlet Pressure Level 1 Percent)";
CM_ SG_ 2566535678 WllStmltnDshrgPrssrRspnsLvl2Ftr "Well Stimulation Discharge Pressure Response Level 2 Factor: Used to adjust the response after crossing level 2 pressure protection indicated in SPN 22200 (Well Stimulation Pump Outlet Pressure Level 2 Percent)";
CM_ SG_ 2566535678 WllStmltnDshrgPrssrRspnsLvl3Ftr "Well Stimulation Discharge Pressure Response Level 3 Factor: Used to adjust the response after crossing level 3 pressure protection indicated in SPN 22201 (Well Stimulation Pump Outlet Pressure Level 3 Percent)";
CM_ SG_ 2566535678 WllStmltnDshrgPrssrRspnsLvl4Ftr "Well Stimulation Discharge Pressure Response Level 4 Factor: Used to adjust the response after crossing level 4 pressure protection indicated in SPN 22202 (Well Stimulation Pump Outlet Pressure Level 4 Percent)";
CM_ SG_ 2566535678 WllStmltnDshrgPrssrRspnsLvl5Ftr "Well Stimulation Discharge Pressure Response Level 5 Factor: Used to adjust the response after crossing level 5 pressure protection indicated in SPN 22203 (Well Stimulation Pump Outlet Pressure Level 5 Percent)";
CM_ SG_ 2566535678 WllStmltnIntlRmpGnFtr "Well Stimulation Initial Ramp Gain Factor: Used to adjust the Level 1 thru Level 5 gain factor implemented in pressure protection feature on detection on ramp from neutral/park to pumping operations.";
CM_ SG_ 2566535678 WSttOttPssPttLvAtvStts "Well Stimulation Outlet Pressure Protection Level Active Status: Used to indicate the active outlet pressure protection status of well stimulation system.0000b = Not in use0001b = Outlet Pressure Protection Waiting0010b = Outlet Pressure Protection L...";
CM_ BO_ 2566535934 "Electric PTO Drive Engagement 1";
CM_ SG_ 2566535934 ElectricPtoDriveEngagement1Crc "Electric PTO Drive Engagement 1 CRC: The CRC is defined as follows: - Length: 8 bits- Polynomial: x^8+x^5+x^3+x^2+x+1- Initial Value: FFh- Input Data Reflection: Not reflected- Result Data Reflection: Not reflected- XOR value: FFh SAE makes no claim ...";
CM_ SG_ 2566535934 EltrPtDrvEnggmnt1Cntr "Electric PTO Drive Engagement 1 Counter: The message counter is used to detect situations where the transmitting ECU malfunction repeats the same frame all the time. The receiver of the information may use the counter parameter to detect this situati...";
CM_ SG_ 2566535934 EnableSwitchEpto1 "Enable Switch - ePTO 1: Status of the operator's switch or other input on vehicle which indicates the desire for activating or engaging the ePTO equipment00b = Enable switch off - ePTO operation not desired01b = Enable switch on - ePTO operation desi...";
CM_ SG_ 2566535934 EngagementConsentEpto1 "Engagement Consent - ePTO 1: Indicates equipment controller's consent to activate or engage the high voltage ePTO.  The vehicle controller may only apply high voltage to ePTO equipment when consent is given.  Removal of consent initiates normal power...";
CM_ SG_ 2566535934 EngagementStatusEpto1 "Engagement Status - ePTO 1: Indicates whether electric power is applied to the ePTO equipment.00b = Drive not activated or engaged01b = Drive is activated or engaged10b = Error11b = Not available";
CM_ SG_ 2566535934 EmergencyDeEnergizeSwitchEpto1 "Emergency De-energize Switch - ePTO 1: Initiates emergency shutdown procedure as appropriate to the application, which may include active discharge of ePTO bus.00b = Emergency De-energize not active01b = Emergency De-energize active - initiate shutdo...";
CM_ SG_ 2566535934 SystemReadinessEpto1 "System Readiness - ePTO 1: Indicates availability of the power source to energize ePTO equipment or operational readiness of ePTO equipment to be energized00b = ePTO not available due to system error01b = ePTO available10b = Reserved11b = Not availab...";
CM_ SG_ 2566535934 ErrorIndicatorEpto1 "Error Indicator - ePTO 1: Signal to the operator that some ePTO error exists, such as failed to activate when requested00b = no ePTO error detected or ePTO not enabled01b = ePTO error detected10b = Reserved11b = Not available";
CM_ BO_ 2566536190 "Electric PTO 1 Information";
CM_ SG_ 2566536190 Epto1CurrentLimit "ePTO 1 Current Limit: Maximum current ePTO equipment is allowed to draw.";
CM_ SG_ 2566536190 Epto1Current "ePTO 1 Current: Actual current consumed by ePTO equipment";
CM_ SG_ 2566536190 Epto1Voltage "ePTO 1 Voltage: Voltage applied at the ePTO equipment terminals";
CM_ BO_ 2566536446 "Engine Exhaust O2 Sensor  Information";
CM_ SG_ 2566536446 EngnExhstO2Snsr1ArFlEqvlnRt "Engine Exhaust O2 Sensor 1 Air/Fuel Equivalence Ratio: Sensor 1 actual air fuel ratio to desired air fuel ratio in the exhaust gas that controls the intake air flow.Note:  J1979 equivalent (PID F444) for O2 sensor 1 Air/Fuel equivalence ratio. See Em...";
CM_ SG_ 2566536446 EngineExhaustO2Sensor1Voltage "Engine Exhaust O2 Sensor 1 Voltage: O2 sensor 1 voltage.Note:  See Emission Remote Supervision System of Heavy-Duty Vehicles HJ 1239.3 document (China Regulation) for more information.A value of FB00h shall be provided when ambient or engine operatin...";
CM_ SG_ 2566536446 EngnExhstO2Snsr2ArFlEqvlnRt "Engine Exhaust O2 Sensor 2 Air/Fuel Equivalence Ratio: Sensor 2 actual air fuel ratio to desired air fuel ratio in the exhaust gas that controls the intake air flow.Note:  See Emission Remote Supervision System of Heavy-Duty Vehicles HJ 1239.3 docume...";
CM_ SG_ 2566536446 EngineExhaustO2Sensor2Voltage "Engine Exhaust O2 Sensor 2 Voltage: O2 sensor 2 voltage.Note:  J1979 equivalent (PID F414) for O2 sensor 1 Air/Fuel equivalence ratio. See Emission Remote Supervision System of Heavy-Duty Vehicles HJ 1239.3 document (China Regulation) for more inform...";
CM_ BO_ 2566536702 "Gaseous Fuel Supply Pressure 3";
CM_ SG_ 2566536702 EngnGssFl2SpplPrssr1 "Engine Gaseous Fuel 2 Supply Pressure 1: The pressure of the second gaseous fuel measured by first pressure sensor in the primary, as delivered from the supply pump to the injector metering intake.";
CM_ SG_ 2566536702 EGssF1SppPssRtOttPss "Engine Gaseous Fuel 1 Supply Pressure Regulator Outlet Pressure: The pressure of the first gaseous fuel at the outlet of the pressure regulator.";
CM_ SG_ 2566536702 EGssF2SppPssRtOttPss "Engine Gaseous Fuel 2 Supply Pressure Regulator Outlet Pressure: The pressure of the second gaseous fuel at the outlet of the pressure regulator.";
CM_ SG_ 2566536702 EngnGssFl1SpplPrssrRgltrPstn "Engine Gaseous Fuel 1 Supply Pressure Regulator Position: Position of regulator valve, which is used to control the flow of gaseous fuel through the fuel supply unit. 0% represents valve fully closed and 100% represents valve fully open.";
CM_ SG_ 2566536702 EngnGssFl2SpplPrssrRgltrPstn "Engine Gaseous Fuel 2 Supply Pressure Regulator Position: Position of regulator valve, which is used to control the flow of the second gaseous fuel through the fuel supply unit. 0% represents valve fully closed and 100% represents valve fully open.";
CM_ BO_ 2499428094 "Traffic Signage";
CM_ SG_ 2499428094 TrafficSignSpeedLimit "Traffic Sign Speed Limit: Indicates the traffic sign speed limit as currently detected by a camera on one of the vehicle devices.See SPN 22773 (Map Based Vehicle Speed Limit) for digital map speed limit data.Parameter Specific Indicator:A value of FB...";
CM_ BO_ 2566537214 "Engine Configuration 4";
CM_ SG_ 2566537214 EngnClngFnClntAtvtnTmprtr "Engine Cooling Fan Coolant Activation Temperature: Indicates the engine coolant temperature at which the engine cooling fan is activated at 100 percent.";
CM_ SG_ 2566537214 EngnClngFnIntkMnfldAtvtnTmprtr "Engine Cooling Fan Intake Manifold Activation Temperature: Indicates the intake manifold temperature at which the engine cooling fan is activated at 100 percent.";
CM_ BO_ 2633768190 "Refrigeration Compartment Information 1";
CM_ SG_ 2633768190 RefrigeratedCompartmentPosition "Refrigerated Compartment Position: The position of the transportation refrigerated compartment.  There are two kinds of positions in a transportation refrigerated vehicle.1) The first situation is a refrigerated container itself is divided into a few...";
CM_ SG_ 2633768190 RefrigeratedCompartmentId "Refrigerated Compartment ID: The ID of the tansportation refrigerated compartment.The ID can be the ID assigned to the compartment (zone / pallet / box, etc.), or the ID of the sensor that is put in the compartment (zone / pallet / box, etc.).";
CM_ SG_ 2633768190 RefrigeratedCompartmentHumidity "Refrigerated Compartment Humidity: The humidity of the transportation refrigerated compartment.";
CM_ SG_ 2633768190 RfrgrtdCmprtmntTmprtr "Refrigerated Compartment Temperature: The temperature of the transportation refrigerated compartment.";
CM_ BO_ 2633768446 "Refrigeration Compartment Information 2";
CM_ SG_ 2633768446 TransportationCompartmentDoorId "Transportation Compartment Door ID: The ID of the transportation compartment door.  A refrigerated container can be divided into a few compartments, usually referred to as zones (for example, zone 1, zone 2, etc.).  Each compartment could have its ow...";
CM_ SG_ 2633768446 TrnsprttnCmprtmntDrStts "Transportation Compartment Door Status: The status of the transportation compartment door.00b = Door open01b = Door closed10b = Error11b = Not available";
CM_ BO_ 2352611070 "External ACC Acceleration Request";
CM_ SG_ 2352611070 ExtrnlAAlrtnRqstCr "External ACC Acceleration Request CRC: This two byte signal field is reserved to support the use of an in-frame data integrity CRC.When a CRC is correctly implemented as part of a Functional Safety process (ISO 26262) it can provide protection agains...";
CM_ SG_ 2352611070 ExtrnlAAlrtnRqstCntr "External ACC Acceleration Request Counter: The counter is generated by the sender of the PG. The counter value is initialized to 0 for the first transmission of this PG. The counter shall be incremented by 1 for every following transmission of the PG...";
CM_ SG_ 2352611070 ExternalAccAccelerationRequest "External ACC Acceleration Request: This signal is provided to a powertrain cruise control system from an external adaptive cruise control system. This acceleration value is intended as an input to the engine controller's cruise control system. This s...";
CM_ SG_ 2352611070 ExtrnlAAlrtnRqstCntrlMd "External ACC Acceleration Request Control Mode: This signal defines if the External ACC acceleration request should be considered by the cruise control system.When the signal state is No External ACC Acceleration Request (00b) the powertrain cruise c...";
CM_ SG_ 2352611070 InMessageIntegrityDataSupported "In Message Integrity Data Supported: Indicates the External ACC Acceleration Request CRC (SPN 22128) and the External ACC Acceleration Request  Counter (SPN 22129) is supported by the sender.00b = External ACC Acceleration Request CRC and Counter is ...";
CM_ BO_ 2554003198 "Battery Charger 1 Command 1";
CM_ SG_ 2554003198 ChargerCommandCrc "Charger Command CRC: The CRC is defined as follows:- Length: 8 bits- Polynomial: x^8+x^5+x^3+x^2+x+1- Initial Value: FFh- Input Data Reflection: Not reflected- Result Data Reflection: Not reflected- XOR value: FFhSAE makes no claim of the functional ...";
CM_ SG_ 2554003198 ChargerCommandSequenceCounter "Charger Command Sequence Counter: The message counter is used to detect situations where the transmitting ECU malfunction repeats the same frame all the time. The receiver of the information may use the counter parameter todetect this situation. The ...";
CM_ SG_ 2554003198 ChargerCommandTargetVoltage "Charger Command Target Voltage: Instantaneous requested DC output voltage limit.";
CM_ SG_ 2554003198 ChargerCommandTargetCurrent "Charger Command Target Current: Instantaneous requested DC output current limit.";
CM_ BO_ 2554068734 "Battery Charger 2 Command 1";
CM_ SG_ 2554068734 AuxChargerCommandCrc "Aux Charger Command CRC: The CRC is defined as follows:- Length: 8 bits- Polynomial: x^8+x^5+x^3+x^2+x+1- Initial Value: FFh- Input Data Reflection: Not reflected- Result Data Reflection: Not reflected- XOR value: FFhSAE makes no claim of the functio...";
CM_ SG_ 2554068734 AxChrgrCmmndSqnCntr "Aux Charger Command Sequence Counter: The message counter is used to detect situations where the transmitting ECU malfunction repeats the same frame all the time. The receiver of the information may use the counter parameter todetect this situation. ...";
CM_ SG_ 2554068734 AuxChargerCommandTargetVoltage "Aux Charger Command Target Voltage: Instantaneous requested DC output voltage limit.";
CM_ SG_ 2554068734 AuxChargerCommandTargetCurrent "Aux Charger Command Target Current: Instantaneous requested DC output current limit.";
CM_ BO_ 2555051774 "EV Multi-Connection DC Status 1";
CM_ SG_ 2555051774 EvMltCnntnCnCndtnngFlg "EV Multi-Connection Cabin Conditioning Flag: Informs the EVSE that the EV is performing cabin conditioning.See SAE J2847-2 (April 2015 Section 4.2.23)00b = Cabin conditioning not active01b = Cabin conditioning active10b = Reserved11b = Not available...";
CM_ SG_ 2555051774 EvMltCnntnRssCndtnngFlg "EV Multi-Connection RESS Conditioning Flag: Informs the EVSE that the EV is using energy from the EVSE  to perform battery (RESS/HVES) conditioning.See SAE J2847-2 (April 2015 Section 4.2.33)00b = Battery conditioning not active01b = Battery conditio...";
CM_ SG_ 2555051774 EvMultiConnectionErrorCode "EV Multi-Connection Error Code: Indicates the highest priority EV internal error state that may inhibit/abort chargingSee SAE J2847-2 (April 2015 Section 4.2.26)0000b = No Error0001b = Battery Temperature too hot/cold0010b = Shift Position  (Vehicle ...";
CM_ SG_ 2555051774 EvMultiConnectionStateOfCharge "EV Multi-Connection State of Charge: State of Charge for the battery pack being charged by this connection.This value may be used by the connected EVSE for display purposes";
CM_ BO_ 2555117310 "EV Multi-Connection DC Charging Limits 1";
CM_ SG_ 2555117310 HrdOrEvMltCnntnDChrgngVltgMxmm "Hybrid or EV Multi-Connection DC Charging Voltage Maximum: Hybrid or Electric Vehicle's maximum allowed DC charging input voltage for this connection.This is communicated to a DC EVSE during initial exchange of parameters and may optionally be dynami...";
CM_ SG_ 2555117310 HrdOrEvMltCnntnDChrgngCrrntMxmm "Hybrid or EV Multi-Connection DC Charging Current Maximum: Hybrid or Electric Vehicle's maximum rated DC charging input current, for this connection.This is communicated to a DC EVSE during initial exchange of parameters and may optionally be dynamic...";
CM_ SG_ 2555117310 HrdOrEvMltCnntnDChrgngPwrMxmm "Hybrid or EV Multi-Connection DC Charging Power Maximum: Hybrid or Electric Vehicle's maximum rated DC charging input power,  for this connection.This is communicated to a DC EVSE during initial exchange of parameters and may optionally be dynamicall...";
CM_ SG_ 2555117310 HdOEvMtCtRqstdETsTp "Hybrid or EV Multi-Connection requested Energy Transfer Type: Hybrid  or Electric vehicle's required Energy transfer type for this connection0000b = DC-Extended0001b = DC-Core0010b = Reserved0011b = Reserved0100b = Reserved0101b = Reserved0110b = Res...";
CM_ BO_ 2565900286 "Wireless Charger System Status 1";
CM_ SG_ 2565900286 WirelessChargerSystemState "Wireless Charger System State: The present charging state of the system. States are (reference to SAE J2847-6 Sep 2020):000 - Off001 - Standby002 - Session Initiated003 - Awaiting Alignment004 - Idle005 - Power Transfer006 - Shutdown007 - VA (Vehicle...";
CM_ SG_ 2565900286 WrlssChrgrPrsntChrgngVltg "Wireless Charger Present Charging Voltage: The present voltage of the supplied power from the charging system as measured by the wireless charging system.";
CM_ SG_ 2565900286 WrlssChrgrPrsntChrgngCrrnt "Wireless Charger Present Charging Current: The present current of the supplied power from the charging system as measured by the wireless charging system. A Positive number denotes current being supplied into the battery, a negative number denotes cu...";
CM_ SG_ 2565900286 WirelessChargerDeratingReason "Wireless Charger Derating Reason: Dominant reason that the delivered power is lower than the requested power:0 - Not Derating1 - VA (Vehicle Assembly) Temperature2 - VA (Vehicle Assembly) Alignment3 - Vehicle Internal4 - GA (Ground Assembly) Temperat...";
CM_ BO_ 2565900542 "Wireless Charger Alignment Quality Status";
CM_ SG_ 2565900542 WrlssChrgrAlgnmntXQlt "Wireless Charger Alignment X Quality: Qualitative metric of alignment in the X direction (direction of travel), 100 when the ground assembly coil is in front of the vehicle coil, -100 when ground assembly coil is behind the vehicle coil, 0 when the c...";
CM_ SG_ 2565900542 WrlssChrgrAlgnmntYQlt "Wireless Charger Alignment Y Quality: Qualitative metric of alignment in the Y direction (left/right direction), 100 when the ground assembly coil is to the left of the vehicle coil, -100 when ground assembly coil is to the right of the vehicle, 0 wh...";
CM_ SG_ 2565900542 WrlssChrgrAlgnmntZQlt "Wireless Charger Alignment Z Quality: Qualitative metric of alignment in the Z direction (vertical direction), 100 when the vehicle coil is above the nominal charging height, -100 when below the nominal charging height, 0 when the vehicle coil is at ...";
CM_ SG_ 2565900542 WrlssChrgrAlgnmntOvrllQlt "Wireless Charger Alignment Overall Quality: Qualitative metric of overall alignment, 100% being optimally aligned and 0% not being aligned in any measurable way.";
CM_ BO_ 2498819326 "Genset Reactive Power and Supporting Functions";
CM_ SG_ 2498819326 DemandedPowerFactor "Demanded Power Factor: Power factor demanded by the reactive power grid code functions.";
CM_ SG_ 2498819326 DemandedVoltage "Demanded Voltage: Voltage demanded by the reactive power and real power grid code functions.";
CM_ SG_ 2498819326 SimulatedMainsFrequencyOffset "Simulated Mains Frequency Offset: Simulated mains frequency offset for test functionality for grid code functions. The simulated frequency offset can be added to the measured frequency or to the nominal frequency.  See SPN 23909 for alternate range a...";
CM_ SG_ 2498819326 SimulatedMainsFrequencyStatus "Simulated Mains Frequency Status: Indicates when the test function for the simulated mains frequency is active or inactive. The simulated frequency offset can be added to the measured frequency or to the nominal frequency.00b = Inactive01b = Active10...";
CM_ SG_ 2498819326 TstFntnFrThPrttnStts "Test Function for the Protection Status: Indicates when the test function for the protection function is active or inactive.00b = Inactive01b = Active10b = Error11b = Not available";
CM_ SG_ 2498819326 GtUdvtAdOvvtPttTstFtStts "Generator Undervoltage and Overvoltage Protection Test Function Status: Indicates if the test function for the overvoltage and undervoltage protection function is active or inactive.00b = Inactive01b = Active10b = Error11b = Not available";
CM_ SG_ 2498819326 GnrtrUtltDplngPrttnTstFntnStts "Generator Utility Decoupling Protection Test Function Status: Indicates if the test function for the utility decoupling protection function is active or inactive.00b = Inactive01b = Active10b = Error11b = Not available";
CM_ SG_ 2498819326 GeneratorFaultRideThroughStatus "Generator Fault Ride Through Status: Indicates when a Fault Ride Through is detected.Note:  The state 0001b = Fault Ride Through detected is used when the system is unable to determine high or low voltage0000b = No Fault Ride Through detected0001b = ...";
CM_ SG_ 2498819326 GnrtrRtvPwrUndrExttnLmtStts "Generator Reactive Power Under Excitation Limit Status: Indicates that the generator reactive power is limited with an under excitation limitation.00b = Inactive01b = Active10b = Error11b = Not available";
CM_ SG_ 2498819326 GnrtrRtvPwrOvrExttnLmtStts "Generator Reactive Power Over Excitation Limit Status: Indicates that the generator reactive power is limited with an over excitation limitation.00b = Inactive01b = Active10b = Error11b = Not available";
CM_ BO_ 2364761342 "Tracked Vehicle Data";
CM_ SG_ 2364761342 LftTrnsmssnOtptShftDrtnlSpd "Left Transmission Output Shaft Directional Speed: Rotational speed of the left-side output shaft. The left side of the vehicle is to the operator's left during normal forward operation. Positive output shaft rotation occurs when the left side of the ...";
CM_ SG_ 2364761342 RghtTrnsmssnOtptShftDrtnlSpd "Right Transmission Output Shaft Directional Speed: Rotational speed of the right-side output shaft. The right side of the vehicle is to the operator's right during normal forward operation. Positive output shaft rotation occurs when the right side of...";
CM_ BO_ 2566088190 "Electrified Accessory Propulsion Motor Coolant Fan 3 Status 2";
CM_ SG_ 2566088190 PrplsnMtrClntFn3Vltg "Propulsion Motor Coolant Fan 3 Voltage: The voltage level of the electrical bus that is utilized by this device as the power source/sink for generating motor torque, as measured at the input of this device.  Note that one design alternative for this ...";
CM_ SG_ 2566088190 PrplsnMtrClntFn3Crrnt "Propulsion Motor Coolant Fan 3 Current: The current in or out of this device with respect to the electrical bus that is utilized by this device as the power source/sink for generating motor torque.  This parameter should be synchronized with SPN 2264...";
CM_ SG_ 2566088190 PrplsnMtrClntFn3HvlStts "Propulsion Motor Coolant Fan 3 HVIL Status: High Voltage Interlock Loop (HVIL) state, as measured by this device.00b = HVIL Closed01b = HVIL Open10b = Error11b = Not Available";
CM_ SG_ 2566088190 PrplsnMtrClntFn3PrntSpdStts "Propulsion Motor Coolant Fan 3 Percent Speed Status: Enable and direction status of the Propulsion Motor Coolant Fan 3 system or component.  This parameter is used with SPN 23467 (Propulsion Motor Coolant Fan 3 Percent Speed).00b = Accessory Motor Of...";
CM_ SG_ 2566088190 PrplsnMtrClntFn3PrntSpd "Propulsion Motor Coolant Fan 3 Percent Speed: Speed of the Propulsion Motor Coolant Fan 3 in percentage of maximum speed.  This parameter is used with SPN 23466 (Propulsion Motor Coolant Fan 3 Percent Speed Status).";
CM_ BO_ 2566088446 "Electrified Accessory Propulsion Motor Coolant Fan 2 Status 2";
CM_ SG_ 2566088446 PrplsnMtrClntFn2Vltg "Propulsion Motor Coolant Fan 2 Voltage: The voltage level of the electrical bus that is utilized by this device as the power source/sink for generating motor torque, as measured at the input of this device.  Note that one design alternative for this ...";
CM_ SG_ 2566088446 PrplsnMtrClntFn2Crrnt "Propulsion Motor Coolant Fan 2 Current: The current in or out of this device with respect to the electrical bus that is utilized by this device as the power source/sink for generating motor torque.  This parameter should be synchronized with SPN 2264...";
CM_ SG_ 2566088446 PrplsnMtrClntFn2HvlStts "Propulsion Motor Coolant Fan 2 HVIL Status: High Voltage Interlock Loop (HVIL) state, as measured by this device.00b = HVIL Closed01b = HVIL Open10b = Error11b = Not Available";
CM_ SG_ 2566088446 PrplsnMtrClntFn2PrntSpdStts "Propulsion Motor Coolant Fan 2 Percent Speed Status: Enable and direction status of the Propulsion Motor Coolant Fan 2 system or component.  This parameter is used with SPN 23469 (Propulsion Motor Coolant Fan 2 Percent Speed).00b = Accessory Motor Of...";
CM_ SG_ 2566088446 PrplsnMtrClntFn2PrntSpd "Propulsion Motor Coolant Fan 2 Percent Speed: Speed of the Propulsion Motor Coolant Fan 2 in percentage of maximum speed.  This parameter is used with SPN 23468 (Propulsion Motor Coolant Fan 2 Percent Speed Status).";
CM_ BO_ 2566088702 "Electrified Accessory Propulsion Motor Coolant Fan 1 Status 2";
CM_ SG_ 2566088702 PrplsnMtrClntFn1Vltg "Propulsion Motor Coolant Fan 1 Voltage: The voltage level of the electrical bus that is utilized by this device as the power source/sink for generating motor torque, as measured at the input of this device.  Note that one design alternative for this ...";
CM_ SG_ 2566088702 PrplsnMtrClntFn1Crrnt "Propulsion Motor Coolant Fan 1 Current: The current in or out of this device with respect to the electrical bus that is utilized by this device as the power source/sink for generating motor torque.  This parameter should be synchronized with SPN 2264...";
CM_ SG_ 2566088702 PrplsnMtrClntFn1HvlStts "Propulsion Motor Coolant Fan 1 HVIL Status: High Voltage Interlock Loop (HVIL) state, as measured by this device.00b = HVIL Closed01b = HVIL Open10b = Error11b = Not Available";
CM_ SG_ 2566088702 PrplsnMtrClntFn1PrntSpdStts "Propulsion Motor Coolant Fan 1 Percent Speed Status: Enable and direction status of the Propulsion Motor Coolant Fan 1 system or component.  This parameter is used with SPN 23471 (Propulsion Motor Coolant Fan 1 Percent Speed).00b = Accessory Motor Of...";
CM_ SG_ 2566088702 PrplsnMtrClntFn1PrntSpd "Propulsion Motor Coolant Fan 1 Percent Speed: Speed of the Propulsion Motor Coolant Fan 1 in percentage of maximum speed.  This parameter is used with SPN 23470 (Propulsion Motor Coolant Fan 1 Percent Speed Status).";
CM_ BO_ 2566088958 "Electrified Accessory Power Electronics Coolant Fan 3 Status 2";
CM_ SG_ 2566088958 PwrEltrnsClntFn3Vltg "Power Electronics Coolant Fan 3 Voltage: The voltage level of the electrical bus that is utilized by this device as the power source/sink for generating motor torque, as measured at the input of this device.  Note that one design alternative for this...";
CM_ SG_ 2566088958 PwrEltrnsClntFn3Crrnt "Power Electronics Coolant Fan 3 Current: The current in or out of this device with respect to the electrical bus that is utilized by this device as the power source/sink for generating motor torque.  This parameter should be synchronized with SPN 226...";
CM_ SG_ 2566088958 PwrEltrnsClntFn3HvlStts "Power Electronics Coolant Fan 3 HVIL Status: High Voltage Interlock Loop (HVIL) state, as measured by this device.00b = HVIL Closed01b = HVIL Open10b = Error11b = Not Available";
CM_ SG_ 2566088958 PwrEltrnsClntFn3PrntSpdStts "Power Electronics Coolant Fan 3 Percent Speed Status: Enable and direction status of the Power Electronics Coolant Fan 3 system or component.  This parameter is used with SPN 23473 (Power Electronics Coolant Fan 3 Percent Speed).00b = Accessory Motor...";
CM_ SG_ 2566088958 PwrEltrnsClntFn3PrntSpd "Power Electronics Coolant Fan 3 Percent Speed: Speed of the Power Electronics Coolant Fan 3 in percentage of maximum speed.  This parameter is used with SPN 23472 (Power Electronics Coolant Fan 3 Percent Speed Status).";
CM_ BO_ 2566089214 "Electrified Accessory Power Electronics Coolant Fan 2 Status 2";
CM_ SG_ 2566089214 PwrEltrnsClntFn2Vltg "Power Electronics Coolant Fan 2 Voltage: The voltage level of the electrical bus that is utilized by this device as the power source/sink for generating motor torque, as measured at the input of this device.  Note that one design alternative for this...";
CM_ SG_ 2566089214 PwrEltrnsClntFn2Crrnt "Power Electronics Coolant Fan 2 Current: The current in or out of this device with respect to the electrical bus that is utilized by this device as the power source/sink for generating motor torque.  This parameter should be synchronized with SPN 226...";
CM_ SG_ 2566089214 PwrEltrnsClntFn2HvlStts "Power Electronics Coolant Fan 2 HVIL Status: High Voltage Interlock Loop (HVIL) state, as measured by this device.00b = HVIL Closed01b = HVIL Open10b = Error11b = Not Available";
CM_ SG_ 2566089214 PwrEltrnsClntFn2PrntSpdStts "Power Electronics Coolant Fan 2 Percent Speed Status: Enable and direction status of the Power Electronics Coolant Fan 2 system or component.  This parameter is used with SPN 23475 (Power Electronics Coolant Fan 2 Percent Speed).00b = Accessory Motor...";
CM_ SG_ 2566089214 PwrEltrnsClntFn2PrntSpd "Power Electronics Coolant Fan 2 Percent Speed: Speed of the Power Electronics Coolant Fan 2 in percentage of maximum speed.  This parameter is used with SPN 23474 (Power Electronics Coolant Fan 2 Percent Speed Status).";
CM_ BO_ 2566089470 "Electrified Accessory Power Electronics Coolant Fan 1 Status 2";
CM_ SG_ 2566089470 PwrEltrnsClntFn1Vltg "Power Electronics Coolant Fan 1 Voltage: The voltage level of the electrical bus that is utilized by this device as the power source/sink for generating motor torque, as measured at the input of this device.  Note that one design alternative for this...";
CM_ SG_ 2566089470 PwrEltrnsClntFn1Crrnt "Power Electronics Coolant Fan 1 Current: The current in or out of this device with respect to the electrical bus that is utilized by this device as the power source/sink for generating motor torque.  This parameter should be synchronized with SPN 226...";
CM_ SG_ 2566089470 PwrEltrnsClntFn1HvlStts "Power Electronics Coolant Fan 1 HVIL Status: High Voltage Interlock Loop (HVIL) state, as measured by this device.00b = HVIL Closed01b = HVIL Open10b = Error11b = Not Available";
CM_ SG_ 2566089470 PwrEltrnsClntFn1PrntSpdStts "Power Electronics Coolant Fan 1 Percent Speed Status: Enable and direction status of the Power Electronics Coolant Fan 1 system or component.  This parameter is used with SPN 23477 (Power Electronics Coolant Fan 1 Percent Speed).00b = Accessory Motor...";
CM_ SG_ 2566089470 PwrEltrnsClntFn1PrntSpd "Power Electronics Coolant Fan 1 Percent Speed: Speed of the Power Electronics Coolant Fan 1 in percentage of maximum speed.  This parameter is used with SPN 23476 (Power Electronics Coolant Fan 1 Percent Speed Status).";
CM_ BO_ 2566089726 "Electrified Accessory Propulsion Motor Oil Pump Status 2";
CM_ SG_ 2566089726 PropulsionMotorOilPumpVoltage "Propulsion Motor Oil Pump Voltage: The voltage level of the electrical bus that is utilized by this device as the power source/sink for generating motor torque, as measured at the input of this device.  Note that one design alternative for this devic...";
CM_ SG_ 2566089726 PropulsionMotorOilPumpCurrent "Propulsion Motor Oil Pump Current: The current in or out of this device with respect to the electrical bus that is utilized by this device as the power source/sink for generating motor torque.  This parameter should be synchronized with SPN 22659 (Pr...";
CM_ SG_ 2566089726 PrplsnMtrOlPmpHvlStts "Propulsion Motor Oil Pump HVIL Status: High Voltage Interlock Loop (HVIL) state, as measured by this device.00b = HVIL Closed01b = HVIL Open10b = Error11b = Not Available";
CM_ SG_ 2566089726 PrplsnMtrOlPmpPrntSpdStts "Propulsion Motor Oil Pump Percent Speed Status: Enable and direction status of the Propulsion Motor Oil Pump system or component.  This parameter is used with SPN 23479 (Propulsion Motor Oil Pump Percent Speed).00b = Accessory Motor Off01b = Accessor...";
CM_ SG_ 2566089726 PrplsnMtrOlPmpPrntSpd "Propulsion Motor Oil Pump Percent Speed: Speed of the Propulsion Motor Oil Pump in percentage of maximum speed.  This parameter is used with SPN 23478 (Propulsion Motor Oil Pump Percent Speed Status).";
CM_ BO_ 2566089982 "Electrified Accessory Propulsion Motor Coolant Pump Status 2";
CM_ SG_ 2566089982 PrplsnMtrClntPmpVltg "Propulsion Motor Coolant Pump Voltage: The voltage level of the electrical bus that is utilized by this device as the power source/sink for generating motor torque, as measured at the input of this device.  Note that one design alternative for this d...";
CM_ SG_ 2566089982 PrplsnMtrClntPmpCrrnt "Propulsion Motor Coolant Pump Current: The current in or out of this device with respect to the electrical bus that is utilized by this device as the power source/sink for generating motor torque.  This parameter should be synchronized with SPN 22662...";
CM_ SG_ 2566089982 PrplsnMtrClntPmpHvlStts "Propulsion Motor Coolant Pump HVIL Status: High Voltage Interlock Loop (HVIL) state, as measured by this device.00b = HVIL Closed01b = HVIL Open10b = Error11b = Not Available";
CM_ SG_ 2566089982 PrplsnMtrClntPmpPrntSpdStts "Propulsion Motor Coolant Pump Percent Speed Status: Enable and direction status of the Propulsion Motor Coolant Pump system or component.  This parameter is used with SPN 23481 (Propulsion Motor Coolant Pump Percent Speed).00b = Accessory Motor Off01...";
CM_ SG_ 2566089982 PrplsnMtrClntPmpPrntSpd "Propulsion Motor Coolant Pump Percent Speed: Speed of the Propulsion Motor Coolant Pump in percentage of maximum speed.  This parameter is used with SPN 23480 (Propulsion Motor Coolant Pump Percent Speed Status).";
CM_ BO_ 2566090238 "Electrified Accessory Power Electronics Coolant Pump Status 2";
CM_ SG_ 2566090238 PwrEltrnsClntPmpVltg "Power Electronics Coolant Pump Voltage: The voltage level of the electrical bus that is utilized by this device as the power source/sink for generating motor torque, as measured at the input of this device.  Note that one design alternative for this ...";
CM_ SG_ 2566090238 PwrEltrnsClntPmpCrrnt "Power Electronics Coolant Pump Current: The current in or out of this device with respect to the electrical bus that is utilized by this device as the power source/sink for generating motor torque.  This parameter should be synchronized with SPN 2266...";
CM_ SG_ 2566090238 PwrEltrnsClntPmpHvlStts "Power Electronics Coolant Pump HVIL Status: High Voltage Interlock Loop (HVIL) state, as measured by this device.00b = HVIL Closed01b = HVIL Open10b = Error11b = Not Available";
CM_ SG_ 2566090238 PwrEltrnsClntPmpPrntSpdStts "Power Electronics Coolant Pump Percent Speed Status: Enable and direction status of the Power Electronics Coolant Pump system or component.  This parameter is used with SPN 23483 (Power Electronics Coolant Pump Percent Speed).00b = Accessory Motor Of...";
CM_ SG_ 2566090238 PwrEltrnsClntPmpPrntSpd "Power Electronics Coolant Pump Percent Speed: Speed of the Power Electronics Coolant Pump in percentage of maximum speed.  This parameter is used with SPN 23482 (Power Electronics Coolant Pump Percent Speed Status).";
CM_ BO_ 2566090494 "Electrified Accessory Generator Coolant Pump Status 2";
CM_ SG_ 2566090494 GeneratorCoolantPumpVoltage "Generator Coolant Pump Voltage: The voltage level of the electrical bus that is utilized by this device as the power source/sink for generating motor torque, as measured at the input of this device.  Note that one design alternative for this device u...";
CM_ SG_ 2566090494 GeneratorCoolantPumpCurrent "Generator Coolant Pump Current: The current in or out of this device with respect to the electrical bus that is utilized by this device as the power source/sink for generating motor torque.  This parameter should be synchronized with SPN 22668 (Gener...";
CM_ SG_ 2566090494 GeneratorCoolantPumpHvilStatus "Generator Coolant Pump HVIL Status: High Voltage Interlock Loop (HVIL) state, as measured by this device.00b = HVIL Closed01b = HVIL Open10b = Error11b = Not Available";
CM_ SG_ 2566090494 GnrtrClntPmpPrntSpdStts "Generator Coolant Pump Percent Speed Status: Enable and direction status of the Generator Coolant Pump system or component.  This parameter is used with SPN 23485 (Generator Coolant Pump Percent Speed).00b = Accessory Motor Off01b = Accessory Motor O...";
CM_ SG_ 2566090494 GnrtrClntPmpPrntSpd "Generator Coolant Pump Percent Speed: Speed of the Generator Coolant Pump in percentage of maximum speed.  This parameter is used with SPN 23484 (Generator Coolant Pump Percent Speed Status).";
CM_ BO_ 2566090750 "Electrified Accessory Generator Coolant Fan Status 2";
CM_ SG_ 2566090750 GeneratorCoolantFanVoltage "Generator Coolant Fan Voltage: The voltage level of the electrical bus that is utilized by this device as the power source/sink for generating motor torque, as measured at the input of this device.  Note that one design alternative for this device ut...";
CM_ SG_ 2566090750 GeneratorCoolantFanCurrent "Generator Coolant Fan Current: The current in or out of this device with respect to the electrical bus that is utilized by this device as the power source/sink for generating motor torque.  This parameter should be synchronized with SPN 22671 (Genera...";
CM_ SG_ 2566090750 GeneratorCoolantFanHvilStatus "Generator Coolant Fan HVIL Status: High Voltage Interlock Loop (HVIL) state, as measured by this device.00b = HVIL Closed01b = HVIL Open10b = Error11b = Not Available";
CM_ SG_ 2566090750 GnrtrClntFnPrntSpdStts "Generator Coolant Fan Percent Speed Status: Enable and direction status of the Generator Coolant Fan system or component.  This parameter is used with SPN 23487 (Generator Coolant Fan Percent Speed).00b = Accessory Motor Off01b = Accessory Motor On -...";
CM_ SG_ 2566090750 GeneratorCoolantFanPercentSpeed "Generator Coolant Fan Percent Speed: Speed of the Generator Coolant Fan in percentage of maximum speed.  This parameter is used with SPN 23486 (Generator Coolant Fan Percent Speed Status).";
CM_ BO_ 2566091006 "Electrified Accessory Motor Status 2";
CM_ SG_ 2566091006 EltrfdAssrMtrVltg "Electrified Accessory Motor Voltage: The voltage level of the electrical bus that is utilized by this device as the power source/sink for generating motor torque, as measured at the input of this device.  Note that one design alternative for this dev...";
CM_ SG_ 2566091006 EltrfdAssrMtrCrrnt "Electrified Accessory Motor Current: The current in or out of this device with respect to the electrical bus that is utilized by this device as the power source/sink for generating motor torque.  This parameter should be synchronized with SPN 22674 (...";
CM_ SG_ 2566091006 EltrfdAssrMtrHvlStts "Electrified Accessory Motor HVIL Status: High Voltage Interlock Loop (HVIL) state, as measured by this device.00b = HVIL Closed01b = HVIL Open10b = Error11b = Not Available";
CM_ SG_ 2566091006 EltrfdAssrMtrInstnOfSttsDtSt2 "Electrified Accessory Motor Instance of Status Data Set 2: Indicates the electrified accessory instance that is providing status data set 2.0000b = Instance 10001b = Instance 20010b = Instance 30011b = Instance 40100b = Instance 50101b = Instance 601...";
CM_ SG_ 2566091006 EltrfdAssrMtrPrntSpdStts "Electrified Accessory Motor Percent Speed Status: Enable and direction status of the Electrified Accessory Motor system or component.  This parameter is used with SPN 23489 (Electrified Accessory Motor Percent Speed).00b = Accessory Motor Off01b = Ac...";
CM_ SG_ 2566091006 EltrfdAssrMtrPrntSpd "Electrified Accessory Motor Percent Speed: Speed of the Electrified Accessory Motor in percentage of maximum speed.  This parameter is used with SPN 23488 (Electrified Accessory Motor Percent Speed Status).";
CM_ BO_ 2633637886 "Aftertreatment System Information 6";
CM_ SG_ 2633637886 Aftertreatment2DefDosingMode "Aftertreatment 2 DEF Dosing Mode: The present operating state of the DEF doser for aftertreatment 2 (exhaust bank 2) as described by the appropriate regulatory body with the manufacturer.00h = Off, not dosing01h - FAh = Manufacturer Defined, assign f...";
CM_ BO_ 2566529278 "EV Multi-Connection DC Charging Limits 2";
CM_ SG_ 2566529278 Evmcdclim2ExtendedId "EVMCDCLIM2 Extended ID: Single byte extended ID for this PG.It is used to identify the contents of this PG as being specific to a particular EVCC /  EVSE connection.Its numeric value shall be the same as the intended EVCC's J1939 bus address.If a val...";
CM_ SG_ 2566529278 EvMltCnntnBlkSttOfChrg "EV Multi-Connection Bulk State of Charge: State of charge value, as indicated by SPN 22710 (EV Multi-Connection State of Charge), where bulk charging is considered to be complete. (For example 80%)See SAE J2847-2 201504 Sect. 4.2.3";
CM_ SG_ 2566529278 EvMltCnntnFllSttOfChrg "EV Multi-Connection Full State of Charge: State of charge value, as indicated by SPN 22710 (EV Multi-Connection State of Charge), where charging is considered to be complete. (Typically 100%)See SAE J2847-2 201504 Sect. 4.2.57";
CM_ SG_ 2566529278 EvMultiConnectionEnergyCapacity "EV Multi-Connection Energy Capacity: Maximum energy capacity supported by the EV for this connection.See SAE J2847-2 201504 Sect 4.2.24";
CM_ SG_ 2566529278 EvMltCnntnEnrgRqstd "EV Multi-Connection Energy Requested: Amount of energy the EV requests from the EVSE on this connection.See SAE J2847-2 201504 Sect 4.2.25";
CM_ BO_ 2566529534 "EV Multi-Connection Charging In Progress";
CM_ SG_ 2566529534 EvmcdccipExtendedId "EVMCDCCIP Extended ID: Single byte extended ID for this PG.It is used to identify the contents of this PG as being specific to a particular EVCC /  EVSE connection.Its numeric value shall be the same as the intended EVCC's J1939 bus address.If a valu...";
CM_ SG_ 2566529534 EvMltCnntnBlkChrgngCmplt "EV Multi-Connection Bulk Charging Complete: Optional, for EVSE display purposes, this parameter indicates if bulk charging is complete for this connection.00b = Bulk charging not complete01b = Bulk charging complete10b = Error11b = Not availableSee S...";
CM_ SG_ 2566529534 EvMltCnntnFllChrgngCmplt "EV Multi-Connection Full Charging Complete: For EVSE display purposes, this parameter indicates if full charging is complete for this connection.00b = Full charging not complete01b = Full charging complete10b = Error11b = Not availableSee SAE J2847-2...";
CM_ SG_ 2566529534 EvMltCnntnBlkChrgTmRmnng "EV Multi-Connection Bulk Charge Time Remaining: Remaining time to complete bulk charging for this connection.See SAE J2847-2 201504 Sect 4.2.76";
CM_ SG_ 2566529534 EvMltCnntnFllChrgTmRmnng "EV Multi-Connection Full Charge Time Remaining: Remaining time to complete full charging for this connection.See SAE J2847-2 201504 Sect 4.2.77";
CM_ SG_ 2566529534 EvMultiConnectionDepartureTime "EV Multi-Connection Departure Time: Time remaining until the vehicle's expected departure.See ISO 15118-2/Figure 92 Ref. V2G2-371";
BA_DEF_ SG_  "SPN" INT 0 524287;
BA_DEF_ BO_  "VFrameFormat" ENUM  "StandardCAN","ExtendedCAN","reserved","J1939PG";
BA_DEF_DEF_  "SPN" 0;
BA_DEF_DEF_  "VFrameFormat" "J1939PG";
BA_ "SPN" SG_ 2364756990 Hvsp4MxIsttsDsCtLtExtddR 22428;
BA_ "SPN" SG_ 2364756990 Hvsp4MxIsttsCCtLtExtddR 22429;
BA_ "SPN" SG_ 2364756990 Hvsp4NmnlDshrgCrrntLmt 22831;
BA_ "SPN" SG_ 2364756990 Hvesp4NominalChargeCurrentLimit 22832;
BA_ "SPN" SG_ 2364757246 Hvsp5AvllDshrgPwrExtnddRng 22446;
BA_ "SPN" SG_ 2364757246 Hvsp5AvllChrgPwrExtnddRng 22447;
BA_ "SPN" SG_ 2364757246 Hvesp5VoltageLevelExtendedRange 22448;
BA_ "SPN" SG_ 2364757246 Hvesp5CurrentExtendedRange 22449;
BA_ "SPN" SG_ 2364757502 Hvsp5MxIsttsDsCtLtExtddR 22450;
BA_ "SPN" SG_ 2364757502 Hvsp5MxIsttsCCtLtExtddR 22451;
BA_ "SPN" SG_ 2364757502 Hvsp5NmnlDshrgCrrntLmt 22833;
BA_ "SPN" SG_ 2364757502 Hvesp5NominalChargeCurrentLimit 22834;
BA_ "SPN" SG_ 2364757758 Hvsp6AvllDshrgPwrExtnddRng 22468;
BA_ "SPN" SG_ 2364757758 Hvsp6AvllChrgPwrExtnddRng 22469;
BA_ "SPN" SG_ 2364757758 Hvesp6VoltageLevelExtendedRange 22470;
BA_ "SPN" SG_ 2364757758 Hvesp6CurrentExtendedRange 22471;
BA_ "SPN" SG_ 2364758014 Hvsp6MxIsttsDsCtLtExtddR 22472;
BA_ "SPN" SG_ 2364758014 Hvsp6MxIsttsCCtLtExtddR 22473;
BA_ "SPN" SG_ 2364758014 Hvsp6NmnlDshrgCrrntLmt 22835;
BA_ "SPN" SG_ 2364758014 Hvesp6NominalChargeCurrentLimit 22836;
BA_ "SPN" SG_ 2364758270 Hvsp7AvllDshrgPwrExtnddRng 22490;
BA_ "SPN" SG_ 2364758270 Hvsp7AvllChrgPwrExtnddRng 22491;
BA_ "SPN" SG_ 2364758270 Hvesp7VoltageLevelExtendedRange 22492;
BA_ "SPN" SG_ 2364758270 Hvesp7CurrentExtendedRange 22493;
BA_ "SPN" SG_ 2364758526 Hvsp7MxIsttsDsCtLtExtddR 22494;
BA_ "SPN" SG_ 2364758526 Hvsp7MxIsttsCCtLtExtddR 22495;
BA_ "SPN" SG_ 2364758526 Hvsp7NmnlDshrgCrrntLmt 22837;
BA_ "SPN" SG_ 2364758526 Hvesp7NominalChargeCurrentLimit 22838;
BA_ "SPN" SG_ 2364758782 Hvsp8AvllDshrgPwrExtnddRng 22512;
BA_ "SPN" SG_ 2364758782 Hvsp8AvllChrgPwrExtnddRng 22513;
BA_ "SPN" SG_ 2364758782 Hvesp8VoltageLevelExtendedRange 22514;
BA_ "SPN" SG_ 2364758782 Hvesp8CurrentExtendedRange 22515;
BA_ "SPN" SG_ 2364759038 Hvsp8MxIsttsDsCtLtExtddR 22516;
BA_ "SPN" SG_ 2364759038 Hvsp8MxIsttsCCtLtExtddR 22517;
BA_ "SPN" SG_ 2364759038 Hvsp8NmnlDshrgCrrntLmt 22839;
BA_ "SPN" SG_ 2364759038 Hvesp8NominalChargeCurrentLimit 22840;
BA_ "SPN" SG_ 2364759294 Hvsp9AvllDshrgPwrExtnddRng 22534;
BA_ "SPN" SG_ 2364759294 Hvsp9AvllChrgPwrExtnddRng 22535;
BA_ "SPN" SG_ 2364759294 Hvesp9VoltageLevelExtendedRange 22536;
BA_ "SPN" SG_ 2364759294 Hvesp9CurrentExtendedRange 22537;
BA_ "SPN" SG_ 2364759550 Hvsp9MxIsttsDsCtLtExtddR 22538;
BA_ "SPN" SG_ 2364759550 Hvsp9MxIsttsCCtLtExtddR 22539;
BA_ "SPN" SG_ 2364759550 Hvsp9NmnlDshrgCrrntLmt 22841;
BA_ "SPN" SG_ 2364759550 Hvesp9NominalChargeCurrentLimit 22842;
BA_ "SPN" SG_ 2364759806 Hvsp10AvllDshrgPwrExtnddRng 22556;
BA_ "SPN" SG_ 2364759806 Hvsp10AvllChrgPwrExtnddRng 22557;
BA_ "SPN" SG_ 2364759806 Hvsp10VltgLvlExtnddRng 22558;
BA_ "SPN" SG_ 2364759806 Hvesp10CurrentExtendedRange 22559;
BA_ "SPN" SG_ 2364760062 Hvsp10MxIsttsDsCtLtExtddR 22560;
BA_ "SPN" SG_ 2364760062 Hvsp10MxIsttsCCtLtExtddR 22561;
BA_ "SPN" SG_ 2364760062 Hvsp10NmnlDshrgCrrntLmt 22843;
BA_ "SPN" SG_ 2364760062 Hvsp10NmnlChrgCrrntLmt 22844;
BA_ "SPN" SG_ 2364760318 Hvsp11AvllDshrgPwrExtnddRng 22578;
BA_ "SPN" SG_ 2364760318 Hvsp11AvllChrgPwrExtnddRng 22579;
BA_ "SPN" SG_ 2364760318 Hvsp11VltgLvlExtnddRng 22580;
BA_ "SPN" SG_ 2364760318 Hvesp11CurrentExtendedRange 22581;
BA_ "SPN" SG_ 2364760574 Hvsp11MxIsttsDsCtLtExtddR 22582;
BA_ "SPN" SG_ 2364760574 Hvsp11MxIsttsCCtLtExtddR 22583;
BA_ "SPN" SG_ 2364760574 Hvsp11NmnlDshrgCrrntLmt 22845;
BA_ "SPN" SG_ 2364760574 Hvsp11NmnlChrgCrrntLmt 22846;
BA_ "SPN" SG_ 2364760830 Hvsp12AvllDshrgPwrExtnddRng 22600;
BA_ "SPN" SG_ 2364760830 Hvsp12AvllChrgPwrExtnddRng 22601;
BA_ "SPN" SG_ 2364760830 Hvsp12VltgLvlExtnddRng 22602;
BA_ "SPN" SG_ 2364760830 Hvesp12CurrentExtendedRange 22603;
BA_ "SPN" SG_ 2364761086 Hvsp12MxIsttsDsCtLtExtddR 22604;
BA_ "SPN" SG_ 2364761086 Hvsp12MxIsttsCCtLtExtddR 22605;
BA_ "SPN" SG_ 2364761086 Hvsp12NmnlDshrgCrrntLmt 22847;
BA_ "SPN" SG_ 2364761086 Hvsp12NmnlChrgCrrntLmt 22848;
BA_ "SPN" SG_ 2365203710 HvessIntakeCoolantPressure 22350;
BA_ "SPN" SG_ 2365203710 HvssEstmtdDshrgTmRmnng 22348;
BA_ "SPN" SG_ 2365203710 HvssEstmtdChrgTmRmnng 22349;
BA_ "SPN" SG_ 2365203710 HvssHghVltgExpsrIndtr 22817;
BA_ "SPN" SG_ 2365203710 HvessPowerHoldRelayStatus 22818;
BA_ "SPN" SG_ 2365203710 HvssHghVltgBsPstvPrChrgRlStt 22819;
BA_ "SPN" SG_ 2365203710 HvssHghVltgBsNgtvPrChrgRlStt 22820;
BA_ "SPN" SG_ 2365203966 HvssAvllDshrgPwrExtnddRng 22353;
BA_ "SPN" SG_ 2365203966 HvssAvllChrgPwrExtnddRng 22354;
BA_ "SPN" SG_ 2365203966 HvessVoltageLevelExtendedRange 22352;
BA_ "SPN" SG_ 2365203966 HvessCurrentExtendedRange 22351;
BA_ "SPN" SG_ 2365204222 HvessBusVoltageExtendedRange 22357;
BA_ "SPN" SG_ 2365204222 HvssMxIsttsDsCtLtExtddR 22355;
BA_ "SPN" SG_ 2365204222 HvssMxIsttsCCtLtExtddR 22356;
BA_ "SPN" SG_ 2365204222 HvssMnmmDshrgVltgLmt 23055;
BA_ "SPN" SG_ 2365204478 Hvsp1HghVltgIntrnlNgtvCnttr1Stt 22364;
BA_ "SPN" SG_ 2365204478 Hvsp1HghVltgIntrnlNgtvCnttr2Stt 22365;
BA_ "SPN" SG_ 2365204478 Hvsp1HghVltgIntrnlNgtvCnttr3Stt 22366;
BA_ "SPN" SG_ 2365204478 Hvsp1HghVltgIntrnlNgtvCnttr4Stt 22367;
BA_ "SPN" SG_ 2365204478 Hvsp1HghVltgIntrnlNgtvCnttr5Stt 22368;
BA_ "SPN" SG_ 2365204478 Hvsp1HghVltgIntrnlNgtvCnttr6Stt 22369;
BA_ "SPN" SG_ 2365204478 Hvsp1HghVltgIntrnlNgtvCnttr7Stt 22370;
BA_ "SPN" SG_ 2365204478 Hvsp1HghVltgIntrnlNgtvCnttr8Stt 22371;
BA_ "SPN" SG_ 2365204478 Hvsp1HghVltgIntrnlPstvCnttr1Stt 22372;
BA_ "SPN" SG_ 2365204478 Hvsp1HghVltgIntrnlPstvCnttr2Stt 22373;
BA_ "SPN" SG_ 2365204478 Hvsp1HghVltgIntrnlPstvCnttr3Stt 22374;
BA_ "SPN" SG_ 2365204478 Hvsp1HghVltgIntrnlPstvCnttr4Stt 22375;
BA_ "SPN" SG_ 2365204478 Hvsp1HghVltgIntrnlPstvCnttr5Stt 22376;
BA_ "SPN" SG_ 2365204478 Hvsp1HghVltgIntrnlPstvCnttr6Stt 22377;
BA_ "SPN" SG_ 2365204478 Hvsp1HghVltgIntrnlPstvCnttr7Stt 22378;
BA_ "SPN" SG_ 2365204478 Hvsp1HghVltgIntrnlPstvCnttr8Stt 22379;
BA_ "SPN" SG_ 2365204734 Hvsp2HghVltgIntrnlNgtvCnttr1Stt 22386;
BA_ "SPN" SG_ 2365204734 Hvsp2HghVltgIntrnlNgtvCnttr2Stt 22387;
BA_ "SPN" SG_ 2365204734 Hvsp2HghVltgIntrnlNgtvCnttr3Stt 22388;
BA_ "SPN" SG_ 2365204734 Hvsp2HghVltgIntrnlNgtvCnttr4Stt 22389;
BA_ "SPN" SG_ 2365204734 Hvsp2HghVltgIntrnlNgtvCnttr5Stt 22390;
BA_ "SPN" SG_ 2365204734 Hvsp2HghVltgIntrnlNgtvCnttr6Stt 22391;
BA_ "SPN" SG_ 2365204734 Hvsp2HghVltgIntrnlNgtvCnttr7Stt 22392;
BA_ "SPN" SG_ 2365204734 Hvsp2HghVltgIntrnlNgtvCnttr8Stt 22393;
BA_ "SPN" SG_ 2365204734 Hvsp2HghVltgIntrnlPstvCnttr1Stt 22394;
BA_ "SPN" SG_ 2365204734 Hvsp2HghVltgIntrnlPstvCnttr2Stt 22395;
BA_ "SPN" SG_ 2365204734 Hvsp2HghVltgIntrnlPstvCnttr3Stt 22396;
BA_ "SPN" SG_ 2365204734 Hvsp2HghVltgIntrnlPstvCnttr4Stt 22397;
BA_ "SPN" SG_ 2365204734 Hvsp2HghVltgIntrnlPstvCnttr5Stt 22398;
BA_ "SPN" SG_ 2365204734 Hvsp2HghVltgIntrnlPstvCnttr6Stt 22399;
BA_ "SPN" SG_ 2365204734 Hvsp2HghVltgIntrnlPstvCnttr7Stt 22400;
BA_ "SPN" SG_ 2365204734 Hvsp2HghVltgIntrnlPstvCnttr8Stt 22401;
BA_ "SPN" SG_ 2365204990 Hvsp3HghVltgIntrnlNgtvCnttr1Stt 22408;
BA_ "SPN" SG_ 2365204990 Hvsp3HghVltgIntrnlNgtvCnttr2Stt 22409;
BA_ "SPN" SG_ 2365204990 Hvsp3HghVltgIntrnlNgtvCnttr3Stt 22410;
BA_ "SPN" SG_ 2365204990 Hvsp3HghVltgIntrnlNgtvCnttr4Stt 22411;
BA_ "SPN" SG_ 2365204990 Hvsp3HghVltgIntrnlNgtvCnttr5Stt 22412;
BA_ "SPN" SG_ 2365204990 Hvsp3HghVltgIntrnlNgtvCnttr6Stt 22413;
BA_ "SPN" SG_ 2365204990 Hvsp3HghVltgIntrnlNgtvCnttr7Stt 22414;
BA_ "SPN" SG_ 2365204990 Hvsp3HghVltgIntrnlNgtvCnttr8Stt 22415;
BA_ "SPN" SG_ 2365204990 Hvsp3HghVltgIntrnlPstvCnttr1Stt 22416;
BA_ "SPN" SG_ 2365204990 Hvsp3HghVltgIntrnlPstvCnttr2Stt 22417;
BA_ "SPN" SG_ 2365204990 Hvsp3HghVltgIntrnlPstvCnttr3Stt 22418;
BA_ "SPN" SG_ 2365204990 Hvsp3HghVltgIntrnlPstvCnttr4Stt 22419;
BA_ "SPN" SG_ 2365204990 Hvsp3HghVltgIntrnlPstvCnttr5Stt 22420;
BA_ "SPN" SG_ 2365204990 Hvsp3HghVltgIntrnlPstvCnttr6Stt 22421;
BA_ "SPN" SG_ 2365204990 Hvsp3HghVltgIntrnlPstvCnttr7Stt 22422;
BA_ "SPN" SG_ 2365204990 Hvsp3HghVltgIntrnlPstvCnttr8Stt 22423;
BA_ "SPN" SG_ 2365205246 Hvsp4HghVltgIntrnlNgtvCnttr1Stt 22430;
BA_ "SPN" SG_ 2365205246 Hvsp4HghVltgIntrnlNgtvCnttr2Stt 22431;
BA_ "SPN" SG_ 2365205246 Hvsp4HghVltgIntrnlNgtvCnttr3Stt 22432;
BA_ "SPN" SG_ 2365205246 Hvsp4HghVltgIntrnlNgtvCnttr4Stt 22433;
BA_ "SPN" SG_ 2365205246 Hvsp4HghVltgIntrnlNgtvCnttr5Stt 22434;
BA_ "SPN" SG_ 2365205246 Hvsp4HghVltgIntrnlNgtvCnttr6Stt 22435;
BA_ "SPN" SG_ 2365205246 Hvsp4HghVltgIntrnlNgtvCnttr7Stt 22436;
BA_ "SPN" SG_ 2365205246 Hvsp4HghVltgIntrnlNgtvCnttr8Stt 22437;
BA_ "SPN" SG_ 2365205246 Hvsp4HghVltgIntrnlPstvCnttr1Stt 22438;
BA_ "SPN" SG_ 2365205246 Hvsp4HghVltgIntrnlPstvCnttr2Stt 22439;
BA_ "SPN" SG_ 2365205246 Hvsp4HghVltgIntrnlPstvCnttr3Stt 22440;
BA_ "SPN" SG_ 2365205246 Hvsp4HghVltgIntrnlPstvCnttr4Stt 22441;
BA_ "SPN" SG_ 2365205246 Hvsp4HghVltgIntrnlPstvCnttr5Stt 22442;
BA_ "SPN" SG_ 2365205246 Hvsp4HghVltgIntrnlPstvCnttr6Stt 22443;
BA_ "SPN" SG_ 2365205246 Hvsp4HghVltgIntrnlPstvCnttr7Stt 22444;
BA_ "SPN" SG_ 2365205246 Hvsp4HghVltgIntrnlPstvCnttr8Stt 22445;
BA_ "SPN" SG_ 2365205502 Hvsp5HghVltgIntrnlNgtvCnttr1Stt 22452;
BA_ "SPN" SG_ 2365205502 Hvsp5HghVltgIntrnlNgtvCnttr2Stt 22453;
BA_ "SPN" SG_ 2365205502 Hvsp5HghVltgIntrnlNgtvCnttr3Stt 22454;
BA_ "SPN" SG_ 2365205502 Hvsp5HghVltgIntrnlNgtvCnttr4Stt 22455;
BA_ "SPN" SG_ 2365205502 Hvsp5HghVltgIntrnlNgtvCnttr5Stt 22456;
BA_ "SPN" SG_ 2365205502 Hvsp5HghVltgIntrnlNgtvCnttr6Stt 22457;
BA_ "SPN" SG_ 2365205502 Hvsp5HghVltgIntrnlNgtvCnttr7Stt 22458;
BA_ "SPN" SG_ 2365205502 Hvsp5HghVltgIntrnlNgtvCnttr8Stt 22459;
BA_ "SPN" SG_ 2365205502 Hvsp5HghVltgIntrnlPstvCnttr1Stt 22460;
BA_ "SPN" SG_ 2365205502 Hvsp5HghVltgIntrnlPstvCnttr2Stt 22461;
BA_ "SPN" SG_ 2365205502 Hvsp5HghVltgIntrnlPstvCnttr3Stt 22462;
BA_ "SPN" SG_ 2365205502 Hvsp5HghVltgIntrnlPstvCnttr4Stt 22463;
BA_ "SPN" SG_ 2365205502 Hvsp5HghVltgIntrnlPstvCnttr5Stt 22464;
BA_ "SPN" SG_ 2365205502 Hvsp5HghVltgIntrnlPstvCnttr6Stt 22465;
BA_ "SPN" SG_ 2365205502 Hvsp5HghVltgIntrnlPstvCnttr7Stt 22466;
BA_ "SPN" SG_ 2365205502 Hvsp5HghVltgIntrnlPstvCnttr8Stt 22467;
BA_ "SPN" SG_ 2365205758 Hvsp6HghVltgIntrnlNgtvCnttr1Stt 22474;
BA_ "SPN" SG_ 2365205758 Hvsp6HghVltgIntrnlNgtvCnttr2Stt 22475;
BA_ "SPN" SG_ 2365205758 Hvsp6HghVltgIntrnlNgtvCnttr3Stt 22476;
BA_ "SPN" SG_ 2365205758 Hvsp6HghVltgIntrnlNgtvCnttr4Stt 22477;
BA_ "SPN" SG_ 2365205758 Hvsp6HghVltgIntrnlNgtvCnttr5Stt 22478;
BA_ "SPN" SG_ 2365205758 Hvsp6HghVltgIntrnlNgtvCnttr6Stt 22479;
BA_ "SPN" SG_ 2365205758 Hvsp6HghVltgIntrnlNgtvCnttr7Stt 22480;
BA_ "SPN" SG_ 2365205758 Hvsp6HghVltgIntrnlNgtvCnttr8Stt 22481;
BA_ "SPN" SG_ 2365205758 Hvsp6HghVltgIntrnlPstvCnttr1Stt 22482;
BA_ "SPN" SG_ 2365205758 Hvsp6HghVltgIntrnlPstvCnttr2Stt 22483;
BA_ "SPN" SG_ 2365205758 Hvsp6HghVltgIntrnlPstvCnttr3Stt 22484;
BA_ "SPN" SG_ 2365205758 Hvsp6HghVltgIntrnlPstvCnttr4Stt 22485;
BA_ "SPN" SG_ 2365205758 Hvsp6HghVltgIntrnlPstvCnttr5Stt 22486;
BA_ "SPN" SG_ 2365205758 Hvsp6HghVltgIntrnlPstvCnttr6Stt 22487;
BA_ "SPN" SG_ 2365205758 Hvsp6HghVltgIntrnlPstvCnttr7Stt 22488;
BA_ "SPN" SG_ 2365205758 Hvsp6HghVltgIntrnlPstvCnttr8Stt 22489;
BA_ "SPN" SG_ 2365206014 Hvsp7HghVltgIntrnlNgtvCnttr1Stt 22496;
BA_ "SPN" SG_ 2365206014 Hvsp7HghVltgIntrnlNgtvCnttr2Stt 22497;
BA_ "SPN" SG_ 2365206014 Hvsp7HghVltgIntrnlNgtvCnttr3Stt 22498;
BA_ "SPN" SG_ 2365206014 Hvsp7HghVltgIntrnlNgtvCnttr4Stt 22499;
BA_ "SPN" SG_ 2365206014 Hvsp7HghVltgIntrnlNgtvCnttr5Stt 22500;
BA_ "SPN" SG_ 2365206014 Hvsp7HghVltgIntrnlNgtvCnttr6Stt 22501;
BA_ "SPN" SG_ 2365206014 Hvsp7HghVltgIntrnlNgtvCnttr7Stt 22502;
BA_ "SPN" SG_ 2365206014 Hvsp7HghVltgIntrnlNgtvCnttr8Stt 22503;
BA_ "SPN" SG_ 2365206014 Hvsp7HghVltgIntrnlPstvCnttr1Stt 22504;
BA_ "SPN" SG_ 2365206014 Hvsp7HghVltgIntrnlPstvCnttr2Stt 22505;
BA_ "SPN" SG_ 2365206014 Hvsp7HghVltgIntrnlPstvCnttr3Stt 22506;
BA_ "SPN" SG_ 2365206014 Hvsp7HghVltgIntrnlPstvCnttr4Stt 22507;
BA_ "SPN" SG_ 2365206014 Hvsp7HghVltgIntrnlPstvCnttr5Stt 22508;
BA_ "SPN" SG_ 2365206014 Hvsp7HghVltgIntrnlPstvCnttr6Stt 22509;
BA_ "SPN" SG_ 2365206014 Hvsp7HghVltgIntrnlPstvCnttr7Stt 22510;
BA_ "SPN" SG_ 2365206014 Hvsp7HghVltgIntrnlPstvCnttr8Stt 22511;
BA_ "SPN" SG_ 2365206270 Hvsp8HghVltgIntrnlNgtvCnttr1Stt 22518;
BA_ "SPN" SG_ 2365206270 Hvsp8HghVltgIntrnlNgtvCnttr2Stt 22519;
BA_ "SPN" SG_ 2365206270 Hvsp8HghVltgIntrnlNgtvCnttr3Stt 22520;
BA_ "SPN" SG_ 2365206270 Hvsp8HghVltgIntrnlNgtvCnttr4Stt 22521;
BA_ "SPN" SG_ 2365206270 Hvsp8HghVltgIntrnlNgtvCnttr5Stt 22522;
BA_ "SPN" SG_ 2365206270 Hvsp8HghVltgIntrnlNgtvCnttr6Stt 22523;
BA_ "SPN" SG_ 2365206270 Hvsp8HghVltgIntrnlNgtvCnttr7Stt 22524;
BA_ "SPN" SG_ 2365206270 Hvsp8HghVltgIntrnlNgtvCnttr8Stt 22525;
BA_ "SPN" SG_ 2365206270 Hvsp8HghVltgIntrnlPstvCnttr1Stt 22526;
BA_ "SPN" SG_ 2365206270 Hvsp8HghVltgIntrnlPstvCnttr2Stt 22527;
BA_ "SPN" SG_ 2365206270 Hvsp8HghVltgIntrnlPstvCnttr3Stt 22528;
BA_ "SPN" SG_ 2365206270 Hvsp8HghVltgIntrnlPstvCnttr4Stt 22529;
BA_ "SPN" SG_ 2365206270 Hvsp8HghVltgIntrnlPstvCnttr5Stt 22530;
BA_ "SPN" SG_ 2365206270 Hvsp8HghVltgIntrnlPstvCnttr6Stt 22531;
BA_ "SPN" SG_ 2365206270 Hvsp8HghVltgIntrnlPstvCnttr7Stt 22532;
BA_ "SPN" SG_ 2365206270 Hvsp8HghVltgIntrnlPstvCnttr8Stt 22533;
BA_ "SPN" SG_ 2365206526 Hvsp9HghVltgIntrnlNgtvCnttr1Stt 22540;
BA_ "SPN" SG_ 2365206526 Hvsp9HghVltgIntrnlNgtvCnttr2Stt 22541;
BA_ "SPN" SG_ 2365206526 Hvsp9HghVltgIntrnlNgtvCnttr3Stt 22542;
BA_ "SPN" SG_ 2365206526 Hvsp9HghVltgIntrnlNgtvCnttr4Stt 22543;
BA_ "SPN" SG_ 2365206526 Hvsp9HghVltgIntrnlNgtvCnttr5Stt 22544;
BA_ "SPN" SG_ 2365206526 Hvsp9HghVltgIntrnlNgtvCnttr6Stt 22545;
BA_ "SPN" SG_ 2365206526 Hvsp9HghVltgIntrnlNgtvCnttr7Stt 22546;
BA_ "SPN" SG_ 2365206526 Hvsp9HghVltgIntrnlNgtvCnttr8Stt 22547;
BA_ "SPN" SG_ 2365206526 Hvsp9HghVltgIntrnlPstvCnttr1Stt 22548;
BA_ "SPN" SG_ 2365206526 Hvsp9HghVltgIntrnlPstvCnttr2Stt 22549;
BA_ "SPN" SG_ 2365206526 Hvsp9HghVltgIntrnlPstvCnttr3Stt 22550;
BA_ "SPN" SG_ 2365206526 Hvsp9HghVltgIntrnlPstvCnttr4Stt 22551;
BA_ "SPN" SG_ 2365206526 Hvsp9HghVltgIntrnlPstvCnttr5Stt 22552;
BA_ "SPN" SG_ 2365206526 Hvsp9HghVltgIntrnlPstvCnttr6Stt 22553;
BA_ "SPN" SG_ 2365206526 Hvsp9HghVltgIntrnlPstvCnttr7Stt 22554;
BA_ "SPN" SG_ 2365206526 Hvsp9HghVltgIntrnlPstvCnttr8Stt 22555;
BA_ "SPN" SG_ 2365206782 Hvsp10HVtItNtvCtt1Stt 22562;
BA_ "SPN" SG_ 2365206782 Hvsp10HVtItNtvCtt2Stt 22563;
BA_ "SPN" SG_ 2365206782 Hvsp10HVtItNtvCtt3Stt 22564;
BA_ "SPN" SG_ 2365206782 Hvsp10HVtItNtvCtt4Stt 22565;
BA_ "SPN" SG_ 2365206782 Hvsp10HVtItNtvCtt5Stt 22566;
BA_ "SPN" SG_ 2365206782 Hvsp10HVtItNtvCtt6Stt 22567;
BA_ "SPN" SG_ 2365206782 Hvsp10HVtItNtvCtt7Stt 22568;
BA_ "SPN" SG_ 2365206782 Hvsp10HVtItNtvCtt8Stt 22569;
BA_ "SPN" SG_ 2365206782 Hvsp10HVtItPstvCtt1Stt 22570;
BA_ "SPN" SG_ 2365206782 Hvsp10HVtItPstvCtt2Stt 22571;
BA_ "SPN" SG_ 2365206782 Hvsp10HVtItPstvCtt3Stt 22572;
BA_ "SPN" SG_ 2365206782 Hvsp10HVtItPstvCtt4Stt 22573;
BA_ "SPN" SG_ 2365206782 Hvsp10HVtItPstvCtt5Stt 22574;
BA_ "SPN" SG_ 2365206782 Hvsp10HVtItPstvCtt6Stt 22575;
BA_ "SPN" SG_ 2365206782 Hvsp10HVtItPstvCtt7Stt 22576;
BA_ "SPN" SG_ 2365206782 Hvsp10HVtItPstvCtt8Stt 22577;
BA_ "SPN" SG_ 2365207038 Hvsp11HVtItNtvCtt1Stt 22584;
BA_ "SPN" SG_ 2365207038 Hvsp11HVtItNtvCtt2Stt 22585;
BA_ "SPN" SG_ 2365207038 Hvsp11HVtItNtvCtt3Stt 22586;
BA_ "SPN" SG_ 2365207038 Hvsp11HVtItNtvCtt4Stt 22587;
BA_ "SPN" SG_ 2365207038 Hvsp11HVtItNtvCtt5Stt 22588;
BA_ "SPN" SG_ 2365207038 Hvsp11HVtItNtvCtt6Stt 22589;
BA_ "SPN" SG_ 2365207038 Hvsp11HVtItNtvCtt7Stt 22590;
BA_ "SPN" SG_ 2365207038 Hvsp11HVtItNtvCtt8Stt 22591;
BA_ "SPN" SG_ 2365207038 Hvsp11HVtItPstvCtt1Stt 22592;
BA_ "SPN" SG_ 2365207038 Hvsp11HVtItPstvCtt2Stt 22593;
BA_ "SPN" SG_ 2365207038 Hvsp11HVtItPstvCtt3Stt 22594;
BA_ "SPN" SG_ 2365207038 Hvsp11HVtItPstvCtt4Stt 22595;
BA_ "SPN" SG_ 2365207038 Hvsp11HVtItPstvCtt5Stt 22596;
BA_ "SPN" SG_ 2365207038 Hvsp11HVtItPstvCtt6Stt 22597;
BA_ "SPN" SG_ 2365207038 Hvsp11HVtItPstvCtt7Stt 22598;
BA_ "SPN" SG_ 2365207038 Hvsp11HVtItPstvCtt8Stt 22599;
BA_ "SPN" SG_ 2365207294 Hvsp12HVtItNtvCtt1Stt 22606;
BA_ "SPN" SG_ 2365207294 Hvsp12HVtItNtvCtt2Stt 22607;
BA_ "SPN" SG_ 2365207294 Hvsp12HVtItNtvCtt3Stt 22608;
BA_ "SPN" SG_ 2365207294 Hvsp12HVtItNtvCtt4Stt 22609;
BA_ "SPN" SG_ 2365207294 Hvsp12HVtItNtvCtt5Stt 22610;
BA_ "SPN" SG_ 2365207294 Hvsp12HVtItNtvCtt6Stt 22611;
BA_ "SPN" SG_ 2365207294 Hvsp12HVtItNtvCtt7Stt 22612;
BA_ "SPN" SG_ 2365207294 Hvsp12HVtItNtvCtt8Stt 22613;
BA_ "SPN" SG_ 2365207294 Hvsp12HVtItPstvCtt1Stt 22614;
BA_ "SPN" SG_ 2365207294 Hvsp12HVtItPstvCtt2Stt 22615;
BA_ "SPN" SG_ 2365207294 Hvsp12HVtItPstvCtt3Stt 22616;
BA_ "SPN" SG_ 2365207294 Hvsp12HVtItPstvCtt4Stt 22617;
BA_ "SPN" SG_ 2365207294 Hvsp12HVtItPstvCtt5Stt 22618;
BA_ "SPN" SG_ 2365207294 Hvsp12HVtItPstvCtt6Stt 22619;
BA_ "SPN" SG_ 2365207294 Hvsp12HVtItPstvCtt7Stt 22620;
BA_ "SPN" SG_ 2365207294 Hvsp12HVtItPstvCtt8Stt 22621;
BA_ "SPN" SG_ 2499425790 RefuseTransitStatus 22313;
BA_ "SPN" SG_ 2499425790 RefuseFrontLoaderArmPosition 22314;
BA_ "SPN" SG_ 2499425790 RefuseFrontLoaderForkPosition 22315;
BA_ "SPN" SG_ 2499425790 RefuseTailgatePosition 22316;
BA_ "SPN" SG_ 2499425790 RefuseOverheightOverwidthStatus 22317;
BA_ "SPN" SG_ 2566534910 EngnThrttlVlv1OtltPrssr 22309;
BA_ "SPN" SG_ 2566534910 EngnThrttlVlv1OtltAsltPrssr 22310;
BA_ "SPN" SG_ 2566534910 EngnThrttlVlv2OtltPrssr 22311;
BA_ "SPN" SG_ 2566534910 EngnThrttlVlv2OtltAsltPrssr 22312;
BA_ "SPN" SG_ 2566535166 WSttLwFwTsssCtIstt 22193;
BA_ "SPN" SG_ 2566535166 WSttLwFwTsssCtIptCt 22194;
BA_ "SPN" SG_ 2566535166 WSttLwFwTsssCtDsdSpdIptCt 22195;
BA_ "SPN" SG_ 2566535166 WSttLwFwTsssCtHdStts 22196;
BA_ "SPN" SG_ 2566535166 WllStmltnPmpOtltPrssrHghLmt 22197;
BA_ "SPN" SG_ 2566535166 WellStimulationPumpDriveType 22198;
BA_ "SPN" SG_ 2566535166 WSttTsssTs1ECtAtCd 22216;
BA_ "SPN" SG_ 2566535422 WllStmltnPmpOtltPrssrLvl1Prnt 22199;
BA_ "SPN" SG_ 2566535422 WllStmltnPmpOtltPrssrLvl2Prnt 22200;
BA_ "SPN" SG_ 2566535422 WllStmltnPmpOtltPrssrLvl3Prnt 22201;
BA_ "SPN" SG_ 2566535422 WllStmltnPmpOtltPrssrLvl4Prnt 22202;
BA_ "SPN" SG_ 2566535422 WllStmltnPmpOtltPrssrLvl5Prnt 22203;
BA_ "SPN" SG_ 2566535422 WllStmltnPdOprtngPrssrUpprLmt 22204;
BA_ "SPN" SG_ 2566535422 WSttPpOttPssDFAv 22205;
BA_ "SPN" SG_ 2566535422 WllStmltnSstmCntrllrEnlStts 22206;
BA_ "SPN" SG_ 2566535678 WllStmltnDshrgPrssrRspnsLvl1Ftr 22207;
BA_ "SPN" SG_ 2566535678 WllStmltnDshrgPrssrRspnsLvl2Ftr 22208;
BA_ "SPN" SG_ 2566535678 WllStmltnDshrgPrssrRspnsLvl3Ftr 22209;
BA_ "SPN" SG_ 2566535678 WllStmltnDshrgPrssrRspnsLvl4Ftr 22210;
BA_ "SPN" SG_ 2566535678 WllStmltnDshrgPrssrRspnsLvl5Ftr 22211;
BA_ "SPN" SG_ 2566535678 WllStmltnIntlRmpGnFtr 22212;
BA_ "SPN" SG_ 2566535678 WSttOttPssPttLvAtvStts 22213;
BA_ "SPN" SG_ 2566535934 ElectricPtoDriveEngagement1Crc 22146;
BA_ "SPN" SG_ 2566535934 EltrPtDrvEnggmnt1Cntr 22147;
BA_ "SPN" SG_ 2566535934 EnableSwitchEpto1 22148;
BA_ "SPN" SG_ 2566535934 EngagementConsentEpto1 22149;
BA_ "SPN" SG_ 2566535934 EngagementStatusEpto1 22150;
BA_ "SPN" SG_ 2566535934 EmergencyDeEnergizeSwitchEpto1 22151;
BA_ "SPN" SG_ 2566535934 SystemReadinessEpto1 22152;
BA_ "SPN" SG_ 2566535934 ErrorIndicatorEpto1 22153;
BA_ "SPN" SG_ 2566536190 Epto1CurrentLimit 22154;
BA_ "SPN" SG_ 2566536190 Epto1Current 22155;
BA_ "SPN" SG_ 2566536190 Epto1Voltage 22156;
BA_ "SPN" SG_ 2566536446 EngnExhstO2Snsr1ArFlEqvlnRt 22139;
BA_ "SPN" SG_ 2566536446 EngineExhaustO2Sensor1Voltage 22140;
BA_ "SPN" SG_ 2566536446 EngnExhstO2Snsr2ArFlEqvlnRt 22141;
BA_ "SPN" SG_ 2566536446 EngineExhaustO2Sensor2Voltage 22142;
BA_ "SPN" SG_ 2566536702 EngnGssFl2SpplPrssr1 21843;
BA_ "SPN" SG_ 2566536702 EGssF1SppPssRtOttPss 21844;
BA_ "SPN" SG_ 2566536702 EGssF2SppPssRtOttPss 21845;
BA_ "SPN" SG_ 2566536702 EngnGssFl1SpplPrssrRgltrPstn 21846;
BA_ "SPN" SG_ 2566536702 EngnGssFl2SpplPrssrRgltrPstn 21847;
BA_ "SPN" SG_ 2499428094 TrafficSignSpeedLimit 21793;
BA_ "SPN" SG_ 2566537214 EngnClngFnClntAtvtnTmprtr 21790;
BA_ "SPN" SG_ 2566537214 EngnClngFnIntkMnfldAtvtnTmprtr 21791;
BA_ "SPN" SG_ 2633768190 RefrigeratedCompartmentPosition 3320;
BA_ "SPN" SG_ 2633768190 RefrigeratedCompartmentId 3321;
BA_ "SPN" SG_ 2633768190 RefrigeratedCompartmentHumidity 3449;
BA_ "SPN" SG_ 2633768190 RfrgrtdCmprtmntTmprtr 3450;
BA_ "SPN" SG_ 2633768446 TransportationCompartmentDoorId 3616;
BA_ "SPN" SG_ 2633768446 TrnsprttnCmprtmntDrStts 3617;
BA_ "SPN" SG_ 2352611070 ExtrnlAAlrtnRqstCr 22128;
BA_ "SPN" SG_ 2352611070 ExtrnlAAlrtnRqstCntr 22129;
BA_ "SPN" SG_ 2352611070 ExternalAccAccelerationRequest 22126;
BA_ "SPN" SG_ 2352611070 ExtrnlAAlrtnRqstCntrlMd 22127;
BA_ "SPN" SG_ 2352611070 InMessageIntegrityDataSupported 22622;
BA_ "SPN" SG_ 2554003198 ChargerCommandCrc 22679;
BA_ "SPN" SG_ 2554003198 ChargerCommandSequenceCounter 22680;
BA_ "SPN" SG_ 2554003198 ChargerCommandTargetVoltage 22681;
BA_ "SPN" SG_ 2554003198 ChargerCommandTargetCurrent 22682;
BA_ "SPN" SG_ 2554068734 AuxChargerCommandCrc 22683;
BA_ "SPN" SG_ 2554068734 AxChrgrCmmndSqnCntr 22684;
BA_ "SPN" SG_ 2554068734 AuxChargerCommandTargetVoltage 22685;
BA_ "SPN" SG_ 2554068734 AuxChargerCommandTargetCurrent 22686;
BA_ "SPN" SG_ 2555051774 EvMltCnntnCnCndtnngFlg 22707;
BA_ "SPN" SG_ 2555051774 EvMltCnntnRssCndtnngFlg 22708;
BA_ "SPN" SG_ 2555051774 EvMultiConnectionErrorCode 22709;
BA_ "SPN" SG_ 2555051774 EvMultiConnectionStateOfCharge 22710;
BA_ "SPN" SG_ 2555117310 HrdOrEvMltCnntnDChrgngVltgMxmm 22692;
BA_ "SPN" SG_ 2555117310 HrdOrEvMltCnntnDChrgngCrrntMxmm 22693;
BA_ "SPN" SG_ 2555117310 HrdOrEvMltCnntnDChrgngPwrMxmm 22694;
BA_ "SPN" SG_ 2555117310 HdOEvMtCtRqstdETsTp 22695;
BA_ "SPN" SG_ 2565900286 WirelessChargerSystemState 22724;
BA_ "SPN" SG_ 2565900286 WrlssChrgrPrsntChrgngVltg 22725;
BA_ "SPN" SG_ 2565900286 WrlssChrgrPrsntChrgngCrrnt 22726;
BA_ "SPN" SG_ 2565900286 WirelessChargerDeratingReason 22727;
BA_ "SPN" SG_ 2565900542 WrlssChrgrAlgnmntXQlt 22728;
BA_ "SPN" SG_ 2565900542 WrlssChrgrAlgnmntYQlt 22729;
BA_ "SPN" SG_ 2565900542 WrlssChrgrAlgnmntZQlt 22730;
BA_ "SPN" SG_ 2565900542 WrlssChrgrAlgnmntOvrllQlt 22731;
BA_ "SPN" SG_ 2498819326 DemandedPowerFactor 22738;
BA_ "SPN" SG_ 2498819326 DemandedVoltage 22739;
BA_ "SPN" SG_ 2498819326 SimulatedMainsFrequencyOffset 22740;
BA_ "SPN" SG_ 2498819326 SimulatedMainsFrequencyStatus 22741;
BA_ "SPN" SG_ 2498819326 TstFntnFrThPrttnStts 22742;
BA_ "SPN" SG_ 2498819326 GtUdvtAdOvvtPttTstFtStts 22218;
BA_ "SPN" SG_ 2498819326 GnrtrUtltDplngPrttnTstFntnStts 22219;
BA_ "SPN" SG_ 2498819326 GeneratorFaultRideThroughStatus 22220;
BA_ "SPN" SG_ 2498819326 GnrtrRtvPwrUndrExttnLmtStts 22221;
BA_ "SPN" SG_ 2498819326 GnrtrRtvPwrOvrExttnLmtStts 22222;
BA_ "SPN" SG_ 2364761342 LftTrnsmssnOtptShftDrtnlSpd 22625;
BA_ "SPN" SG_ 2364761342 RghtTrnsmssnOtptShftDrtnlSpd 22626;
BA_ "SPN" SG_ 2566088190 PrplsnMtrClntFn3Vltg 22641;
BA_ "SPN" SG_ 2566088190 PrplsnMtrClntFn3Crrnt 22642;
BA_ "SPN" SG_ 2566088190 PrplsnMtrClntFn3HvlStts 22643;
BA_ "SPN" SG_ 2566088190 PrplsnMtrClntFn3PrntSpdStts 23466;
BA_ "SPN" SG_ 2566088190 PrplsnMtrClntFn3PrntSpd 23467;
BA_ "SPN" SG_ 2566088446 PrplsnMtrClntFn2Vltg 22644;
BA_ "SPN" SG_ 2566088446 PrplsnMtrClntFn2Crrnt 22645;
BA_ "SPN" SG_ 2566088446 PrplsnMtrClntFn2HvlStts 22646;
BA_ "SPN" SG_ 2566088446 PrplsnMtrClntFn2PrntSpdStts 23468;
BA_ "SPN" SG_ 2566088446 PrplsnMtrClntFn2PrntSpd 23469;
BA_ "SPN" SG_ 2566088702 PrplsnMtrClntFn1Vltg 22647;
BA_ "SPN" SG_ 2566088702 PrplsnMtrClntFn1Crrnt 22648;
BA_ "SPN" SG_ 2566088702 PrplsnMtrClntFn1HvlStts 22649;
BA_ "SPN" SG_ 2566088702 PrplsnMtrClntFn1PrntSpdStts 23470;
BA_ "SPN" SG_ 2566088702 PrplsnMtrClntFn1PrntSpd 23471;
BA_ "SPN" SG_ 2566088958 PwrEltrnsClntFn3Vltg 22650;
BA_ "SPN" SG_ 2566088958 PwrEltrnsClntFn3Crrnt 22651;
BA_ "SPN" SG_ 2566088958 PwrEltrnsClntFn3HvlStts 22652;
BA_ "SPN" SG_ 2566088958 PwrEltrnsClntFn3PrntSpdStts 23472;
BA_ "SPN" SG_ 2566088958 PwrEltrnsClntFn3PrntSpd 23473;
BA_ "SPN" SG_ 2566089214 PwrEltrnsClntFn2Vltg 22653;
BA_ "SPN" SG_ 2566089214 PwrEltrnsClntFn2Crrnt 22654;
BA_ "SPN" SG_ 2566089214 PwrEltrnsClntFn2HvlStts 22655;
BA_ "SPN" SG_ 2566089214 PwrEltrnsClntFn2PrntSpdStts 23474;
BA_ "SPN" SG_ 2566089214 PwrEltrnsClntFn2PrntSpd 23475;
BA_ "SPN" SG_ 2566089470 PwrEltrnsClntFn1Vltg 22656;
BA_ "SPN" SG_ 2566089470 PwrEltrnsClntFn1Crrnt 22657;
BA_ "SPN" SG_ 2566089470 PwrEltrnsClntFn1HvlStts 22658;
BA_ "SPN" SG_ 2566089470 PwrEltrnsClntFn1PrntSpdStts 23476;
BA_ "SPN" SG_ 2566089470 PwrEltrnsClntFn1PrntSpd 23477;
BA_ "SPN" SG_ 2566089726 PropulsionMotorOilPumpVoltage 22659;
BA_ "SPN" SG_ 2566089726 PropulsionMotorOilPumpCurrent 22660;
BA_ "SPN" SG_ 2566089726 PrplsnMtrOlPmpHvlStts 22661;
BA_ "SPN" SG_ 2566089726 PrplsnMtrOlPmpPrntSpdStts 23478;
BA_ "SPN" SG_ 2566089726 PrplsnMtrOlPmpPrntSpd 23479;
BA_ "SPN" SG_ 2566089982 PrplsnMtrClntPmpVltg 22662;
BA_ "SPN" SG_ 2566089982 PrplsnMtrClntPmpCrrnt 22663;
BA_ "SPN" SG_ 2566089982 PrplsnMtrClntPmpHvlStts 22664;
BA_ "SPN" SG_ 2566089982 PrplsnMtrClntPmpPrntSpdStts 23480;
BA_ "SPN" SG_ 2566089982 PrplsnMtrClntPmpPrntSpd 23481;
BA_ "SPN" SG_ 2566090238 PwrEltrnsClntPmpVltg 22665;
BA_ "SPN" SG_ 2566090238 PwrEltrnsClntPmpCrrnt 22666;
BA_ "SPN" SG_ 2566090238 PwrEltrnsClntPmpHvlStts 22667;
BA_ "SPN" SG_ 2566090238 PwrEltrnsClntPmpPrntSpdStts 23482;
BA_ "SPN" SG_ 2566090238 PwrEltrnsClntPmpPrntSpd 23483;
BA_ "SPN" SG_ 2566090494 GeneratorCoolantPumpVoltage 22668;
BA_ "SPN" SG_ 2566090494 GeneratorCoolantPumpCurrent 22669;
BA_ "SPN" SG_ 2566090494 GeneratorCoolantPumpHvilStatus 22670;
BA_ "SPN" SG_ 2566090494 GnrtrClntPmpPrntSpdStts 23484;
BA_ "SPN" SG_ 2566090494 GnrtrClntPmpPrntSpd 23485;
BA_ "SPN" SG_ 2566090750 GeneratorCoolantFanVoltage 22671;
BA_ "SPN" SG_ 2566090750 GeneratorCoolantFanCurrent 22672;
BA_ "SPN" SG_ 2566090750 GeneratorCoolantFanHvilStatus 22673;
BA_ "SPN" SG_ 2566090750 GnrtrClntFnPrntSpdStts 23486;
BA_ "SPN" SG_ 2566090750 GeneratorCoolantFanPercentSpeed 23487;
BA_ "SPN" SG_ 2566091006 EltrfdAssrMtrVltg 22674;
BA_ "SPN" SG_ 2566091006 EltrfdAssrMtrCrrnt 22675;
BA_ "SPN" SG_ 2566091006 EltrfdAssrMtrHvlStts 22676;
BA_ "SPN" SG_ 2566091006 EltrfdAssrMtrInstnOfSttsDtSt2 22677;
BA_ "SPN" SG_ 2566091006 EltrfdAssrMtrPrntSpdStts 23488;
BA_ "SPN" SG_ 2566091006 EltrfdAssrMtrPrntSpd 23489;
BA_ "SPN" SG_ 2633637886 Aftertreatment2DefDosingMode 22719;
BA_ "SPN" SG_ 2566529278 Evmcdclim2ExtendedId 22696;
BA_ "SPN" SG_ 2566529278 EvMltCnntnBlkSttOfChrg 22697;
BA_ "SPN" SG_ 2566529278 EvMltCnntnFllSttOfChrg 22698;
BA_ "SPN" SG_ 2566529278 EvMultiConnectionEnergyCapacity 22699;
BA_ "SPN" SG_ 2566529278 EvMltCnntnEnrgRqstd 22700;
BA_ "SPN" SG_ 2566529534 EvmcdccipExtendedId 22701;
BA_ "SPN" SG_ 2566529534 EvMltCnntnBlkChrgngCmplt 22702;
BA_ "SPN" SG_ 2566529534 EvMltCnntnFllChrgngCmplt 22703;
BA_ "SPN" SG_ 2566529534 EvMltCnntnBlkChrgTmRmnng 22704;
BA_ "SPN" SG_ 2566529534 EvMltCnntnFllChrgTmRmnng 22705;
BA_ "SPN" SG_ 2566529534 EvMultiConnectionDepartureTime 22706;
